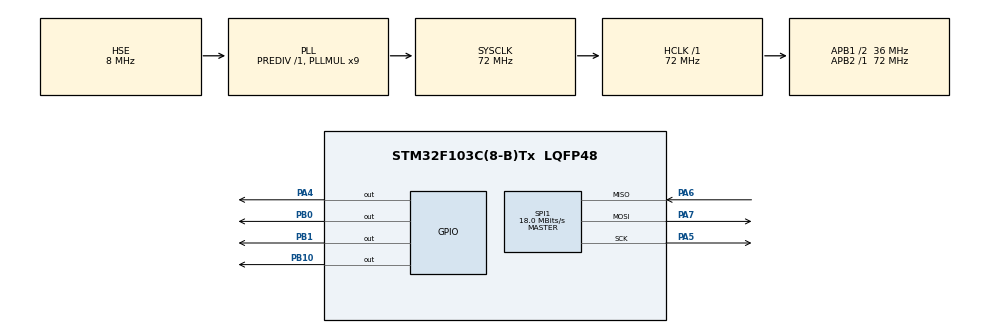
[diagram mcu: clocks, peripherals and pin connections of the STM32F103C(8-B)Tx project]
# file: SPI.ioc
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Dma.Request0=SPI1_TX
Dma.SPI1_TX.0.Direction=DMA_MEMORY_TO_PERIPH
Dma.SPI1_TX.0.Instance=DMA1_Channel3
Dma.SPI1_TX.0.MemDataAlignment=DMA_MDATAALIGN_BYTE
Dma.SPI1_TX.0.MemInc=DMA_MINC_ENABLE
Dma.SPI1_TX.0.Mode=DMA_NORMAL
Dma.SPI1_TX.0.PeriphDataAlignment=DMA_PDATAALIGN_BYTE
Dma.SPI1_TX.0.PeriphInc=DMA_PINC_DISABLE
Dma.SPI1_TX.0.Priority=DMA_PRIORITY_LOW
Mcu.Family=STM32F1
Mcu.Name=STM32F103C(8-B)Tx
Mcu.Package=LQFP48
NVIC.DMA1_Channel3_IRQn=true\:0\:0\:false\:false\:true\:false\:true\:true
NVIC.PriorityGroup=NVIC_PRIORITYGROUP_4
NVIC.SPI1_IRQn=true\:0\:0\:false\:false\:true\:true\:true\:true
PA13.Mode=Serial_Wire
PA13.Signal=SYS_JTMS-SWDIO
PA14.Mode=Serial_Wire
PA14.Signal=SYS_JTCK-SWCLK
PA4.Signal=GPIO_Output
PA5.Mode=Full_Duplex_Master
PA5.Signal=SPI1_SCK
PA6.Mode=Full_Duplex_Master
PA6.Signal=SPI1_MISO
PA7.Mode=Full_Duplex_Master
PA7.Signal=SPI1_MOSI
PB0.Signal=GPIO_Output
PB1.Signal=GPIO_Output
PB10.Signal=GPIO_Output
PC14-OSC32_IN.Mode=LSE-External-Oscillator
PC14-OSC32_IN.Signal=RCC_OSC32_IN
PC15-OSC32_OUT.Mode=LSE-External-Oscillator
PC15-OSC32_OUT.Signal=RCC_OSC32_OUT
PD0-OSC_IN.Mode=HSE-External-Oscillator
PD0-OSC_IN.Signal=RCC_OSC_IN
PD1-OSC_OUT.Mode=HSE-External-Oscillator
PD1-OSC_OUT.Signal=RCC_OSC_OUT
ProjectManager.HeapSize=0x200
ProjectManager.StackSize=0x400
ProjectManager.TargetToolchain=MDK-ARM V5.32
RCC.AHBFreq_Value=72000000
RCC.APB1CLKDivider=RCC_HCLK_DIV2
RCC.APB1Freq_Value=36000000
RCC.APB1TimFreq_Value=72000000
RCC.APB2Freq_Value=72000000
RCC.APB2TimFreq_Value=72000000
RCC.HCLKFreq_Value=72000000
RCC.PLLMUL=RCC_PLL_MUL9
RCC.PLLSourceVirtual=RCC_PLLSOURCE_HSE
RCC.SYSCLKFreq_VALUE=72000000
RCC.SYSCLKSource=RCC_SYSCLKSOURCE_PLLCLK
RCC.USBFreq_Value=72000000
SPI1.BaudRatePrescaler=SPI_BAUDRATEPRESCALER_4
SPI1.CalculateBaudRate=18.0 MBits/s
SPI1.Direction=SPI_DIRECTION_2LINES
SPI1.Mode=SPI_MODE_MASTER
SPI1.VirtualType=VM_MASTER
board=custom

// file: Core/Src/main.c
/* USER CODE BEGIN Header */
/**
  ******************************************************************************
  * @file           : main.c
  * @brief          : Main program body
  ******************************************************************************
  * @attention
  *
  * Copyright (c) 2026 STMicroelectronics.
  * All rights reserved.
  *
  * This software is licensed under terms that can be found in the LICENSE file
  * in the root directory of this software component.
  * If no LICENSE file comes with this software, it is provided AS-IS.
  *
  ******************************************************************************
  */
/* USER CODE END Header */
#include "main.h"

/* USER CODE BEGIN Includes */
#include <stdio.h>
#include <math.h>
#include <st7735.h>
/* USER CODE END Includes */

SPI_HandleTypeDef hspi1;
DMA_HandleTypeDef hdma_spi1_tx;

void SystemClock_Config(void);
static void MX_GPIO_Init(void);
static void MX_DMA_Init(void);
static void MX_SPI1_Init(void);

/* USER CODE BEGIN 0 */

// 80 x 106, 16960 bytes
// Pixel format: RGB565
// Algorithm: Floyd Steinberg
// Generated by img2lcd.com
static const unsigned char IMAGE[] = {
  0x2a, 0x50, 0x2a, 0x70, 0x2a, 0x70, 0x2a, 0x70, 0x2a, 0x70, 0x2a, 0x70, 0x2a, 0x70, 0x2a, 0x70,
  0x2a, 0x70, 0x2a, 0x70, 0x2a, 0x70, 0x2a, 0x70, 0x2a, 0x70, 0x2a, 0x70, 0x2a, 0x70, 0x2a, 0x70,
  0x2a, 0x70, 0x2a, 0x70, 0x2a, 0x70, 0x2a, 0x70, 0x2a, 0x70, 0x2a, 0x70, 0x2a, 0x70, 0x2a, 0x70,
  0x2a, 0x70, 0x2a, 0x70, 0x2a, 0x70, 0x2a, 0x70, 0x2a, 0x70, 0x2a, 0x70, 0x2a, 0x70, 0x2a, 0x70,
  0x2a, 0x70, 0x2a, 0x70, 0x2a, 0x70, 0x2a, 0x70, 0x2a, 0x70, 0x2a, 0x70, 0x2a, 0x70, 0x2a, 0x70,
  0x2a, 0x70, 0x2a, 0x70, 0x2a, 0x70, 0x2a, 0x70, 0x2a, 0x70, 0x2a, 0x70, 0x2a, 0x70, 0x2a, 0x70,
  0x2a, 0x70, 0x2a, 0x70, 0x2a, 0x70, 0x2a, 0x70, 0x2a, 0x70, 0x2a, 0x70, 0x2a, 0x70, 0x2a, 0x70,
  0x2a, 0x70, 0x2a, 0x70, 0x2a, 0x70, 0x2a, 0x70, 0x2a, 0x70, 0x2a, 0x70, 0x2a, 0x70, 0x2a, 0x70,
  0x2a, 0x70, 0x2a, 0x70, 0x2a, 0x70, 0x2a, 0x70, 0x2a, 0x70, 0x2a, 0x70, 0x2a, 0x70, 0x2a, 0x70,
  0x2a, 0x70, 0x2a, 0x70, 0x2a, 0x70, 0x2a, 0x70, 0x2a, 0x70, 0x2a, 0x70, 0x2a, 0x70, 0x2a, 0x70,
  0x2a, 0x70, 0x2a, 0x70, 0x2a, 0x70, 0x2a, 0x70, 0x2a, 0x70, 0x2a, 0x70, 0x2a, 0x70, 0x2a, 0x70,
  0x2a, 0x70, 0x2a, 0x70, 0x2a, 0x70, 0x2a, 0x70, 0x2a, 0x70, 0x2a, 0x70, 0x2a, 0x70, 0x2a, 0x70,
  0x2a, 0x70, 0x2a, 0x70, 0x2a, 0x70, 0x8c, 0xd7, 0x6c, 0x15, 0xff, 0xff, 0xff, 0xff, 0xff, 0xff,
  0xff, 0xff, 0xff, 0xff, 0xff, 0xff, 0xff, 0xff, 0xff, 0xff, 0xff, 0xff, 0xff, 0xff, 0xff, 0xff,
  0xff, 0xff, 0xff, 0xff, 0xff, 0xff, 0xff, 0xff, 0xff, 0xff, 0xff, 0xff, 0xff, 0xff, 0xff, 0xff,
  0xff, 0xff, 0xff, 0xff, 0xff, 0xff, 0xff, 0xff, 0xff, 0xff, 0xff, 0xff, 0xff, 0xff, 0xff, 0xff,
  0xff, 0xff, 0xff, 0xff, 0xff, 0xff, 0xff, 0xff, 0xff, 0xff, 0xff, 0xff, 0xff, 0xff, 0xff, 0xff,
  0xff, 0xff, 0xff, 0xff, 0xff, 0xff, 0xff, 0xff, 0xff, 0xff, 0xff, 0xff, 0xff, 0xff, 0xff, 0xff,
  0xff, 0xff, 0xff, 0xff, 0xff, 0xff, 0xff, 0xff, 0xff, 0xff, 0xff, 0xff, 0xff, 0xff, 0xff, 0xff,
  0xff, 0xff, 0xff, 0xff, 0xff, 0xff, 0xff, 0xff, 0xff, 0xff, 0xff, 0xff, 0xff, 0xff, 0xff, 0xff,
  0xff, 0xff, 0xff, 0xff, 0xff, 0xff, 0xff, 0xff, 0xff, 0xff, 0xff, 0xff, 0xff, 0xff, 0xff, 0xff,
  0xff, 0xff, 0xff, 0xff, 0xff, 0xff, 0xff, 0xff, 0xff, 0xff, 0xff, 0xff, 0xff, 0xff, 0xff, 0xff,
  0xff, 0xff, 0xff, 0xff, 0xff, 0xff, 0xff, 0xff, 0xff, 0xff, 0xff, 0xff, 0xff, 0xff, 0xff, 0xff,
  0xff, 0xff, 0xff, 0xff, 0xff, 0xff, 0xff, 0xff, 0xff, 0xff, 0xff, 0xff, 0xff, 0xff, 0xff, 0xff,
  0xff, 0xff, 0xff, 0xff, 0xff, 0xff, 0xff, 0xff, 0xff, 0xff, 0xff, 0xff, 0xff, 0xff, 0x84, 0xb6,
  0x6c, 0x15, 0xff, 0xff, 0xff, 0xff, 0xff, 0xff, 0xff, 0xff, 0xff, 0xff, 0xff, 0xff, 0xff, 0xff,
  0xff, 0xff, 0xff, 0xff, 0xff, 0xff, 0xff, 0xff, 0xff, 0xff, 0xff, 0xff, 0xff, 0xff, 0xff, 0xff,
  0xff, 0xff, 0xff, 0xff, 0xff, 0xff, 0xff, 0xff, 0xff, 0xff, 0xff, 0xff, 0xff, 0xff, 0xff, 0xff,
  0xff, 0xff, 0xff, 0xff, 0xff, 0xff, 0xff, 0xff, 0xff, 0xff, 0xff, 0xff, 0xff, 0xff, 0xff, 0xff,
  0xff, 0xff, 0xff, 0xff, 0xff, 0xff, 0xff, 0xff, 0xff, 0xff, 0xff, 0xff, 0xff, 0xff, 0xff, 0xff,
  0xff, 0xff, 0xff, 0xff, 0xff, 0xff, 0xff, 0xff, 0xff, 0xff, 0xff, 0xff, 0xff, 0xff, 0xff, 0xff,
  0xff, 0xff, 0xff, 0xff, 0xff, 0xff, 0xff, 0xff, 0xff, 0xff, 0xff, 0xff, 0xff, 0xff, 0xff, 0xff,
  0xff, 0xff, 0xff, 0xff, 0xff, 0xff, 0xff, 0xff, 0xff, 0xff, 0xff, 0xff, 0xff, 0xff, 0xff, 0xff,
  0xff, 0xff, 0xff, 0xff, 0xff, 0xff, 0xff, 0xff, 0xff, 0xff, 0xff, 0xff, 0xff, 0xff, 0xff, 0xff,
  0xff, 0xff, 0xff, 0xff, 0xff, 0xff, 0xff, 0xff, 0xff, 0xff, 0xff, 0xff, 0xff, 0xff, 0xff, 0xff,
  0xff, 0xff, 0xff, 0xff, 0xff, 0xff, 0xff, 0xff, 0xff, 0xff, 0xff, 0xff, 0xff, 0xff, 0xff, 0xff,
  0xff, 0xff, 0xff, 0xff, 0xff, 0xff, 0xff, 0xff, 0xff, 0xff, 0xff, 0xff, 0xff, 0xff, 0xff, 0xff,
  0xff, 0xff, 0xff, 0xff, 0xff, 0xff, 0x84, 0xb6, 0x6c, 0x15, 0xff, 0xff, 0xff, 0xff, 0x10, 0x82,
  0x10, 0x82, 0x10, 0x82, 0x10, 0x82, 0x10, 0x82, 0x10, 0x82, 0x10, 0x82, 0x10, 0x82, 0x10, 0x82,
  0x10, 0x82, 0x10, 0x82, 0x10, 0x82, 0x10, 0x82, 0x10, 0x82, 0x10, 0x82, 0x10, 0x82, 0x10, 0x82,
  0x10, 0x82, 0x10, 0x82, 0x29, 0x65, 0xff, 0xff, 0xff, 0xff, 0xff, 0xff, 0xff, 0xff, 0xff, 0xff,
  0x6b, 0x6d, 0x10, 0x82, 0x10, 0x82, 0xf7, 0xbe, 0xff, 0xff, 0xff, 0xff, 0xff, 0xff, 0xff, 0xff,
  0xff, 0xff, 0x10, 0x82, 0x10, 0x82, 0x21, 0x24, 0xff, 0xff, 0xff, 0xff, 0x73, 0x8e, 0x10, 0x82,
  0x10, 0x82, 0xd6, 0xba, 0xff, 0xff, 0xff, 0xff, 0xff, 0xff, 0xff, 0xff, 0xff, 0xff, 0xff, 0xff,
  0xff, 0xff, 0xff, 0xff, 0xff, 0xff, 0xff, 0xff, 0xff, 0xff, 0xff, 0xff, 0xff, 0xff, 0xff, 0xff,
  0xff, 0xff, 0xff, 0xff, 0xff, 0xff, 0xff, 0xff, 0xff, 0xff, 0x10, 0x82, 0x10, 0x82, 0x10, 0x82,
  0x10, 0x82, 0x10, 0x82, 0x31, 0xa6, 0xff, 0xff, 0xff, 0xff, 0xff, 0xff, 0xff, 0xff, 0xff, 0xff,
  0x63, 0x0c, 0x10, 0x82, 0x10, 0x82, 0x10, 0x82, 0x10, 0x82, 0x10, 0x82, 0x10, 0x82, 0x10, 0x82,
  0x10, 0x82, 0x10, 0x82, 0x10, 0x82, 0x10, 0x82, 0x10, 0x82, 0x10, 0x82, 0x10, 0x82, 0x10, 0x82,
  0x10, 0x82, 0x10, 0x82, 0x10, 0x82, 0x10, 0x82, 0xff, 0xdf, 0xff, 0xff, 0xff, 0xff, 0x84, 0xb6,
  0x6c, 0x15, 0xff, 0xff, 0xff, 0xff, 0x00, 0x00, 0x00, 0x00, 0x00, 0x00, 0x00, 0x00, 0x00, 0x00,
  0x00, 0x00, 0x00, 0x00, 0x00, 0x00, 0x00, 0x00, 0x00, 0x00, 0x00, 0x00, 0x00, 0x00, 0x00, 0x00,
  0x00, 0x00, 0x00, 0x00, 0x00, 0x00, 0x00, 0x00, 0x00, 0x00, 0x00, 0x00, 0x18, 0xe3, 0xff, 0xff,
  0xff, 0xff, 0xff, 0xff, 0xff, 0xff, 0xff, 0xff, 0x63, 0x0c, 0x00, 0x00, 0x00, 0x00, 0xf7, 0x9e,
  0xff, 0xff, 0xff, 0xff, 0xff, 0xff, 0xff, 0xff, 0xff, 0xff, 0x00, 0x00, 0x00, 0x00, 0x18, 0xc3,
  0xff, 0xff, 0xff, 0xff, 0x63, 0x2c, 0x00, 0x00, 0x00, 0x00, 0xd6, 0x9a, 0xff, 0xff, 0xff, 0xff,
  0xff, 0xff, 0xff, 0xff, 0xff, 0xff, 0xff, 0xff, 0xff, 0xff, 0xff, 0xff, 0xff, 0xff, 0xff, 0xff,
  0xff, 0xff, 0xff, 0xff, 0xff, 0xff, 0xff, 0xff, 0xff, 0xff, 0xff, 0xff, 0xff, 0xff, 0xff, 0xff,
  0xff, 0xff, 0x00, 0x00, 0x00, 0x00, 0x00, 0x00, 0x00, 0x00, 0x00, 0x00, 0x21, 0x24, 0xff, 0xff,
  0xff, 0xff, 0xff, 0xff, 0xff, 0xff, 0xff, 0xff, 0x52, 0xaa, 0x00, 0x00, 0x00, 0x00, 0x00, 0x00,
  0x00, 0x00, 0x00, 0x00, 0x00, 0x00, 0x00, 0x00, 0x00, 0x00, 0x00, 0x00, 0x00, 0x00, 0x00, 0x00,
  0x00, 0x00, 0x00, 0x00, 0x00, 0x00, 0x00, 0x00, 0x00, 0x00, 0x00, 0x00, 0x00, 0x00, 0x00, 0x00,
  0xff, 0xdf, 0xff, 0xff, 0xff, 0xff, 0x84, 0xb6, 0x6c, 0x15, 0xff, 0xff, 0xff, 0xff, 0x00, 0x00,
  0x00, 0x00, 0x00, 0x00, 0x00, 0x00, 0x00, 0x00, 0x00, 0x00, 0x00, 0x00, 0x00, 0x00, 0x00, 0x00,
  0x00, 0x00, 0x00, 0x00, 0x00, 0x00, 0x00, 0x00, 0x00, 0x00, 0x00, 0x00, 0x00, 0x00, 0x00, 0x00,
  0x00, 0x00, 0x00, 0x00, 0x18, 0xe3, 0xff, 0xff, 0xff, 0xff, 0xff, 0xff, 0xff, 0xff, 0xff, 0xff,
  0x63, 0x0c, 0x00, 0x00, 0x00, 0x00, 0xf7, 0x9e, 0xff, 0xff, 0xff, 0xff, 0xff, 0xff, 0xff, 0xff,
  0xff, 0xff, 0x00, 0x00, 0x00, 0x00, 0x18, 0xc3, 0xff, 0xff, 0xff, 0xff, 0x63, 0x2c, 0x00, 0x00,
  0x00, 0x00, 0xd6, 0x9a, 0xff, 0xff, 0xff, 0xff, 0xff, 0xff, 0xff, 0xff, 0xff, 0xff, 0xff, 0xff,
  0xff, 0xff, 0xff, 0xff, 0xff, 0xff, 0xff, 0xff, 0xff, 0xff, 0xff, 0xff, 0xff, 0xff, 0xff, 0xff,
  0xff, 0xff, 0xff, 0xff, 0xff, 0xff, 0xff, 0xff, 0xff, 0xff, 0x00, 0x00, 0x00, 0x00, 0x00, 0x00,
  0x00, 0x00, 0x00, 0x00, 0x21, 0x24, 0xff, 0xff, 0xff, 0xff, 0xff, 0xff, 0xff, 0xff, 0xff, 0xff,
  0x52, 0xaa, 0x00, 0x00, 0x00, 0x00, 0x00, 0x00, 0x00, 0x00, 0x00, 0x00, 0x00, 0x00, 0x00, 0x00,
  0x00, 0x00, 0x00, 0x00, 0x00, 0x00, 0x00, 0x00, 0x00, 0x00, 0x00, 0x00, 0x00, 0x00, 0x00, 0x00,
  0x00, 0x00, 0x00, 0x00, 0x00, 0x00, 0x00, 0x00, 0xff, 0xdf, 0xff, 0xff, 0xff, 0xff, 0x84, 0xb6,
  0x6c, 0x15, 0xff, 0xff, 0xff, 0xff, 0x00, 0x00, 0x00, 0x00, 0x08, 0x41, 0xff, 0xff, 0xff, 0xff,
  0xff, 0xff, 0xff, 0xff, 0xff, 0xff, 0xff, 0xff, 0xff, 0xff, 0xff, 0xff, 0xff, 0xff, 0xff, 0xff,
  0xff, 0xff, 0xff, 0xff, 0xff, 0xff, 0xff, 0xff, 0x00, 0x00, 0x00, 0x00, 0x18, 0xe3, 0xff, 0xff,
  0xff, 0xff, 0xff, 0xff, 0xff, 0xff, 0xff, 0xff, 0xff, 0xff, 0xff, 0xff, 0xff, 0xff, 0x08, 0x61,
  0x00, 0x00, 0x00, 0x00, 0x00, 0x00, 0x00, 0x00, 0x00, 0x00, 0x00, 0x00, 0x00, 0x00, 0x00, 0x00,
  0x00, 0x00, 0x00, 0x00, 0x00, 0x00, 0x00, 0x00, 0x00, 0x00, 0xd6, 0x9a, 0xff, 0xff, 0xff, 0xff,
  0x00, 0x20, 0x00, 0x00, 0x00, 0x00, 0xff, 0xff, 0xff, 0xff, 0xf7, 0xbe, 0x00, 0x00, 0x00, 0x00,
  0x00, 0x00, 0x00, 0x00, 0x00, 0x00, 0x9c, 0xf3, 0xff, 0xff, 0xff, 0xff, 0x10, 0x82, 0x00, 0x00,
  0x00, 0x00, 0xff, 0xff, 0xff, 0xff, 0xff, 0xff, 0xff, 0xff, 0xff, 0xff, 0xff, 0xff, 0xff, 0xff,
  0xff, 0xff, 0xff, 0xff, 0xff, 0xff, 0xff, 0xff, 0x52, 0xaa, 0x00, 0x00, 0x00, 0x00, 0xf7, 0x9e,
  0xff, 0xff, 0xff, 0xff, 0xff, 0xff, 0xff, 0xff, 0xff, 0xff, 0xff, 0xff, 0xff, 0xff, 0xff, 0xff,
  0xff, 0xff, 0xff, 0xff, 0xff, 0xff, 0xff, 0xff, 0xff, 0xff, 0x29, 0x45, 0x00, 0x00, 0x00, 0x00,
  0xff, 0xdf, 0xff, 0xff, 0xff, 0xff, 0x84, 0xb6, 0x6c, 0x15, 0xff, 0xff, 0xff, 0xff, 0x00, 0x00,
  0x00, 0x00, 0x08, 0x41, 0xff, 0xff, 0xff, 0xff, 0xff, 0xff, 0xff, 0xff, 0xff, 0xff, 0xff, 0xff,
  0xff, 0xff, 0xff, 0xff, 0xff, 0xff, 0xff, 0xff, 0xff, 0xff, 0xff, 0xff, 0xff, 0xff, 0xff, 0xff,
  0x00, 0x00, 0x00, 0x00, 0x18, 0xe3, 0xff, 0xff, 0xff, 0xff, 0xff, 0xff, 0xff, 0xff, 0xff, 0xff,
  0xff, 0xff, 0xff, 0xff, 0xff, 0xff, 0x08, 0x61, 0x00, 0x00, 0x00, 0x00, 0x00, 0x00, 0x00, 0x00,
  0x00, 0x00, 0x00, 0x00, 0x00, 0x00, 0x00, 0x00, 0x00, 0x00, 0x00, 0x00, 0x00, 0x00, 0x00, 0x00,
  0x00, 0x00, 0xd6, 0x9a, 0xff, 0xff, 0xff, 0xff, 0x00, 0x20, 0x00, 0x00, 0x00, 0x00, 0xff, 0xff,
  0xff, 0xff, 0xf7, 0xbe, 0x00, 0x00, 0x00, 0x00, 0x00, 0x00, 0x00, 0x00, 0x00, 0x00, 0x9c, 0xf3,
  0xff, 0xff, 0xff, 0xff, 0x10, 0x82, 0x00, 0x00, 0x00, 0x00, 0xff, 0xff, 0xff, 0xff, 0xff, 0xff,
  0xff, 0xff, 0xff, 0xff, 0xff, 0xff, 0xff, 0xff, 0xff, 0xff, 0xff, 0xff, 0xff, 0xff, 0xff, 0xff,
  0x52, 0xaa, 0x00, 0x00, 0x00, 0x00, 0xf7, 0x9e, 0xff, 0xff, 0xff, 0xff, 0xff, 0xff, 0xff, 0xff,
  0xff, 0xff, 0xff, 0xff, 0xff, 0xff, 0xff, 0xff, 0xff, 0xff, 0xff, 0xff, 0xff, 0xff, 0xff, 0xff,
  0xff, 0xff, 0x29, 0x45, 0x00, 0x00, 0x00, 0x00, 0xff, 0xdf, 0xff, 0xff, 0xff, 0xff, 0x84, 0xb6,
  0x6c, 0x15, 0xff, 0xff, 0xff, 0xff, 0x00, 0x00, 0x00, 0x00, 0x08, 0x41, 0xff, 0xff, 0xff, 0xff,
  0xff, 0xff, 0xff, 0xdf, 0xff, 0xdf, 0xff, 0xdf, 0xff, 0xdf, 0xff, 0xdf, 0xff, 0xdf, 0xff, 0xdf,
  0xff, 0xdf, 0xff, 0xff, 0xff, 0xff, 0xff, 0xff, 0x00, 0x00, 0x00, 0x00, 0x18, 0xe3, 0xff, 0xff,
  0xff, 0xff, 0xff, 0xff, 0xff, 0xdf, 0xff, 0xdf, 0xff, 0xdf, 0xff, 0xdf, 0xff, 0xdf, 0x08, 0x61,
  0x00, 0x00, 0x00, 0x00, 0x00, 0x00, 0x00, 0x00, 0x00, 0x00, 0x00, 0x00, 0x00, 0x00, 0x00, 0x00,
  0x00, 0x00, 0x00, 0x00, 0x00, 0x00, 0x00, 0x00, 0x00, 0x00, 0xd6, 0x9a, 0xff, 0xff, 0xff, 0xff,
  0x00, 0x20, 0x00, 0x00, 0x00, 0x00, 0xff, 0xdf, 0xff, 0xdf, 0xf7, 0x9e, 0x00, 0x00, 0x00, 0x00,
  0x00, 0x00, 0x00, 0x00, 0x00, 0x00, 0x9c, 0xd3, 0xff, 0xdf, 0xff, 0xdf, 0x10, 0xa2, 0x00, 0x00,
  0x00, 0x00, 0xff, 0xdf, 0xff, 0xdf, 0xff, 0xdf, 0xff, 0xff, 0xff, 0xff, 0xff, 0xff, 0xff, 0xff,
  0xff, 0xff, 0xff, 0xff, 0xff, 0xff, 0xff, 0xff, 0x52, 0xaa, 0x00, 0x00, 0x00, 0x00, 0xf7, 0x9e,
  0xff, 0xff, 0xff, 0xff, 0xff, 0xdf, 0xff, 0xdf, 0xff, 0xdf, 0xff, 0xdf, 0xff, 0xdf, 0xff, 0xdf,
  0xff, 0xdf, 0xff, 0xdf, 0xff, 0xff, 0xff, 0xff, 0xff, 0xff, 0x29, 0x45, 0x00, 0x00, 0x00, 0x00,
  0xff, 0xdf, 0xff, 0xff, 0xff, 0xff, 0x84, 0xb6, 0x6c, 0x15, 0xff, 0xff, 0xff, 0xff, 0x00, 0x00,
  0x00, 0x00, 0x08, 0x41, 0xff, 0xff, 0xff, 0xff, 0xde, 0xfb, 0x00, 0x00, 0x00, 0x00, 0x00, 0x00,
  0x00, 0x00, 0x00, 0x00, 0x00, 0x00, 0x00, 0x00, 0x00, 0x00, 0xff, 0xdf, 0xff, 0xff, 0xff, 0xff,
  0x00, 0x00, 0x00, 0x00, 0x18, 0xe3, 0xff, 0xff, 0xff, 0xff, 0x8c, 0x51, 0x00, 0x00, 0x00, 0x00,
  0x00, 0x00, 0x00, 0x00, 0x00, 0x00, 0x00, 0x00, 0x00, 0x00, 0x00, 0x00, 0xff, 0xdf, 0xff, 0xff,
  0xff, 0xff, 0x00, 0x00, 0x00, 0x00, 0x00, 0x00, 0x00, 0x00, 0x00, 0x00, 0x94, 0xb2, 0xff, 0xff,
  0xff, 0xff, 0xff, 0xff, 0xff, 0xff, 0xff, 0xff, 0x00, 0x20, 0x00, 0x00, 0x00, 0x00, 0x00, 0x00,
  0x00, 0x00, 0x00, 0x00, 0x00, 0x00, 0x00, 0x00, 0x00, 0x00, 0x00, 0x00, 0x00, 0x00, 0x00, 0x00,
  0x00, 0x00, 0x00, 0x00, 0xef, 0x5d, 0xff, 0xff, 0xff, 0xff, 0x00, 0x00, 0x00, 0x00, 0x00, 0x20,
  0xff, 0xff, 0xff, 0xff, 0xff, 0xff, 0xff, 0xff, 0xff, 0xff, 0xff, 0xff, 0xff, 0xff, 0xff, 0xff,
  0x52, 0xaa, 0x00, 0x00, 0x00, 0x00, 0xf7, 0x9e, 0xff, 0xff, 0xff, 0xff, 0x00, 0x00, 0x00, 0x00,
  0x00, 0x00, 0x00, 0x00, 0x00, 0x00, 0x00, 0x00, 0x00, 0x00, 0x00, 0x00, 0xa5, 0x34, 0xff, 0xff,
  0xff, 0xff, 0x29, 0x45, 0x00, 0x00, 0x00, 0x00, 0xff, 0xdf, 0xff, 0xff, 0xff, 0xff, 0x84, 0xb6,
  0x6c, 0x15, 0xff, 0xff, 0xff, 0xff, 0x00, 0x00, 0x00, 0x00, 0x08, 0x41, 0xff, 0xff, 0xff, 0xff,
  0xde, 0xfb, 0x00, 0x00, 0x00, 0x00, 0x00, 0x00, 0x00, 0x00, 0x00, 0x00, 0x00, 0x00, 0x00, 0x00,
  0x00, 0x00, 0xff, 0xdf, 0xff, 0xff, 0xff, 0xff, 0x00, 0x00, 0x00, 0x00, 0x18, 0xe3, 0xff, 0xff,
  0xff, 0xff, 0x8c, 0x51, 0x00, 0x00, 0x00, 0x00, 0x00, 0x00, 0x00, 0x00, 0x00, 0x00, 0x00, 0x00,
  0x00, 0x00, 0x00, 0x00, 0xff, 0xdf, 0xff, 0xff, 0xff, 0xff, 0x00, 0x00, 0x00, 0x00, 0x00, 0x00,
  0x00, 0x00, 0x00, 0x00, 0x94, 0xb2, 0xff, 0xff, 0xff, 0xff, 0xff, 0xff, 0xff, 0xff, 0xff, 0xff,
  0x00, 0x20, 0x00, 0x00, 0x00, 0x00, 0x00, 0x00, 0x00, 0x00, 0x00, 0x00, 0x00, 0x00, 0x00, 0x00,
  0x00, 0x00, 0x00, 0x00, 0x00, 0x00, 0x00, 0x00, 0x00, 0x00, 0x00, 0x00, 0xef, 0x5d, 0xff, 0xff,
  0xff, 0xff, 0x00, 0x00, 0x00, 0x00, 0x00, 0x20, 0xff, 0xff, 0xff, 0xff, 0xff, 0xff, 0xff, 0xff,
  0xff, 0xff, 0xff, 0xff, 0xff, 0xff, 0xff, 0xff, 0x52, 0xaa, 0x00, 0x00, 0x00, 0x00, 0xf7, 0x9e,
  0xff, 0xff, 0xff, 0xff, 0x00, 0x00, 0x00, 0x00, 0x00, 0x00, 0x00, 0x00, 0x00, 0x00, 0x00, 0x00,
  0x00, 0x00, 0x00, 0x00, 0xa5, 0x34, 0xff, 0xff, 0xff, 0xff, 0x29, 0x45, 0x00, 0x00, 0x00, 0x00,
  0xff, 0xdf, 0xff, 0xff, 0xff, 0xff, 0x84, 0xb6, 0x6c, 0x15, 0xff, 0xff, 0xff, 0xff, 0x00, 0x00,
  0x00, 0x00, 0x08, 0x41, 0xff, 0xff, 0xff, 0xff, 0xde, 0xfb, 0x00, 0x00, 0x00, 0x00, 0x00, 0x00,
  0x00, 0x00, 0x00, 0x00, 0x00, 0x00, 0x00, 0x00, 0x00, 0x00, 0xff, 0xdf, 0xff, 0xff, 0xff, 0xff,
  0x00, 0x00, 0x00, 0x00, 0x18, 0xe3, 0xff, 0xff, 0xff, 0xff, 0x94, 0xb2, 0x18, 0xc3, 0x18, 0xc3,
  0x08, 0x41, 0x00, 0x00, 0x00, 0x00, 0x00, 0x00, 0x00, 0x00, 0x00, 0x00, 0xde, 0xfb, 0xe7, 0x3c,
  0xe7, 0x3c, 0x18, 0xc3, 0x18, 0xc3, 0x18, 0xc3, 0x00, 0x00, 0x00, 0x00, 0x84, 0x30, 0xe7, 0x3c,
  0xe7, 0x1c, 0xe7, 0x3c, 0xe7, 0x3c, 0xe7, 0x3c, 0x18, 0xe3, 0x18, 0xc3, 0x18, 0xc3, 0x18, 0xc3,
  0x18, 0xc3, 0x18, 0xc3, 0x18, 0xc3, 0x18, 0xc3, 0x10, 0xa2, 0x00, 0x00, 0x00, 0x00, 0x10, 0x82,
  0x18, 0xc3, 0x18, 0xc3, 0xd6, 0x9a, 0xe7, 0x1c, 0xe7, 0x3c, 0x18, 0xc3, 0x18, 0xc3, 0x21, 0x04,
  0xff, 0xff, 0xff, 0xff, 0xff, 0xff, 0xff, 0xff, 0xff, 0xff, 0xff, 0xff, 0xff, 0xff, 0xff, 0xff,
  0x52, 0xaa, 0x00, 0x00, 0x00, 0x00, 0xf7, 0x9e, 0xff, 0xff, 0xff, 0xff, 0x00, 0x00, 0x00, 0x00,
  0x00, 0x00, 0x00, 0x00, 0x00, 0x00, 0x00, 0x00, 0x00, 0x00, 0x00, 0x00, 0xa5, 0x34, 0xff, 0xff,
  0xff, 0xff, 0x29, 0x45, 0x00, 0x00, 0x00, 0x00, 0xff, 0xdf, 0xff, 0xff, 0xff, 0xff, 0x84, 0xb6,
  0x6c, 0x15, 0xff, 0xff, 0xff, 0xff, 0x00, 0x00, 0x00, 0x00, 0x08, 0x41, 0xff, 0xff, 0xff, 0xff,
  0xde, 0xfb, 0x00, 0x00, 0x00, 0x00, 0x00, 0x00, 0x00, 0x00, 0x00, 0x00, 0x00, 0x00, 0x00, 0x00,
  0x00, 0x00, 0xff, 0xdf, 0xff, 0xff, 0xff, 0xff, 0x00, 0x00, 0x00, 0x00, 0x18, 0xe3, 0xff, 0xff,
  0xff, 0xff, 0xff, 0xff, 0xff, 0xff, 0xff, 0xff, 0x63, 0x0c, 0x00, 0x00, 0x00, 0x00, 0x00, 0x00,
  0x00, 0x00, 0x00, 0x00, 0x00, 0x00, 0x00, 0x00, 0x00, 0x00, 0xff, 0xff, 0xff, 0xff, 0xe7, 0x3c,
  0x00, 0x00, 0x00, 0x00, 0x00, 0x00, 0x00, 0x00, 0x00, 0x00, 0x00, 0x00, 0x00, 0x00, 0x00, 0x00,
  0xff, 0xdf, 0xff, 0xff, 0xff, 0xff, 0xff, 0xff, 0xff, 0xff, 0xff, 0xff, 0xff, 0xff, 0xff, 0xff,
  0xce, 0x59, 0x00, 0x00, 0x00, 0x00, 0x9c, 0xf3, 0xff, 0xff, 0xff, 0xff, 0x10, 0x82, 0x00, 0x00,
  0x00, 0x00, 0xff, 0xff, 0xff, 0xff, 0xff, 0xff, 0xff, 0xff, 0xff, 0xff, 0xff, 0xff, 0xff, 0xff,
  0xff, 0xff, 0xff, 0xff, 0xff, 0xff, 0xff, 0xff, 0x52, 0xaa, 0x00, 0x00, 0x00, 0x00, 0xf7, 0x9e,
  0xff, 0xff, 0xff, 0xff, 0x00, 0x00, 0x00, 0x00, 0x00, 0x00, 0x00, 0x00, 0x00, 0x00, 0x00, 0x00,
  0x00, 0x00, 0x00, 0x00, 0xa5, 0x34, 0xff, 0xff, 0xff, 0xff, 0x29, 0x45, 0x00, 0x00, 0x00, 0x00,
  0xff, 0xdf, 0xff, 0xff, 0xff, 0xff, 0x84, 0xb6, 0x6c, 0x15, 0xff, 0xff, 0xff, 0xff, 0x00, 0x00,
  0x00, 0x00, 0x08, 0x41, 0xff, 0xff, 0xff, 0xff, 0xde, 0xfb, 0x00, 0x00, 0x00, 0x00, 0x00, 0x00,
  0x00, 0x00, 0x00, 0x00, 0x00, 0x00, 0x00, 0x00, 0x00, 0x00, 0xff, 0xdf, 0xff, 0xff, 0xff, 0xff,
  0x00, 0x00, 0x00, 0x00, 0x18, 0xe3, 0xff, 0xff, 0xff, 0xff, 0xff, 0xff, 0xff, 0xff, 0xff, 0xff,
  0x63, 0x0c, 0x00, 0x00, 0x00, 0x00, 0x00, 0x00, 0x00, 0x00, 0x00, 0x00, 0x00, 0x00, 0x00, 0x00,
  0x00, 0x00, 0xff, 0xff, 0xff, 0xff, 0xe7, 0x3c, 0x00, 0x00, 0x00, 0x00, 0x00, 0x00, 0x00, 0x00,
  0x00, 0x00, 0x00, 0x00, 0x00, 0x00, 0x00, 0x00, 0xff, 0xdf, 0xff, 0xff, 0xff, 0xff, 0xff, 0xff,
  0xff, 0xff, 0xff, 0xff, 0xff, 0xff, 0xff, 0xff, 0xce, 0x59, 0x00, 0x00, 0x00, 0x00, 0x9c, 0xf3,
  0xff, 0xff, 0xff, 0xff, 0x10, 0x82, 0x00, 0x00, 0x00, 0x00, 0xff, 0xff, 0xff, 0xff, 0xff, 0xff,
  0xff, 0xff, 0xff, 0xff, 0xff, 0xff, 0xff, 0xff, 0xff, 0xff, 0xff, 0xff, 0xff, 0xff, 0xff, 0xff,
  0x52, 0xaa, 0x00, 0x00, 0x00, 0x00, 0xf7, 0x9e, 0xff, 0xff, 0xff, 0xff, 0x00, 0x00, 0x00, 0x00,
  0x00, 0x00, 0x00, 0x00, 0x00, 0x00, 0x00, 0x00, 0x00, 0x00, 0x00, 0x00, 0xa5, 0x34, 0xff, 0xff,
  0xff, 0xff, 0x29, 0x45, 0x00, 0x00, 0x00, 0x00, 0xff, 0xdf, 0xff, 0xff, 0xff, 0xff, 0x84, 0xb6,
  0x6c, 0x15, 0xff, 0xff, 0xff, 0xff, 0x00, 0x00, 0x00, 0x00, 0x08, 0x41, 0xff, 0xff, 0xff, 0xff,
  0xde, 0xfb, 0x00, 0x00, 0x00, 0x00, 0x00, 0x00, 0x00, 0x00, 0x00, 0x00, 0x00, 0x00, 0x00, 0x00,
  0x00, 0x00, 0xff, 0xdf, 0xff, 0xff, 0xff, 0xff, 0x00, 0x00, 0x00, 0x00, 0x18, 0xe3, 0xff, 0xff,
  0xff, 0xff, 0xff, 0xff, 0xff, 0xff, 0xff, 0xff, 0x94, 0x92, 0x4a, 0x69, 0x4a, 0x69, 0x00, 0x20,
  0x00, 0x00, 0x00, 0x00, 0x4a, 0x49, 0x4a, 0x69, 0x4a, 0x69, 0xff, 0xff, 0xff, 0xff, 0xe7, 0x3c,
  0x00, 0x00, 0x00, 0x00, 0x00, 0x00, 0x00, 0x00, 0x00, 0x00, 0x00, 0x00, 0x00, 0x00, 0x00, 0x00,
  0xad, 0x75, 0xb5, 0x96, 0xb5, 0x96, 0xff, 0xff, 0xff, 0xff, 0xff, 0xff, 0xff, 0xff, 0xff, 0xff,
  0xce, 0x59, 0x00, 0x00, 0x00, 0x00, 0x6b, 0x6d, 0xb5, 0x96, 0xb5, 0x96, 0x52, 0x8a, 0x4a, 0x69,
  0x4a, 0x69, 0xb5, 0x96, 0xb5, 0x96, 0xb5, 0xb6, 0xff, 0xff, 0xff, 0xff, 0xf7, 0x9e, 0xb5, 0x96,
  0xb5, 0x96, 0xd6, 0x9a, 0xff, 0xff, 0xff, 0xff, 0x52, 0xaa, 0x00, 0x00, 0x00, 0x00, 0xf7, 0x9e,
  0xff, 0xff, 0xff, 0xff, 0x00, 0x00, 0x00, 0x00, 0x00, 0x00, 0x00, 0x00, 0x00, 0x00, 0x00, 0x00,
  0x00, 0x00, 0x00, 0x00, 0xa5, 0x34, 0xff, 0xff, 0xff, 0xff, 0x29, 0x45, 0x00, 0x00, 0x00, 0x00,
  0xff, 0xdf, 0xff, 0xff, 0xff, 0xff, 0x84, 0xb6, 0x6c, 0x15, 0xff, 0xff, 0xff, 0xff, 0x00, 0x00,
  0x00, 0x00, 0x08, 0x41, 0xff, 0xff, 0xff, 0xff, 0xde, 0xfb, 0x00, 0x00, 0x00, 0x00, 0x00, 0x00,
  0x00, 0x00, 0x00, 0x00, 0x00, 0x00, 0x00, 0x00, 0x00, 0x00, 0xff, 0xdf, 0xff, 0xff, 0xff, 0xff,
  0x00, 0x00, 0x00, 0x00, 0x18, 0xe3, 0xff, 0xff, 0xff, 0xff, 0xff, 0xff, 0xff, 0xff, 0xff, 0xff,
  0xff, 0xff, 0xff, 0xff, 0xff, 0xff, 0x08, 0x61, 0x00, 0x00, 0x00, 0x00, 0xff, 0xdf, 0xff, 0xff,
  0xff, 0xff, 0xff, 0xff, 0xff, 0xff, 0xe7, 0x3c, 0x00, 0x00, 0x00, 0x00, 0x00, 0x00, 0x00, 0x00,
  0x00, 0x00, 0x00, 0x00, 0x00, 0x00, 0x00, 0x00, 0x00, 0x00, 0x00, 0x00, 0x00, 0x00, 0xff, 0xff,
  0xff, 0xff, 0xff, 0xff, 0xff, 0xff, 0xff, 0xff, 0xce, 0x59, 0x00, 0x00, 0x00, 0x00, 0x00, 0x00,
  0x00, 0x00, 0x00, 0x00, 0xef, 0x5d, 0xff, 0xff, 0xff, 0xff, 0x00, 0x00, 0x00, 0x00, 0x00, 0x20,
  0xff, 0xff, 0xff, 0xff, 0xde, 0xdb, 0x00, 0x00, 0x00, 0x00, 0x6b, 0x6d, 0xff, 0xff, 0xff, 0xff,
  0x52, 0xaa, 0x00, 0x00, 0x00, 0x00, 0xf7, 0x9e, 0xff, 0xff, 0xff, 0xff, 0x00, 0x00, 0x00, 0x00,
  0x00, 0x00, 0x00, 0x00, 0x00, 0x00, 0x00, 0x00, 0x00, 0x00, 0x00, 0x00, 0xa5, 0x34, 0xff, 0xff,
  0xff, 0xff, 0x29, 0x45, 0x00, 0x00, 0x00, 0x00, 0xff, 0xdf, 0xff, 0xff, 0xff, 0xff, 0x84, 0xb6,
  0x6c, 0x15, 0xff, 0xff, 0xff, 0xff, 0x00, 0x00, 0x00, 0x00, 0x08, 0x41, 0xff, 0xff, 0xff, 0xff,
  0xde, 0xfb, 0x00, 0x00, 0x00, 0x00, 0x00, 0x00, 0x00, 0x00, 0x00, 0x00, 0x00, 0x00, 0x00, 0x00,
  0x00, 0x00, 0xff, 0xdf, 0xff, 0xff, 0xff, 0xff, 0x00, 0x00, 0x00, 0x00, 0x18, 0xe3, 0xff, 0xff,
  0xff, 0xff, 0xff, 0xff, 0xff, 0xff, 0xff, 0xff, 0xff, 0xff, 0xff, 0xff, 0xff, 0xff, 0x08, 0x61,
  0x00, 0x00, 0x00, 0x00, 0xff, 0xdf, 0xff, 0xff, 0xff, 0xff, 0xff, 0xff, 0xff, 0xff, 0xe7, 0x3c,
  0x00, 0x00, 0x00, 0x00, 0x00, 0x00, 0x00, 0x00, 0x00, 0x00, 0x00, 0x00, 0x00, 0x00, 0x00, 0x00,
  0x00, 0x00, 0x00, 0x00, 0x00, 0x00, 0xff, 0xff, 0xff, 0xff, 0xff, 0xff, 0xff, 0xff, 0xff, 0xff,
  0xce, 0x59, 0x00, 0x00, 0x00, 0x00, 0x00, 0x00, 0x00, 0x00, 0x00, 0x00, 0xef, 0x5d, 0xff, 0xff,
  0xff, 0xff, 0x00, 0x00, 0x00, 0x00, 0x00, 0x20, 0xff, 0xff, 0xff, 0xff, 0xde, 0xdb, 0x00, 0x00,
  0x00, 0x00, 0x6b, 0x6d, 0xff, 0xff, 0xff, 0xff, 0x52, 0xaa, 0x00, 0x00, 0x00, 0x00, 0xf7, 0x9e,
  0xff, 0xff, 0xff, 0xff, 0x00, 0x00, 0x00, 0x00, 0x00, 0x00, 0x00, 0x00, 0x00, 0x00, 0x00, 0x00,
  0x00, 0x00, 0x00, 0x00, 0xa5, 0x34, 0xff, 0xff, 0xff, 0xff, 0x29, 0x45, 0x00, 0x00, 0x00, 0x00,
  0xff, 0xdf, 0xff, 0xff, 0xff, 0xff, 0x84, 0xb6, 0x6c, 0x15, 0xff, 0xff, 0xff, 0xff, 0x00, 0x00,
  0x00, 0x00, 0x08, 0x41, 0xff, 0xff, 0xff, 0xff, 0xf7, 0xbe, 0xa5, 0x34, 0xa5, 0x34, 0xa5, 0x34,
  0xa5, 0x34, 0xa5, 0x34, 0xa5, 0x34, 0xa5, 0x34, 0xa5, 0x34, 0xff, 0xff, 0xff, 0xff, 0xff, 0xff,
  0x00, 0x00, 0x00, 0x00, 0x18, 0xe3, 0xff, 0xff, 0xff, 0xff, 0xff, 0xff, 0xff, 0xff, 0xff, 0xff,
  0x94, 0xb2, 0x52, 0xaa, 0x52, 0xaa, 0xa5, 0x14, 0xa5, 0x34, 0xa5, 0x34, 0xff, 0xff, 0xff, 0xff,
  0xff, 0xff, 0xff, 0xff, 0xff, 0xff, 0xe7, 0x3c, 0x00, 0x00, 0x00, 0x00, 0x63, 0x0c, 0xa5, 0x34,
  0xa5, 0x34, 0x18, 0xe3, 0x00, 0x00, 0x00, 0x00, 0xa5, 0x14, 0xa5, 0x34, 0xa5, 0x34, 0xff, 0xff,
  0xff, 0xff, 0xff, 0xff, 0xff, 0xff, 0xff, 0xff, 0xce, 0x59, 0x00, 0x00, 0x00, 0x00, 0x63, 0x2c,
  0xa5, 0x34, 0xa5, 0x34, 0x5a, 0xeb, 0x52, 0xaa, 0x52, 0xaa, 0x00, 0x00, 0x00, 0x00, 0x00, 0x20,
  0xff, 0xff, 0xff, 0xff, 0xde, 0xdb, 0x00, 0x00, 0x00, 0x00, 0x6b, 0x6d, 0xff, 0xff, 0xff, 0xff,
  0x52, 0xaa, 0x00, 0x00, 0x00, 0x00, 0xf7, 0x9e, 0xff, 0xff, 0xff, 0xff, 0xa5, 0x34, 0xa5, 0x34,
  0xa5, 0x34, 0xa5, 0x34, 0xa5, 0x34, 0xa5, 0x34, 0xa5, 0x34, 0xa5, 0x34, 0xde, 0xfb, 0xff, 0xff,
  0xff, 0xff, 0x29, 0x45, 0x00, 0x00, 0x00, 0x00, 0xff, 0xdf, 0xff, 0xff, 0xff, 0xff, 0x84, 0xb6,
  0x6c, 0x15, 0xff, 0xff, 0xff, 0xff, 0x00, 0x00, 0x00, 0x00, 0x08, 0x41, 0xff, 0xff, 0xff, 0xff,
  0xff, 0xff, 0xff, 0xff, 0xff, 0xff, 0xff, 0xff, 0xff, 0xff, 0xff, 0xff, 0xff, 0xff, 0xff, 0xff,
  0xff, 0xff, 0xff, 0xff, 0xff, 0xff, 0xff, 0xff, 0x00, 0x00, 0x00, 0x00, 0x18, 0xe3, 0xff, 0xff,
  0xff, 0xff, 0xff, 0xff, 0xff, 0xff, 0xff, 0xff, 0x63, 0x0c, 0x00, 0x00, 0x00, 0x00, 0xf7, 0x9e,
  0xff, 0xff, 0xff, 0xff, 0xff, 0xff, 0xff, 0xff, 0xff, 0xff, 0xff, 0xff, 0xff, 0xff, 0xe7, 0x3c,
  0x00, 0x00, 0x00, 0x00, 0x94, 0xb2, 0xff, 0xff, 0xff, 0xff, 0x29, 0x65, 0x00, 0x00, 0x00, 0x00,
  0xff, 0xdf, 0xff, 0xff, 0xff, 0xff, 0xff, 0xff, 0xff, 0xff, 0xff, 0xff, 0xff, 0xff, 0xff, 0xff,
  0xce, 0x59, 0x00, 0x00, 0x00, 0x00, 0x9c, 0xf3, 0xff, 0xff, 0xff, 0xff, 0x10, 0x82, 0x00, 0x00,
  0x00, 0x00, 0x00, 0x00, 0x00, 0x00, 0x00, 0x20, 0xff, 0xff, 0xff, 0xff, 0xde, 0xdb, 0x00, 0x00,
  0x00, 0x00, 0x6b, 0x6d, 0xff, 0xff, 0xff, 0xff, 0x52, 0xaa, 0x00, 0x00, 0x00, 0x00, 0xf7, 0x9e,
  0xff, 0xff, 0xff, 0xff, 0xff, 0xff, 0xff, 0xff, 0xff, 0xff, 0xff, 0xff, 0xff, 0xff, 0xff, 0xff,
  0xff, 0xff, 0xff, 0xff, 0xff, 0xff, 0xff, 0xff, 0xff, 0xff, 0x29, 0x45, 0x00, 0x00, 0x00, 0x00,
  0xff, 0xdf, 0xff, 0xff, 0xff, 0xff, 0x84, 0xb6, 0x6c, 0x15, 0xff, 0xff, 0xff, 0xff, 0x00, 0x00,
  0x00, 0x00, 0x08, 0x41, 0xff, 0xff, 0xff, 0xff, 0xff, 0xff, 0xff, 0xff, 0xff, 0xff, 0xff, 0xff,
  0xff, 0xff, 0xff, 0xff, 0xff, 0xff, 0xff, 0xff, 0xff, 0xff, 0xff, 0xff, 0xff, 0xff, 0xff, 0xff,
  0x00, 0x00, 0x00, 0x00, 0x18, 0xe3, 0xff, 0xff, 0xff, 0xff, 0xff, 0xff, 0xff, 0xff, 0xff, 0xff,
  0x63, 0x0c, 0x00, 0x00, 0x00, 0x00, 0xf7, 0x9e, 0xff, 0xff, 0xff, 0xff, 0xff, 0xff, 0xff, 0xff,
  0xff, 0xff, 0xff, 0xff, 0xff, 0xff, 0xe7, 0x3c, 0x00, 0x00, 0x00, 0x00, 0x94, 0xb2, 0xff, 0xff,
  0xff, 0xff, 0x29, 0x65, 0x00, 0x00, 0x00, 0x00, 0xff, 0xdf, 0xff, 0xff, 0xff, 0xff, 0xff, 0xff,
  0xff, 0xff, 0xff, 0xff, 0xff, 0xff, 0xff, 0xff, 0xce, 0x59, 0x00, 0x00, 0x00, 0x00, 0x9c, 0xf3,
  0xff, 0xff, 0xff, 0xff, 0x10, 0x82, 0x00, 0x00, 0x00, 0x00, 0x00, 0x00, 0x00, 0x00, 0x00, 0x20,
  0xff, 0xff, 0xff, 0xff, 0xde, 0xdb, 0x00, 0x00, 0x00, 0x00, 0x6b, 0x6d, 0xff, 0xff, 0xff, 0xff,
  0x52, 0xaa, 0x00, 0x00, 0x00, 0x00, 0xf7, 0x9e, 0xff, 0xff, 0xff, 0xff, 0xff, 0xff, 0xff, 0xff,
  0xff, 0xff, 0xff, 0xff, 0xff, 0xff, 0xff, 0xff, 0xff, 0xff, 0xff, 0xff, 0xff, 0xff, 0xff, 0xff,
  0xff, 0xff, 0x29, 0x45, 0x00, 0x00, 0x00, 0x00, 0xff, 0xdf, 0xff, 0xff, 0xff, 0xff, 0x84, 0xb6,
  0x6c, 0x15, 0xff, 0xff, 0xff, 0xff, 0x00, 0x00, 0x00, 0x00, 0x00, 0x00, 0x08, 0x61, 0x08, 0x61,
  0x10, 0x82, 0x08, 0x61, 0x10, 0x82, 0x08, 0x61, 0x08, 0x61, 0x08, 0x61, 0x10, 0x82, 0x08, 0x61,
  0x08, 0x61, 0x10, 0x82, 0x08, 0x61, 0x08, 0x61, 0x00, 0x00, 0x00, 0x00, 0x18, 0xe3, 0xff, 0xff,
  0xff, 0xff, 0x8c, 0x71, 0x08, 0x61, 0x08, 0x61, 0x9c, 0xd3, 0xef, 0x7d, 0xef, 0x7d, 0x18, 0xc3,
  0x08, 0x61, 0x08, 0x61, 0xff, 0xdf, 0xff, 0xff, 0xff, 0xff, 0x10, 0x82, 0x08, 0x61, 0x18, 0xe3,
  0xef, 0x7d, 0xef, 0x7d, 0x63, 0x2c, 0x10, 0x82, 0x08, 0x61, 0xce, 0x59, 0xef, 0x7d, 0xef, 0x7d,
  0x10, 0xa2, 0x08, 0x61, 0x08, 0x61, 0xff, 0xff, 0xff, 0xff, 0xf7, 0xbe, 0x08, 0x61, 0x08, 0x61,
  0x39, 0xc7, 0xef, 0x7d, 0xef, 0x7d, 0x63, 0x2c, 0x08, 0x61, 0x08, 0x61, 0xe7, 0x1c, 0xef, 0x7d,
  0xef, 0x7d, 0x00, 0x00, 0x00, 0x00, 0x00, 0x20, 0xff, 0xff, 0xff, 0xff, 0xde, 0xdb, 0x00, 0x00,
  0x00, 0x00, 0x6b, 0x6d, 0xff, 0xff, 0xff, 0xff, 0x52, 0xaa, 0x00, 0x00, 0x00, 0x00, 0x08, 0x61,
  0x08, 0x61, 0x08, 0x61, 0x08, 0x61, 0x08, 0x61, 0x08, 0x61, 0x08, 0x61, 0x08, 0x61, 0x10, 0x82,
  0x08, 0x61, 0x08, 0x61, 0x10, 0x82, 0x08, 0x61, 0x08, 0x61, 0x00, 0x00, 0x00, 0x00, 0x00, 0x00,
  0xff, 0xdf, 0xff, 0xff, 0xff, 0xff, 0x84, 0xb6, 0x6c, 0x15, 0xff, 0xff, 0xff, 0xff, 0x00, 0x00,
  0x00, 0x00, 0x00, 0x00, 0x00, 0x00, 0x00, 0x00, 0x00, 0x00, 0x00, 0x00, 0x00, 0x00, 0x00, 0x00,
  0x00, 0x00, 0x00, 0x00, 0x00, 0x00, 0x00, 0x00, 0x00, 0x00, 0x00, 0x00, 0x00, 0x00, 0x00, 0x00,
  0x00, 0x00, 0x00, 0x00, 0x18, 0xe3, 0xff, 0xff, 0xff, 0xff, 0x8c, 0x51, 0x00, 0x00, 0x00, 0x00,
  0x9c, 0xf3, 0xff, 0xff, 0xff, 0xff, 0x08, 0x61, 0x00, 0x00, 0x00, 0x00, 0xff, 0xdf, 0xff, 0xff,
  0xff, 0xff, 0x00, 0x00, 0x00, 0x00, 0x18, 0xc3, 0xff, 0xff, 0xff, 0xff, 0x63, 0x2c, 0x00, 0x00,
  0x00, 0x00, 0xd6, 0x9a, 0xff, 0xff, 0xff, 0xff, 0x00, 0x20, 0x00, 0x00, 0x00, 0x00, 0xff, 0xff,
  0xff, 0xff, 0xf7, 0xbe, 0x00, 0x00, 0x00, 0x00, 0x31, 0x86, 0xff, 0xff, 0xff, 0xff, 0x63, 0x0c,
  0x00, 0x00, 0x00, 0x00, 0xef, 0x5d, 0xff, 0xff, 0xff, 0xff, 0x00, 0x00, 0x00, 0x00, 0x00, 0x20,
  0xff, 0xff, 0xff, 0xff, 0xde, 0xdb, 0x00, 0x00, 0x00, 0x00, 0x6b, 0x6d, 0xff, 0xff, 0xff, 0xff,
  0x52, 0xaa, 0x00, 0x00, 0x00, 0x00, 0x00, 0x00, 0x00, 0x00, 0x00, 0x00, 0x00, 0x00, 0x00, 0x00,
  0x00, 0x00, 0x00, 0x00, 0x00, 0x00, 0x00, 0x00, 0x00, 0x00, 0x00, 0x00, 0x00, 0x00, 0x00, 0x00,
  0x00, 0x00, 0x00, 0x00, 0x00, 0x00, 0x00, 0x00, 0xff, 0xdf, 0xff, 0xff, 0xff, 0xff, 0x84, 0xb6,
  0x6c, 0x15, 0xff, 0xff, 0xff, 0xff, 0x00, 0x00, 0x00, 0x00, 0x00, 0x00, 0x00, 0x00, 0x00, 0x00,
  0x00, 0x00, 0x00, 0x00, 0x00, 0x00, 0x00, 0x00, 0x00, 0x00, 0x00, 0x00, 0x00, 0x00, 0x00, 0x00,
  0x00, 0x00, 0x00, 0x00, 0x00, 0x00, 0x00, 0x00, 0x00, 0x00, 0x00, 0x00, 0x18, 0xe3, 0xff, 0xff,
  0xff, 0xff, 0x8c, 0x51, 0x00, 0x00, 0x00, 0x00, 0x9c, 0xf3, 0xff, 0xff, 0xff, 0xff, 0x08, 0x61,
  0x00, 0x00, 0x00, 0x00, 0xff, 0xdf, 0xff, 0xff, 0xff, 0xff, 0x00, 0x00, 0x00, 0x00, 0x18, 0xc3,
  0xff, 0xff, 0xff, 0xff, 0x63, 0x2c, 0x00, 0x00, 0x00, 0x00, 0xd6, 0x9a, 0xff, 0xff, 0xff, 0xff,
  0x00, 0x20, 0x00, 0x00, 0x00, 0x00, 0xff, 0xff, 0xff, 0xff, 0xf7, 0xbe, 0x00, 0x00, 0x00, 0x00,
  0x31, 0x86, 0xff, 0xff, 0xff, 0xff, 0x63, 0x0c, 0x00, 0x00, 0x00, 0x00, 0xef, 0x5d, 0xff, 0xff,
  0xff, 0xff, 0x00, 0x00, 0x00, 0x00, 0x00, 0x20, 0xff, 0xff, 0xff, 0xff, 0xde, 0xdb, 0x00, 0x00,
  0x00, 0x00, 0x6b, 0x6d, 0xff, 0xff, 0xff, 0xff, 0x52, 0xaa, 0x00, 0x00, 0x00, 0x00, 0x00, 0x00,
  0x00, 0x00, 0x00, 0x00, 0x00, 0x00, 0x00, 0x00, 0x00, 0x00, 0x00, 0x00, 0x00, 0x00, 0x00, 0x00,
  0x00, 0x00, 0x00, 0x00, 0x00, 0x00, 0x00, 0x00, 0x00, 0x00, 0x00, 0x00, 0x00, 0x00, 0x00, 0x00,
  0xff, 0xdf, 0xff, 0xff, 0xff, 0xff, 0x84, 0xb6, 0x6c, 0x15, 0xff, 0xff, 0xff, 0xff, 0xff, 0xff,
  0xff, 0xff, 0xff, 0xff, 0xff, 0xff, 0xff, 0xff, 0xff, 0xff, 0xff, 0xff, 0xff, 0xff, 0xff, 0xff,
  0xff, 0xff, 0xff, 0xff, 0xff, 0xff, 0xff, 0xff, 0xff, 0xff, 0xff, 0xff, 0xff, 0xff, 0xff, 0xff,
  0xff, 0xff, 0xff, 0xff, 0xff, 0xff, 0xff, 0xff, 0xff, 0xff, 0x8c, 0x51, 0x00, 0x00, 0x00, 0x00,
  0x00, 0x00, 0x00, 0x00, 0x00, 0x00, 0x00, 0x00, 0x00, 0x00, 0x00, 0x00, 0xff, 0xdf, 0xff, 0xff,
  0xff, 0xff, 0x00, 0x00, 0x00, 0x00, 0x18, 0xc3, 0xff, 0xff, 0xff, 0xff, 0x63, 0x2c, 0x00, 0x00,
  0x00, 0x00, 0xd6, 0x9a, 0xff, 0xff, 0xff, 0xff, 0xff, 0xff, 0xff, 0xff, 0xff, 0xff, 0x00, 0x00,
  0x00, 0x00, 0x00, 0x00, 0x00, 0x00, 0x00, 0x00, 0x00, 0x00, 0x00, 0x00, 0x00, 0x00, 0x9c, 0xf3,
  0xff, 0xff, 0xff, 0xff, 0x10, 0x82, 0x00, 0x00, 0x00, 0x00, 0xff, 0xff, 0xff, 0xff, 0xf7, 0xbe,
  0x00, 0x00, 0x00, 0x00, 0x21, 0x24, 0xff, 0xff, 0xff, 0xff, 0xff, 0xff, 0xff, 0xff, 0xff, 0xff,
  0xff, 0xff, 0xff, 0xff, 0xff, 0xff, 0xff, 0xff, 0xff, 0xff, 0xff, 0xff, 0xff, 0xff, 0xff, 0xff,
  0xff, 0xff, 0xff, 0xff, 0xff, 0xff, 0xff, 0xff, 0xff, 0xff, 0xff, 0xff, 0xff, 0xff, 0xff, 0xff,
  0xff, 0xff, 0xff, 0xff, 0xff, 0xff, 0xff, 0xff, 0xff, 0xff, 0xff, 0xff, 0xff, 0xff, 0x84, 0xb6,
  0x6c, 0x15, 0xff, 0xff, 0xff, 0xff, 0xff, 0xff, 0xff, 0xff, 0xff, 0xff, 0xff, 0xff, 0xff, 0xff,
  0xff, 0xff, 0xff, 0xff, 0xff, 0xff, 0xff, 0xff, 0xff, 0xff, 0xff, 0xff, 0xff, 0xff, 0xff, 0xff,
  0xff, 0xff, 0xff, 0xff, 0xff, 0xff, 0xff, 0xff, 0xff, 0xff, 0xff, 0xff, 0xff, 0xff, 0xff, 0xff,
  0xff, 0xff, 0x8c, 0x51, 0x00, 0x00, 0x00, 0x00, 0x00, 0x00, 0x00, 0x00, 0x00, 0x00, 0x00, 0x00,
  0x00, 0x00, 0x00, 0x00, 0xff, 0xdf, 0xff, 0xff, 0xff, 0xff, 0x00, 0x00, 0x00, 0x00, 0x18, 0xc3,
  0xff, 0xff, 0xff, 0xff, 0x63, 0x2c, 0x00, 0x00, 0x00, 0x00, 0xd6, 0x9a, 0xff, 0xff, 0xff, 0xff,
  0xff, 0xff, 0xff, 0xff, 0xff, 0xff, 0x00, 0x00, 0x00, 0x00, 0x00, 0x00, 0x00, 0x00, 0x00, 0x00,
  0x00, 0x00, 0x00, 0x00, 0x00, 0x00, 0x9c, 0xf3, 0xff, 0xff, 0xff, 0xff, 0x10, 0x82, 0x00, 0x00,
  0x00, 0x00, 0xff, 0xff, 0xff, 0xff, 0xf7, 0xbe, 0x00, 0x00, 0x00, 0x00, 0x21, 0x24, 0xff, 0xff,
  0xff, 0xff, 0xff, 0xff, 0xff, 0xff, 0xff, 0xff, 0xff, 0xff, 0xff, 0xff, 0xff, 0xff, 0xff, 0xff,
  0xff, 0xff, 0xff, 0xff, 0xff, 0xff, 0xff, 0xff, 0xff, 0xff, 0xff, 0xff, 0xff, 0xff, 0xff, 0xff,
  0xff, 0xff, 0xff, 0xff, 0xff, 0xff, 0xff, 0xff, 0xff, 0xff, 0xff, 0xff, 0xff, 0xff, 0xff, 0xff,
  0xff, 0xff, 0xff, 0xff, 0xff, 0xff, 0x84, 0xb6, 0x6c, 0x15, 0xff, 0xff, 0xff, 0xff, 0xf7, 0xbe,
  0xf7, 0xbe, 0xf7, 0xbe, 0xf7, 0xbe, 0xf7, 0xbe, 0xf7, 0xbe, 0xf7, 0xbe, 0xf7, 0xbe, 0xff, 0xdf,
  0xff, 0xff, 0xff, 0xff, 0xf7, 0xbe, 0xf7, 0xbe, 0xf7, 0xbe, 0xf7, 0xbe, 0xf7, 0xbe, 0xf7, 0xbe,
  0xf7, 0xbe, 0xf7, 0xbe, 0xf7, 0xbe, 0xf7, 0xbe, 0xf7, 0xbe, 0x84, 0x10, 0x00, 0x00, 0x00, 0x00,
  0x00, 0x20, 0x08, 0x41, 0x08, 0x41, 0x00, 0x00, 0x00, 0x00, 0x00, 0x00, 0xef, 0x7d, 0xf7, 0xbe,
  0xf7, 0xbe, 0x08, 0x41, 0x08, 0x41, 0x21, 0x04, 0xff, 0xff, 0xff, 0xff, 0x6b, 0x6d, 0x08, 0x41,
  0x08, 0x41, 0xd6, 0xba, 0xff, 0xff, 0xff, 0xff, 0xf7, 0xbe, 0xf7, 0xbe, 0xf7, 0xbe, 0x08, 0x41,
  0x08, 0x41, 0x08, 0x41, 0x08, 0x41, 0x08, 0x41, 0x08, 0x41, 0x08, 0x41, 0x08, 0x41, 0x9c, 0xd3,
  0xf7, 0xbe, 0xf7, 0xbe, 0x18, 0xc3, 0x08, 0x41, 0x08, 0x41, 0xf7, 0xbe, 0xf7, 0xbe, 0xef, 0x7d,
  0x08, 0x41, 0x08, 0x41, 0x29, 0x65, 0xf7, 0xbe, 0xf7, 0xbe, 0xf7, 0xbe, 0xf7, 0xbe, 0xf7, 0xbe,
  0xf7, 0xbe, 0xf7, 0xbe, 0xf7, 0xbe, 0xff, 0xff, 0xff, 0xff, 0xff, 0xff, 0xff, 0xff, 0xff, 0xff,
  0xff, 0xff, 0xff, 0xff, 0xff, 0xff, 0xff, 0xff, 0xf7, 0xbe, 0xf7, 0xbe, 0xff, 0xdf, 0xff, 0xff,
  0xff, 0xff, 0xff, 0xff, 0xff, 0xff, 0xff, 0xff, 0xff, 0xff, 0xff, 0xff, 0xff, 0xff, 0x84, 0xb6,
  0x6c, 0x15, 0xff, 0xff, 0xff, 0xff, 0x00, 0x00, 0x00, 0x00, 0x00, 0x00, 0x00, 0x00, 0x00, 0x00,
  0x00, 0x00, 0x00, 0x00, 0x00, 0x00, 0x7b, 0xef, 0xff, 0xff, 0xff, 0xff, 0x08, 0x41, 0x00, 0x00,
  0x00, 0x00, 0x00, 0x00, 0x00, 0x00, 0x00, 0x00, 0x00, 0x00, 0x00, 0x00, 0x00, 0x00, 0x00, 0x00,
  0x00, 0x00, 0x00, 0x00, 0x00, 0x00, 0x00, 0x00, 0x9c, 0xf3, 0xff, 0xff, 0xff, 0xff, 0x08, 0x61,
  0x00, 0x00, 0x00, 0x00, 0x00, 0x00, 0x00, 0x00, 0x00, 0x00, 0xff, 0xff, 0xff, 0xff, 0xff, 0xff,
  0xff, 0xff, 0xff, 0xff, 0xff, 0xff, 0xff, 0xff, 0xff, 0xff, 0xff, 0xff, 0xff, 0xff, 0xff, 0xff,
  0x00, 0x20, 0x00, 0x00, 0x00, 0x00, 0xff, 0xff, 0xff, 0xff, 0xff, 0xff, 0xff, 0xff, 0xff, 0xff,
  0xff, 0xff, 0xff, 0xff, 0xff, 0xff, 0x63, 0x0c, 0x00, 0x00, 0x00, 0x00, 0xef, 0x5d, 0xff, 0xff,
  0xff, 0xff, 0x00, 0x00, 0x00, 0x00, 0x00, 0x20, 0xff, 0xff, 0xff, 0xff, 0xde, 0xdb, 0x00, 0x00,
  0x00, 0x00, 0x00, 0x00, 0x00, 0x00, 0x00, 0x00, 0x00, 0x00, 0x00, 0x00, 0x00, 0x00, 0xf7, 0x9e,
  0xff, 0xff, 0xff, 0xff, 0xff, 0xff, 0xff, 0xff, 0xff, 0xff, 0xff, 0xff, 0xff, 0xff, 0xde, 0xfb,
  0x00, 0x00, 0x00, 0x00, 0xa5, 0x34, 0xff, 0xff, 0xff, 0xff, 0xff, 0xff, 0xff, 0xff, 0xff, 0xff,
  0xff, 0xff, 0xff, 0xff, 0xff, 0xff, 0x84, 0xb6, 0x6c, 0x15, 0xff, 0xff, 0xff, 0xff, 0x00, 0x00,
  0x00, 0x00, 0x00, 0x00, 0x00, 0x00, 0x00, 0x00, 0x00, 0x00, 0x00, 0x00, 0x00, 0x00, 0x7b, 0xef,
  0xff, 0xff, 0xff, 0xff, 0x08, 0x41, 0x00, 0x00, 0x00, 0x00, 0x00, 0x00, 0x00, 0x00, 0x00, 0x00,
  0x00, 0x00, 0x00, 0x00, 0x00, 0x00, 0x00, 0x00, 0x00, 0x00, 0x00, 0x00, 0x00, 0x00, 0x00, 0x00,
  0x9c, 0xf3, 0xff, 0xff, 0xff, 0xff, 0x08, 0x61, 0x00, 0x00, 0x00, 0x00, 0x00, 0x00, 0x00, 0x00,
  0x00, 0x00, 0xff, 0xff, 0xff, 0xff, 0xff, 0xff, 0xff, 0xff, 0xff, 0xff, 0xff, 0xff, 0xff, 0xff,
  0xff, 0xff, 0xff, 0xff, 0xff, 0xff, 0xff, 0xff, 0x00, 0x20, 0x00, 0x00, 0x00, 0x00, 0xff, 0xff,
  0xff, 0xff, 0xff, 0xff, 0xff, 0xff, 0xff, 0xff, 0xff, 0xff, 0xff, 0xff, 0xff, 0xff, 0x63, 0x0c,
  0x00, 0x00, 0x00, 0x00, 0xef, 0x5d, 0xff, 0xff, 0xff, 0xff, 0x00, 0x00, 0x00, 0x00, 0x00, 0x20,
  0xff, 0xff, 0xff, 0xff, 0xde, 0xdb, 0x00, 0x00, 0x00, 0x00, 0x00, 0x00, 0x00, 0x00, 0x00, 0x00,
  0x00, 0x00, 0x00, 0x00, 0x00, 0x00, 0xf7, 0x9e, 0xff, 0xff, 0xff, 0xff, 0xff, 0xff, 0xff, 0xff,
  0xff, 0xff, 0xff, 0xff, 0xff, 0xff, 0xde, 0xfb, 0x00, 0x00, 0x00, 0x00, 0xa5, 0x34, 0xff, 0xff,
  0xff, 0xff, 0xff, 0xff, 0xff, 0xff, 0xff, 0xff, 0xff, 0xff, 0xff, 0xff, 0xff, 0xff, 0x84, 0xb6,
  0x6c, 0x15, 0xff, 0xff, 0xff, 0xff, 0x00, 0x00, 0x00, 0x00, 0x00, 0x00, 0x31, 0xa6, 0x31, 0xa6,
  0x29, 0x65, 0x00, 0x00, 0x00, 0x00, 0x7b, 0xef, 0xff, 0xff, 0xff, 0xff, 0x08, 0x41, 0x00, 0x00,
  0x00, 0x00, 0x00, 0x00, 0x00, 0x00, 0x00, 0x00, 0x31, 0xa6, 0x31, 0xa6, 0x29, 0x65, 0x00, 0x00,
  0x00, 0x00, 0x00, 0x00, 0x00, 0x00, 0x00, 0x00, 0x9c, 0xf3, 0xff, 0xff, 0xff, 0xff, 0x08, 0x61,
  0x00, 0x00, 0x00, 0x00, 0x00, 0x00, 0x00, 0x00, 0x00, 0x00, 0xff, 0xff, 0xff, 0xff, 0xff, 0xdf,
  0xce, 0x59, 0xce, 0x59, 0xef, 0x5d, 0xff, 0xff, 0xff, 0xff, 0xff, 0xff, 0xff, 0xff, 0xff, 0xff,
  0x39, 0xc7, 0x31, 0xa6, 0x31, 0xa6, 0xce, 0x59, 0xce, 0x59, 0xce, 0x59, 0xce, 0x59, 0xce, 0x59,
  0xce, 0x59, 0xce, 0x59, 0xce, 0x59, 0x4a, 0x69, 0x00, 0x00, 0x00, 0x00, 0xbd, 0xd7, 0xce, 0x59,
  0xce, 0x59, 0x31, 0xa6, 0x31, 0xa6, 0x39, 0xc7, 0xce, 0x59, 0xce, 0x59, 0xb5, 0xb6, 0x31, 0xa6,
  0x31, 0xa6, 0x18, 0xe3, 0x00, 0x00, 0x00, 0x00, 0x21, 0x04, 0x31, 0xa6, 0x31, 0xa6, 0xc6, 0x18,
  0xce, 0x59, 0xce, 0x59, 0xce, 0x59, 0xce, 0x59, 0xce, 0x59, 0xce, 0x59, 0xce, 0x59, 0xbd, 0xd7,
  0x31, 0xa6, 0x31, 0xa6, 0x94, 0xb2, 0xce, 0x59, 0xce, 0x59, 0xf7, 0xbe, 0xff, 0xff, 0xff, 0xff,
  0xff, 0xff, 0xff, 0xff, 0xff, 0xff, 0x84, 0xb6, 0x6c, 0x15, 0xff, 0xff, 0xff, 0xff, 0x00, 0x00,
  0x00, 0x00, 0x08, 0x41, 0xff, 0xff, 0xff, 0xff, 0xde, 0xfb, 0x00, 0x00, 0x00, 0x00, 0x7b, 0xef,
  0xff, 0xff, 0xff, 0xff, 0x08, 0x41, 0x00, 0x00, 0x00, 0x00, 0x00, 0x00, 0x00, 0x00, 0x00, 0x00,
  0xff, 0xff, 0xff, 0xff, 0xe7, 0x1c, 0x00, 0x00, 0x00, 0x00, 0x00, 0x00, 0x00, 0x00, 0x00, 0x00,
  0x9c, 0xf3, 0xff, 0xff, 0xff, 0xff, 0x08, 0x61, 0x00, 0x00, 0x00, 0x00, 0x00, 0x00, 0x00, 0x00,
  0x00, 0x00, 0xff, 0xff, 0xff, 0xff, 0xe7, 0x3c, 0x00, 0x00, 0x00, 0x00, 0x94, 0xb2, 0xff, 0xff,
  0xff, 0xff, 0xff, 0xff, 0xff, 0xff, 0xff, 0xff, 0xff, 0xff, 0xff, 0xff, 0xff, 0xff, 0x00, 0x00,
  0x00, 0x00, 0x00, 0x00, 0x00, 0x00, 0x00, 0x00, 0x00, 0x00, 0x00, 0x00, 0x00, 0x00, 0x00, 0x00,
  0x00, 0x00, 0x00, 0x00, 0x00, 0x00, 0x00, 0x00, 0x00, 0x00, 0xff, 0xff, 0xff, 0xff, 0xf7, 0xbe,
  0x00, 0x00, 0x00, 0x00, 0x21, 0x24, 0xff, 0xff, 0xff, 0xff, 0x8c, 0x71, 0x00, 0x00, 0x00, 0x00,
  0xad, 0x55, 0xff, 0xff, 0xff, 0xff, 0x08, 0x61, 0x00, 0x00, 0x00, 0x00, 0x00, 0x00, 0x00, 0x00,
  0x00, 0x00, 0x00, 0x00, 0x00, 0x00, 0x21, 0x04, 0xff, 0xff, 0xff, 0xff, 0x5a, 0xcb, 0x00, 0x00,
  0x00, 0x00, 0xd6, 0xba, 0xff, 0xff, 0xff, 0xff, 0xff, 0xff, 0xff, 0xff, 0xff, 0xff, 0x84, 0xb6,
  0x6c, 0x15, 0xff, 0xff, 0xff, 0xff, 0x00, 0x00, 0x00, 0x00, 0x08, 0x41, 0xff, 0xff, 0xff, 0xff,
  0xde, 0xfb, 0x00, 0x00, 0x00, 0x00, 0x7b, 0xef, 0xff, 0xff, 0xff, 0xff, 0x08, 0x41, 0x00, 0x00,
  0x00, 0x00, 0x00, 0x00, 0x00, 0x00, 0x00, 0x00, 0xff, 0xff, 0xff, 0xff, 0xe7, 0x1c, 0x00, 0x00,
  0x00, 0x00, 0x00, 0x00, 0x00, 0x00, 0x00, 0x00, 0x9c, 0xf3, 0xff, 0xff, 0xff, 0xff, 0x08, 0x61,
  0x00, 0x00, 0x00, 0x00, 0x00, 0x00, 0x00, 0x00, 0x00, 0x00, 0xff, 0xff, 0xff, 0xff, 0xe7, 0x3c,
  0x00, 0x00, 0x00, 0x00, 0x94, 0xb2, 0xff, 0xff, 0xff, 0xff, 0xff, 0xff, 0xff, 0xff, 0xff, 0xff,
  0xff, 0xff, 0xff, 0xff, 0xff, 0xff, 0x00, 0x00, 0x00, 0x00, 0x00, 0x00, 0x00, 0x00, 0x00, 0x00,
  0x00, 0x00, 0x00, 0x00, 0x00, 0x00, 0x00, 0x00, 0x00, 0x00, 0x00, 0x00, 0x00, 0x00, 0x00, 0x00,
  0x00, 0x00, 0xff, 0xff, 0xff, 0xff, 0xf7, 0xbe, 0x00, 0x00, 0x00, 0x00, 0x21, 0x24, 0xff, 0xff,
  0xff, 0xff, 0x8c, 0x71, 0x00, 0x00, 0x00, 0x00, 0xad, 0x55, 0xff, 0xff, 0xff, 0xff, 0x08, 0x61,
  0x00, 0x00, 0x00, 0x00, 0x00, 0x00, 0x00, 0x00, 0x00, 0x00, 0x00, 0x00, 0x00, 0x00, 0x21, 0x04,
  0xff, 0xff, 0xff, 0xff, 0x5a, 0xcb, 0x00, 0x00, 0x00, 0x00, 0xd6, 0xba, 0xff, 0xff, 0xff, 0xff,
  0xff, 0xff, 0xff, 0xff, 0xff, 0xff, 0x84, 0xb6, 0x6c, 0x15, 0xff, 0xff, 0xff, 0xff, 0x00, 0x00,
  0x00, 0x00, 0x00, 0x20, 0x6b, 0x4d, 0x6b, 0x4d, 0x6b, 0x6d, 0x94, 0xb2, 0x94, 0xb2, 0x84, 0x10,
  0x6b, 0x4d, 0x6b, 0x4d, 0x94, 0xb2, 0x94, 0xb2, 0x94, 0xb2, 0x94, 0xb2, 0x94, 0xb2, 0x94, 0xb2,
  0x6b, 0x4d, 0x6b, 0x4d, 0x6b, 0x6d, 0x94, 0xb2, 0x94, 0xb2, 0x4a, 0x69, 0x00, 0x00, 0x00, 0x00,
  0x42, 0x08, 0x6b, 0x4d, 0x6b, 0x4d, 0x94, 0x92, 0x94, 0xb2, 0x94, 0xb2, 0x94, 0xb2, 0x94, 0xb2,
  0x94, 0xb2, 0xff, 0xff, 0xff, 0xff, 0xf7, 0x9e, 0x94, 0xb2, 0x94, 0xb2, 0xd6, 0x9a, 0xff, 0xff,
  0xff, 0xff, 0xff, 0xff, 0xff, 0xff, 0xff, 0xff, 0x6b, 0x6d, 0x6b, 0x4d, 0x6b, 0x4d, 0x94, 0xb2,
  0x94, 0xb2, 0x94, 0xb2, 0x94, 0xb2, 0x94, 0xb2, 0x94, 0xb2, 0x94, 0xb2, 0x94, 0xb2, 0x39, 0xc7,
  0x00, 0x00, 0x00, 0x00, 0x8c, 0x51, 0x94, 0xb2, 0x94, 0xb2, 0x6b, 0x4d, 0x6b, 0x4d, 0x6b, 0x4d,
  0x94, 0xb2, 0x94, 0xb2, 0x8c, 0x71, 0x6b, 0x4d, 0x6b, 0x4d, 0x7b, 0xef, 0x94, 0xb2, 0x94, 0xb2,
  0x7b, 0xcf, 0x6b, 0x4d, 0x6b, 0x4d, 0x94, 0xb2, 0x94, 0xb2, 0x94, 0xb2, 0x00, 0x00, 0x00, 0x00,
  0x00, 0x20, 0x94, 0xb2, 0x94, 0xb2, 0x94, 0x92, 0x6b, 0x4d, 0x6b, 0x4d, 0x21, 0x24, 0x00, 0x00,
  0x00, 0x00, 0x5a, 0xcb, 0x6b, 0x4d, 0x6b, 0x4d, 0xff, 0xdf, 0xff, 0xff, 0xff, 0xff, 0x84, 0xb6,
  0x6c, 0x15, 0xff, 0xff, 0xff, 0xff, 0x00, 0x00, 0x00, 0x00, 0x00, 0x00, 0x00, 0x00, 0x00, 0x00,
  0x18, 0xe3, 0xff, 0xff, 0xff, 0xff, 0x7b, 0xef, 0x00, 0x00, 0x00, 0x00, 0xf7, 0xbe, 0xff, 0xff,
  0xff, 0xff, 0xff, 0xff, 0xff, 0xff, 0xff, 0xff, 0x00, 0x00, 0x00, 0x00, 0x18, 0xe3, 0xff, 0xff,
  0xff, 0xff, 0x8c, 0x51, 0x00, 0x00, 0x00, 0x00, 0x00, 0x00, 0x00, 0x00, 0x00, 0x00, 0xf7, 0x9e,
  0xff, 0xff, 0xff, 0xff, 0xff, 0xff, 0xff, 0xff, 0xff, 0xff, 0xff, 0xff, 0xff, 0xff, 0xff, 0xff,
  0xff, 0xff, 0xff, 0xff, 0xff, 0xff, 0xff, 0xff, 0xff, 0xff, 0xff, 0xff, 0xff, 0xff, 0xff, 0xff,
  0x00, 0x20, 0x00, 0x00, 0x00, 0x00, 0xff, 0xff, 0xff, 0xff, 0xff, 0xff, 0xff, 0xff, 0xff, 0xff,
  0xff, 0xff, 0xff, 0xff, 0xff, 0xff, 0x63, 0x0c, 0x00, 0x00, 0x00, 0x00, 0xef, 0x5d, 0xff, 0xff,
  0xff, 0xff, 0x00, 0x00, 0x00, 0x00, 0x00, 0x20, 0xff, 0xff, 0xff, 0xff, 0xde, 0xdb, 0x00, 0x00,
  0x00, 0x00, 0x6b, 0x6d, 0xff, 0xff, 0xff, 0xff, 0x52, 0xaa, 0x00, 0x00, 0x00, 0x00, 0xf7, 0x9e,
  0xff, 0xff, 0xff, 0xff, 0x00, 0x00, 0x00, 0x00, 0x08, 0x41, 0xff, 0xff, 0xff, 0xff, 0xde, 0xfb,
  0x00, 0x00, 0x00, 0x00, 0x00, 0x00, 0x00, 0x00, 0x00, 0x00, 0x00, 0x00, 0x00, 0x00, 0x00, 0x00,
  0xff, 0xdf, 0xff, 0xff, 0xff, 0xff, 0x84, 0xb6, 0x6c, 0x15, 0xff, 0xff, 0xff, 0xff, 0x00, 0x00,
  0x00, 0x00, 0x00, 0x00, 0x00, 0x00, 0x00, 0x00, 0x18, 0xe3, 0xff, 0xff, 0xff, 0xff, 0x7b, 0xef,
  0x00, 0x00, 0x00, 0x00, 0xf7, 0xbe, 0xff, 0xff, 0xff, 0xff, 0xff, 0xff, 0xff, 0xff, 0xff, 0xff,
  0x00, 0x00, 0x00, 0x00, 0x18, 0xe3, 0xff, 0xff, 0xff, 0xff, 0x8c, 0x51, 0x00, 0x00, 0x00, 0x00,
  0x00, 0x00, 0x00, 0x00, 0x00, 0x00, 0xf7, 0x9e, 0xff, 0xff, 0xff, 0xff, 0xff, 0xff, 0xff, 0xff,
  0xff, 0xff, 0xff, 0xff, 0xff, 0xff, 0xff, 0xff, 0xff, 0xff, 0xff, 0xff, 0xff, 0xff, 0xff, 0xff,
  0xff, 0xff, 0xff, 0xff, 0xff, 0xff, 0xff, 0xff, 0x00, 0x20, 0x00, 0x00, 0x00, 0x00, 0xff, 0xff,
  0xff, 0xff, 0xff, 0xff, 0xff, 0xff, 0xff, 0xff, 0xff, 0xff, 0xff, 0xff, 0xff, 0xff, 0x63, 0x0c,
  0x00, 0x00, 0x00, 0x00, 0xef, 0x5d, 0xff, 0xff, 0xff, 0xff, 0x00, 0x00, 0x00, 0x00, 0x00, 0x20,
  0xff, 0xff, 0xff, 0xff, 0xde, 0xdb, 0x00, 0x00, 0x00, 0x00, 0x6b, 0x6d, 0xff, 0xff, 0xff, 0xff,
  0x52, 0xaa, 0x00, 0x00, 0x00, 0x00, 0xf7, 0x9e, 0xff, 0xff, 0xff, 0xff, 0x00, 0x00, 0x00, 0x00,
  0x08, 0x41, 0xff, 0xff, 0xff, 0xff, 0xde, 0xfb, 0x00, 0x00, 0x00, 0x00, 0x00, 0x00, 0x00, 0x00,
  0x00, 0x00, 0x00, 0x00, 0x00, 0x00, 0x00, 0x00, 0xff, 0xdf, 0xff, 0xff, 0xff, 0xff, 0x84, 0xb6,
  0x6c, 0x15, 0xff, 0xff, 0xff, 0xff, 0x00, 0x00, 0x00, 0x00, 0x08, 0x41, 0xc6, 0x38, 0xc6, 0x38,
  0xb5, 0xb6, 0x31, 0xa6, 0x31, 0xa6, 0x18, 0xc3, 0x00, 0x00, 0x00, 0x00, 0xf7, 0xbe, 0xff, 0xff,
  0xff, 0xff, 0xff, 0xff, 0xff, 0xff, 0xff, 0xff, 0xc6, 0x38, 0xc6, 0x38, 0xb5, 0xb6, 0x31, 0xa6,
  0x31, 0xa6, 0x18, 0xe3, 0x00, 0x00, 0x00, 0x00, 0x7b, 0xef, 0xc6, 0x38, 0xc6, 0x38, 0xff, 0xff,
  0xff, 0xff, 0xff, 0xff, 0x39, 0xc7, 0x31, 0xa6, 0x31, 0xa6, 0xff, 0xff, 0xff, 0xff, 0xef, 0x5d,
  0x31, 0xa6, 0x31, 0xa6, 0x31, 0xa6, 0x31, 0xa6, 0x31, 0xa6, 0x31, 0xa6, 0x31, 0xa6, 0x31, 0xa6,
  0xc6, 0x38, 0xc6, 0x38, 0xc6, 0x38, 0xff, 0xff, 0xff, 0xff, 0xf7, 0xbe, 0x31, 0xa6, 0x31, 0xa6,
  0x31, 0xa6, 0x31, 0xa6, 0x31, 0xa6, 0x94, 0x92, 0xc6, 0x38, 0xc6, 0x38, 0xff, 0xdf, 0xff, 0xff,
  0xff, 0xff, 0xc6, 0x38, 0xc6, 0x38, 0xc6, 0x18, 0x31, 0xa6, 0x31, 0xa6, 0x4a, 0x69, 0xc6, 0x38,
  0xc6, 0x38, 0x8c, 0x51, 0x31, 0xa6, 0x31, 0xa6, 0x94, 0xb2, 0xc6, 0x38, 0xc6, 0x38, 0x39, 0xe7,
  0x31, 0xa6, 0x31, 0xa6, 0xc6, 0x38, 0xc6, 0x38, 0xc6, 0x18, 0x31, 0xa6, 0x31, 0xa6, 0x4a, 0x49,
  0xc6, 0x38, 0xc6, 0x38, 0x42, 0x28, 0x00, 0x00, 0x00, 0x00, 0xa5, 0x34, 0xc6, 0x38, 0xc6, 0x38,
  0xff, 0xff, 0xff, 0xff, 0xff, 0xff, 0x84, 0xb6, 0x6c, 0x15, 0xff, 0xff, 0xff, 0xff, 0x00, 0x00,
  0x00, 0x00, 0x08, 0x41, 0xff, 0xff, 0xff, 0xff, 0xde, 0xfb, 0x00, 0x00, 0x00, 0x00, 0x00, 0x00,
  0x00, 0x00, 0x00, 0x00, 0xf7, 0xbe, 0xff, 0xff, 0xff, 0xff, 0xff, 0xff, 0xff, 0xff, 0xff, 0xff,
  0xff, 0xff, 0xff, 0xff, 0xe7, 0x1c, 0x00, 0x00, 0x00, 0x00, 0x00, 0x00, 0x00, 0x00, 0x00, 0x00,
  0x9c, 0xf3, 0xff, 0xff, 0xff, 0xff, 0xff, 0xff, 0xff, 0xff, 0xff, 0xff, 0x00, 0x20, 0x00, 0x00,
  0x00, 0x00, 0xff, 0xff, 0xff, 0xff, 0xe7, 0x3c, 0x00, 0x00, 0x00, 0x00, 0x00, 0x00, 0x00, 0x00,
  0x00, 0x00, 0x00, 0x00, 0x00, 0x00, 0x00, 0x00, 0xff, 0xdf, 0xff, 0xff, 0xff, 0xff, 0xff, 0xff,
  0xff, 0xff, 0xf7, 0xbe, 0x00, 0x00, 0x00, 0x00, 0x00, 0x00, 0x00, 0x00, 0x00, 0x00, 0x9c, 0xf3,
  0xff, 0xff, 0xff, 0xff, 0xff, 0xff, 0xff, 0xff, 0xff, 0xff, 0xff, 0xff, 0xff, 0xff, 0xf7, 0xbe,
  0x00, 0x00, 0x00, 0x00, 0x21, 0x24, 0xff, 0xff, 0xff, 0xff, 0x8c, 0x71, 0x00, 0x00, 0x00, 0x00,
  0xad, 0x55, 0xff, 0xff, 0xff, 0xff, 0x08, 0x61, 0x00, 0x00, 0x00, 0x00, 0xff, 0xff, 0xff, 0xff,
  0xf7, 0x9e, 0x00, 0x00, 0x00, 0x00, 0x21, 0x04, 0xff, 0xff, 0xff, 0xff, 0x5a, 0xcb, 0x00, 0x00,
  0x00, 0x00, 0xd6, 0xba, 0xff, 0xff, 0xff, 0xff, 0xff, 0xff, 0xff, 0xff, 0xff, 0xff, 0x84, 0xb6,
  0x6c, 0x15, 0xff, 0xff, 0xff, 0xff, 0x00, 0x00, 0x00, 0x00, 0x08, 0x41, 0xff, 0xff, 0xff, 0xff,
  0xde, 0xfb, 0x00, 0x00, 0x00, 0x00, 0x00, 0x00, 0x00, 0x00, 0x00, 0x00, 0xf7, 0xbe, 0xff, 0xff,
  0xff, 0xff, 0xff, 0xff, 0xff, 0xff, 0xff, 0xff, 0xff, 0xff, 0xff, 0xff, 0xe7, 0x1c, 0x00, 0x00,
  0x00, 0x00, 0x00, 0x00, 0x00, 0x00, 0x00, 0x00, 0x9c, 0xf3, 0xff, 0xff, 0xff, 0xff, 0xff, 0xff,
  0xff, 0xff, 0xff, 0xff, 0x00, 0x20, 0x00, 0x00, 0x00, 0x00, 0xff, 0xff, 0xff, 0xff, 0xe7, 0x3c,
  0x00, 0x00, 0x00, 0x00, 0x00, 0x00, 0x00, 0x00, 0x00, 0x00, 0x00, 0x00, 0x00, 0x00, 0x00, 0x00,
  0xff, 0xdf, 0xff, 0xff, 0xff, 0xff, 0xff, 0xff, 0xff, 0xff, 0xf7, 0xbe, 0x00, 0x00, 0x00, 0x00,
  0x00, 0x00, 0x00, 0x00, 0x00, 0x00, 0x9c, 0xf3, 0xff, 0xff, 0xff, 0xff, 0xff, 0xff, 0xff, 0xff,
  0xff, 0xff, 0xff, 0xff, 0xff, 0xff, 0xf7, 0xbe, 0x00, 0x00, 0x00, 0x00, 0x21, 0x24, 0xff, 0xff,
  0xff, 0xff, 0x8c, 0x71, 0x00, 0x00, 0x00, 0x00, 0xad, 0x55, 0xff, 0xff, 0xff, 0xff, 0x08, 0x61,
  0x00, 0x00, 0x00, 0x00, 0xff, 0xff, 0xff, 0xff, 0xf7, 0x9e, 0x00, 0x00, 0x00, 0x00, 0x21, 0x04,
  0xff, 0xff, 0xff, 0xff, 0x5a, 0xcb, 0x00, 0x00, 0x00, 0x00, 0xd6, 0xba, 0xff, 0xff, 0xff, 0xff,
  0xff, 0xff, 0xff, 0xff, 0xff, 0xff, 0x84, 0xb6, 0x6c, 0x15, 0xff, 0xff, 0xff, 0xff, 0x00, 0x00,
  0x00, 0x00, 0x00, 0x00, 0x00, 0x20, 0x00, 0x20, 0x21, 0x24, 0xf7, 0xbe, 0xf7, 0xbe, 0xf7, 0xbe,
  0xf7, 0xbe, 0xf7, 0xbe, 0xff, 0xff, 0xff, 0xff, 0xff, 0xff, 0xff, 0xff, 0xff, 0xff, 0xff, 0xff,
  0x00, 0x20, 0x00, 0x20, 0x21, 0x04, 0xf7, 0xbe, 0xf7, 0xbe, 0xf7, 0xbe, 0xf7, 0xbe, 0xf7, 0xbe,
  0xff, 0xff, 0xff, 0xff, 0xff, 0xff, 0xff, 0xff, 0xff, 0xff, 0xff, 0xff, 0xf7, 0xbe, 0xf7, 0xbe,
  0xf7, 0xbe, 0x00, 0x20, 0x00, 0x20, 0x18, 0xc3, 0xf7, 0xbe, 0xf7, 0xbe, 0x63, 0x0c, 0x00, 0x00,
  0x00, 0x00, 0x00, 0x00, 0x00, 0x00, 0x00, 0x00, 0xff, 0xdf, 0xff, 0xff, 0xff, 0xff, 0xff, 0xff,
  0xff, 0xff, 0xf7, 0xbe, 0x00, 0x00, 0x00, 0x00, 0x31, 0x86, 0xf7, 0xbe, 0xf7, 0xbe, 0x63, 0x0c,
  0x00, 0x20, 0x00, 0x20, 0x00, 0x20, 0x00, 0x20, 0x00, 0x20, 0xff, 0xff, 0xff, 0xff, 0xff, 0xff,
  0xf7, 0xbe, 0xf7, 0xbe, 0xd6, 0xba, 0x00, 0x20, 0x00, 0x20, 0x6b, 0x6d, 0xf7, 0xbe, 0xf7, 0xbe,
  0x5a, 0xcb, 0x00, 0x20, 0x00, 0x20, 0x00, 0x00, 0x00, 0x00, 0x00, 0x00, 0xff, 0xff, 0xff, 0xff,
  0xff, 0xff, 0xf7, 0xbe, 0xf7, 0xbe, 0xde, 0xdb, 0x00, 0x20, 0x00, 0x20, 0xa5, 0x34, 0xf7, 0xbe,
  0xf7, 0xbe, 0x29, 0x65, 0x00, 0x20, 0x00, 0x20, 0xff, 0xdf, 0xff, 0xff, 0xff, 0xff, 0x84, 0xb6,
  0x6c, 0x15, 0xff, 0xff, 0xff, 0xff, 0x00, 0x00, 0x00, 0x00, 0x00, 0x00, 0x00, 0x00, 0x00, 0x00,
  0x18, 0xe3, 0xff, 0xff, 0xff, 0xff, 0xff, 0xff, 0xff, 0xff, 0xff, 0xff, 0xff, 0xff, 0xff, 0xff,
  0xff, 0xff, 0xff, 0xff, 0xff, 0xff, 0xff, 0xff, 0x00, 0x00, 0x00, 0x00, 0x18, 0xe3, 0xff, 0xff,
  0xff, 0xff, 0xff, 0xff, 0xff, 0xff, 0xff, 0xff, 0xff, 0xff, 0xff, 0xff, 0xff, 0xff, 0xff, 0xff,
  0xff, 0xff, 0xff, 0xff, 0xff, 0xff, 0xff, 0xff, 0xff, 0xff, 0x00, 0x00, 0x00, 0x00, 0x18, 0xc3,
  0xff, 0xff, 0xff, 0xff, 0x63, 0x2c, 0x00, 0x00, 0x00, 0x00, 0x00, 0x00, 0x00, 0x00, 0x00, 0x00,
  0xff, 0xdf, 0xff, 0xff, 0xff, 0xff, 0xff, 0xff, 0xff, 0xff, 0xf7, 0xbe, 0x00, 0x00, 0x00, 0x00,
  0x31, 0x86, 0xff, 0xff, 0xff, 0xff, 0x63, 0x0c, 0x00, 0x00, 0x00, 0x00, 0x00, 0x00, 0x00, 0x00,
  0x00, 0x00, 0xff, 0xff, 0xff, 0xff, 0xff, 0xff, 0xff, 0xff, 0xff, 0xff, 0xde, 0xdb, 0x00, 0x00,
  0x00, 0x00, 0x6b, 0x6d, 0xff, 0xff, 0xff, 0xff, 0x52, 0xaa, 0x00, 0x00, 0x00, 0x00, 0x00, 0x00,
  0x00, 0x00, 0x00, 0x00, 0xff, 0xff, 0xff, 0xff, 0xff, 0xff, 0xff, 0xff, 0xff, 0xff, 0xde, 0xfb,
  0x00, 0x00, 0x00, 0x00, 0xa5, 0x34, 0xff, 0xff, 0xff, 0xff, 0x29, 0x45, 0x00, 0x00, 0x00, 0x00,
  0xff, 0xdf, 0xff, 0xff, 0xff, 0xff, 0x84, 0xb6, 0x6c, 0x15, 0xff, 0xff, 0xff, 0xff, 0x00, 0x00,
  0x00, 0x00, 0x00, 0x00, 0x00, 0x00, 0x00, 0x00, 0x18, 0xe3, 0xff, 0xff, 0xff, 0xff, 0xff, 0xff,
  0xff, 0xff, 0xff, 0xff, 0xff, 0xff, 0xff, 0xff, 0xff, 0xff, 0xff, 0xff, 0xff, 0xff, 0xff, 0xff,
  0x00, 0x00, 0x00, 0x00, 0x18, 0xe3, 0xff, 0xff, 0xff, 0xff, 0xff, 0xff, 0xff, 0xff, 0xff, 0xff,
  0xff, 0xff, 0xff, 0xff, 0xff, 0xff, 0xff, 0xff, 0xff, 0xff, 0xff, 0xff, 0xff, 0xff, 0xff, 0xff,
  0xff, 0xff, 0x00, 0x00, 0x00, 0x00, 0x18, 0xc3, 0xff, 0xff, 0xff, 0xff, 0x63, 0x2c, 0x00, 0x00,
  0x00, 0x00, 0x00, 0x00, 0x00, 0x00, 0x00, 0x00, 0xff, 0xdf, 0xff, 0xff, 0xff, 0xff, 0xff, 0xff,
  0xff, 0xff, 0xf7, 0xbe, 0x00, 0x00, 0x00, 0x00, 0x31, 0x86, 0xff, 0xff, 0xff, 0xff, 0x63, 0x0c,
  0x00, 0x00, 0x00, 0x00, 0x00, 0x00, 0x00, 0x00, 0x00, 0x00, 0xff, 0xff, 0xff, 0xff, 0xff, 0xff,
  0xff, 0xff, 0xff, 0xff, 0xde, 0xdb, 0x00, 0x00, 0x00, 0x00, 0x6b, 0x6d, 0xff, 0xff, 0xff, 0xff,
  0x52, 0xaa, 0x00, 0x00, 0x00, 0x00, 0x00, 0x00, 0x00, 0x00, 0x00, 0x00, 0xff, 0xff, 0xff, 0xff,
  0xff, 0xff, 0xff, 0xff, 0xff, 0xff, 0xde, 0xfb, 0x00, 0x00, 0x00, 0x00, 0xa5, 0x34, 0xff, 0xff,
  0xff, 0xff, 0x29, 0x45, 0x00, 0x00, 0x00, 0x00, 0xff, 0xdf, 0xff, 0xff, 0xff, 0xff, 0x84, 0xb6,
  0x6c, 0x15, 0xff, 0xff, 0xff, 0xff, 0xff, 0xff, 0xff, 0xff, 0xff, 0xff, 0xff, 0xff, 0xff, 0xff,
  0xff, 0xff, 0xff, 0xff, 0xff, 0xff, 0xff, 0xff, 0xff, 0xff, 0xff, 0xff, 0x08, 0x41, 0x00, 0x00,
  0x00, 0x00, 0x00, 0x00, 0x00, 0x00, 0x00, 0x00, 0xff, 0xff, 0xff, 0xff, 0xe7, 0x1c, 0x00, 0x00,
  0x00, 0x00, 0x00, 0x00, 0x00, 0x00, 0x00, 0x00, 0x9c, 0xf3, 0xff, 0xff, 0xff, 0xff, 0xff, 0xff,
  0xff, 0xff, 0xff, 0xff, 0x00, 0x20, 0x00, 0x00, 0x00, 0x00, 0x00, 0x00, 0x00, 0x00, 0x00, 0x00,
  0x00, 0x00, 0x00, 0x00, 0x00, 0x00, 0x00, 0x20, 0x00, 0x00, 0x00, 0x00, 0x00, 0x00, 0x00, 0x00,
  0xff, 0xdf, 0xff, 0xff, 0xff, 0xff, 0x00, 0x00, 0x00, 0x00, 0x08, 0x41, 0xff, 0xff, 0xff, 0xff,
  0xce, 0x59, 0x00, 0x00, 0x00, 0x00, 0x9c, 0xf3, 0xff, 0xff, 0xff, 0xff, 0x10, 0x82, 0x00, 0x00,
  0x00, 0x00, 0xff, 0xff, 0xff, 0xff, 0xf7, 0xbe, 0x00, 0x00, 0x00, 0x00, 0x21, 0x24, 0xff, 0xff,
  0xff, 0xff, 0x8c, 0x71, 0x00, 0x00, 0x00, 0x00, 0xad, 0x55, 0xff, 0xff, 0xff, 0xff, 0xff, 0xff,
  0xff, 0xff, 0xff, 0xff, 0xff, 0xff, 0xff, 0xff, 0xf7, 0x9e, 0x00, 0x00, 0x00, 0x00, 0x00, 0x00,
  0x00, 0x00, 0x00, 0x00, 0x00, 0x00, 0x00, 0x00, 0x00, 0x00, 0xd6, 0xba, 0xff, 0xff, 0xff, 0xff,
  0xff, 0xff, 0xff, 0xff, 0xff, 0xff, 0x84, 0xb6, 0x6c, 0x15, 0xff, 0xff, 0xff, 0xff, 0xff, 0xff,
  0xff, 0xff, 0xff, 0xff, 0xff, 0xff, 0xff, 0xff, 0xff, 0xff, 0xff, 0xff, 0xff, 0xff, 0xff, 0xff,
  0xff, 0xff, 0xff, 0xff, 0x08, 0x41, 0x00, 0x00, 0x00, 0x00, 0x00, 0x00, 0x00, 0x00, 0x00, 0x00,
  0xff, 0xff, 0xff, 0xff, 0xe7, 0x1c, 0x00, 0x00, 0x00, 0x00, 0x00, 0x00, 0x00, 0x00, 0x00, 0x00,
  0x9c, 0xf3, 0xff, 0xff, 0xff, 0xff, 0xff, 0xff, 0xff, 0xff, 0xff, 0xff, 0x00, 0x20, 0x00, 0x00,
  0x00, 0x00, 0x00, 0x00, 0x00, 0x00, 0x00, 0x00, 0x00, 0x00, 0x94, 0xb2, 0xff, 0xdf, 0xff, 0xbe,
  0xff, 0xdf, 0xde, 0xdb, 0x00, 0x20, 0x00, 0x00, 0xff, 0xdf, 0xff, 0xff, 0xff, 0xff, 0x00, 0x00,
  0x00, 0x00, 0xce, 0x59, 0xff, 0xff, 0xff, 0x7d, 0xff, 0xdf, 0xa5, 0x34, 0x00, 0x00, 0x9c, 0xf3,
  0xff, 0xff, 0xff, 0xff, 0x10, 0x82, 0x00, 0x00, 0x00, 0x00, 0xff, 0xff, 0xff, 0xff, 0xf7, 0xbe,
  0x00, 0x00, 0x00, 0x00, 0x21, 0x24, 0xff, 0xff, 0xff, 0xff, 0x8c, 0x71, 0x00, 0x00, 0x00, 0x00,
  0xad, 0x55, 0xff, 0xff, 0xff, 0xff, 0xff, 0xff, 0xff, 0xff, 0xff, 0xff, 0xff, 0xff, 0xff, 0xff,
  0xf7, 0x9e, 0x00, 0x00, 0x00, 0x00, 0x00, 0x00, 0x00, 0x00, 0x00, 0x00, 0x00, 0x00, 0x00, 0x00,
  0x00, 0x00, 0xd6, 0xba, 0xff, 0xff, 0xff, 0xff, 0xff, 0xff, 0xff, 0xff, 0xff, 0xff, 0x84, 0xb6,
  0x6c, 0x15, 0xff, 0xff, 0xff, 0xff, 0xf7, 0x9e, 0xf7, 0x9e, 0xf7, 0x9e, 0xff, 0xff, 0xff, 0xff,
  0xff, 0xff, 0xf7, 0x9e, 0xf7, 0x9e, 0xff, 0xdf, 0xff, 0xff, 0xff, 0xff, 0x08, 0x41, 0x00, 0x00,
  0x00, 0x00, 0x08, 0x61, 0x08, 0x61, 0x08, 0x61, 0xf7, 0x9e, 0xf7, 0x9e, 0xd6, 0xba, 0x08, 0x61,
  0x08, 0x61, 0x08, 0x41, 0x00, 0x00, 0x00, 0x00, 0x9c, 0xf3, 0xff, 0xff, 0xff, 0xff, 0xf7, 0x9e,
  0xf7, 0x9e, 0xf7, 0x9e, 0x00, 0x00, 0x00, 0x00, 0x00, 0x00, 0x00, 0x00, 0x00, 0x00, 0x00, 0x00,
  0x8c, 0x51, 0xff, 0x1c, 0xe1, 0x87, 0xa1, 0x64, 0xa1, 0x64, 0xbb, 0x0b, 0xf7, 0xbe, 0x00, 0x00,
  0xff, 0xdf, 0xff, 0xff, 0xff, 0xff, 0x08, 0x61, 0xe7, 0x3c, 0xf5, 0x35, 0xe9, 0x26, 0xe9, 0x06,
  0xe9, 0x46, 0xf5, 0xd7, 0xb5, 0x96, 0x9c, 0xd3, 0xf7, 0x9e, 0xf7, 0x9e, 0x18, 0xc3, 0x08, 0x61,
  0x08, 0x61, 0xf7, 0x9e, 0xf7, 0x9e, 0xef, 0x7d, 0x08, 0x61, 0x08, 0x61, 0x29, 0x65, 0xf7, 0x9e,
  0xf7, 0x9e, 0x8c, 0x71, 0x08, 0x61, 0x08, 0x61, 0xa5, 0x14, 0xf7, 0x9e, 0xf7, 0x9e, 0xff, 0xff,
  0xff, 0xff, 0xff, 0xff, 0xff, 0xff, 0xff, 0xff, 0xf7, 0xbe, 0x08, 0x61, 0x08, 0x61, 0x08, 0x41,
  0x00, 0x00, 0x00, 0x00, 0x00, 0x20, 0x08, 0x61, 0x08, 0x61, 0xce, 0x59, 0xf7, 0x9e, 0xf7, 0x9e,
  0xff, 0xff, 0xff, 0xff, 0xff, 0xff, 0x84, 0xb6, 0x6c, 0x15, 0xff, 0xff, 0xff, 0xff, 0x00, 0x00,
  0x00, 0x00, 0x08, 0x41, 0xff, 0xff, 0xff, 0xff, 0xde, 0xfb, 0x00, 0x00, 0x00, 0x00, 0x7b, 0xef,
  0xff, 0xff, 0xff, 0xff, 0x08, 0x41, 0x00, 0x00, 0x00, 0x00, 0xff, 0xdf, 0xff, 0xff, 0xff, 0xff,
  0x00, 0x00, 0x00, 0x00, 0x18, 0xe3, 0xff, 0xff, 0xff, 0xff, 0x8c, 0x51, 0x00, 0x00, 0x00, 0x00,
  0x9c, 0xf3, 0xff, 0xff, 0xff, 0xff, 0x08, 0x61, 0x00, 0x00, 0x00, 0x00, 0x00, 0x00, 0x00, 0x00,
  0x00, 0x00, 0x00, 0x00, 0x00, 0x00, 0x18, 0xc3, 0xff, 0xff, 0xe9, 0x87, 0xb9, 0x44, 0xa1, 0x64,
  0xa1, 0x64, 0xa1, 0x64, 0xd4, 0xd2, 0xa5, 0x34, 0xff, 0xdf, 0xff, 0xff, 0xff, 0xff, 0xff, 0xff,
  0xff, 0x5d, 0xe9, 0x06, 0xe9, 0x06, 0xe9, 0x06, 0xe9, 0x06, 0xe9, 0x06, 0xff, 0xbe, 0x63, 0x0c,
  0x00, 0x00, 0x00, 0x00, 0xef, 0x5d, 0xff, 0xff, 0xff, 0xff, 0x00, 0x00, 0x00, 0x00, 0x00, 0x20,
  0xff, 0xff, 0xff, 0xff, 0xde, 0xdb, 0x00, 0x00, 0x00, 0x00, 0x6b, 0x6d, 0xff, 0xff, 0xff, 0xff,
  0x52, 0xaa, 0x00, 0x00, 0x00, 0x00, 0xf7, 0x9e, 0xff, 0xff, 0xff, 0xff, 0xff, 0xff, 0xff, 0xff,
  0xff, 0xff, 0xff, 0xff, 0xff, 0xff, 0xde, 0xfb, 0x00, 0x00, 0x00, 0x00, 0xa5, 0x34, 0xff, 0xff,
  0xff, 0xff, 0x29, 0x45, 0x00, 0x00, 0x00, 0x00, 0xff, 0xdf, 0xff, 0xff, 0xff, 0xff, 0x84, 0xb6,
  0x6c, 0x15, 0xff, 0xff, 0xff, 0xff, 0x00, 0x00, 0x00, 0x00, 0x08, 0x41, 0xff, 0xff, 0xff, 0xff,
  0xde, 0xfb, 0x00, 0x00, 0x00, 0x00, 0x7b, 0xef, 0xff, 0xff, 0xff, 0xff, 0x08, 0x41, 0x00, 0x00,
  0x00, 0x00, 0xff, 0xdf, 0xff, 0xff, 0xff, 0xff, 0x00, 0x00, 0x00, 0x00, 0x18, 0xe3, 0xff, 0xff,
  0xff, 0xff, 0x8c, 0x51, 0x00, 0x00, 0x00, 0x00, 0x9c, 0xf3, 0xff, 0xff, 0xff, 0xff, 0x08, 0x61,
  0x00, 0x00, 0x00, 0x00, 0x00, 0x00, 0x00, 0x00, 0x00, 0x00, 0x00, 0x00, 0x00, 0x00, 0x18, 0xc3,
  0xff, 0x9e, 0xe9, 0x06, 0xb9, 0x45, 0xa1, 0x64, 0xa1, 0x64, 0xa1, 0x64, 0xa1, 0x64, 0xff, 0xbe,
  0xff, 0xff, 0xff, 0xff, 0xff, 0xff, 0xff, 0xff, 0xe9, 0xa8, 0xe9, 0x06, 0xe9, 0x06, 0xe9, 0x06,
  0xe9, 0x06, 0xe9, 0x06, 0xf5, 0xf8, 0x63, 0x0c, 0x00, 0x00, 0x00, 0x00, 0xef, 0x5d, 0xff, 0xff,
  0xff, 0xff, 0x00, 0x00, 0x00, 0x00, 0x00, 0x20, 0xff, 0xff, 0xff, 0xff, 0xde, 0xdb, 0x00, 0x00,
  0x00, 0x00, 0x6b, 0x6d, 0xff, 0xff, 0xff, 0xff, 0x52, 0xaa, 0x00, 0x00, 0x00, 0x00, 0xf7, 0x9e,
  0xff, 0xff, 0xff, 0xff, 0xff, 0xff, 0xff, 0xff, 0xff, 0xff, 0xff, 0xff, 0xff, 0xff, 0xde, 0xfb,
  0x00, 0x00, 0x00, 0x00, 0xa5, 0x34, 0xff, 0xff, 0xff, 0xff, 0x29, 0x45, 0x00, 0x00, 0x00, 0x00,
  0xff, 0xdf, 0xff, 0xff, 0xff, 0xff, 0x84, 0xb6, 0x6c, 0x15, 0xff, 0xff, 0xff, 0xff, 0x21, 0x24,
  0x21, 0x24, 0x29, 0x65, 0xff, 0xff, 0xff, 0xff, 0xe7, 0x1c, 0x21, 0x24, 0x21, 0x24, 0x94, 0x92,
  0xff, 0xff, 0xff, 0xff, 0x29, 0x65, 0x21, 0x24, 0x21, 0x24, 0xff, 0xdf, 0xff, 0xff, 0xff, 0xff,
  0x21, 0x24, 0x21, 0x24, 0x39, 0xc7, 0xde, 0xdb, 0xde, 0xdb, 0x73, 0xae, 0x00, 0x00, 0x00, 0x00,
  0x84, 0x30, 0xde, 0xdb, 0xde, 0xdb, 0x29, 0x65, 0x21, 0x24, 0x21, 0x24, 0x21, 0x24, 0x21, 0x24,
  0x21, 0x24, 0x00, 0x00, 0x00, 0x00, 0x10, 0x82, 0xff, 0xdf, 0xe9, 0x26, 0xe1, 0x05, 0xa1, 0x44,
  0xa1, 0x64, 0xa1, 0x64, 0xa1, 0x64, 0xba, 0xca, 0xff, 0xff, 0xde, 0xdb, 0xff, 0xdf, 0xf5, 0xf8,
  0xe9, 0x06, 0xe9, 0x06, 0xe9, 0x06, 0xe9, 0x06, 0xe9, 0x06, 0xe9, 0x06, 0xfe, 0xfb, 0x63, 0x0c,
  0x00, 0x00, 0x00, 0x00, 0xce, 0x59, 0xde, 0xdb, 0xde, 0xdb, 0x21, 0x24, 0x21, 0x24, 0x29, 0x45,
  0xde, 0xdb, 0xde, 0xdb, 0xbd, 0xf7, 0x21, 0x24, 0x21, 0x24, 0x73, 0x8e, 0xde, 0xdb, 0xde, 0xdb,
  0x63, 0x0c, 0x21, 0x24, 0x21, 0x24, 0xd6, 0x9a, 0xde, 0xdb, 0xde, 0xdb, 0xde, 0xdb, 0xde, 0xdb,
  0xde, 0xdb, 0xde, 0xdb, 0xde, 0xdb, 0xc6, 0x38, 0x21, 0x24, 0x21, 0x24, 0x9c, 0xf3, 0xde, 0xdb,
  0xde, 0xdb, 0x42, 0x28, 0x21, 0x24, 0x21, 0x24, 0xff, 0xdf, 0xff, 0xff, 0xff, 0xff, 0x84, 0xb6,
  0x6c, 0x15, 0xff, 0xff, 0xff, 0xff, 0xff, 0xff, 0xff, 0xff, 0xff, 0xff, 0xff, 0xff, 0xff, 0xff,
  0xff, 0xff, 0xff, 0xff, 0xff, 0xff, 0xff, 0xff, 0xff, 0xff, 0xff, 0xff, 0xff, 0xff, 0xff, 0xff,
  0xff, 0xff, 0xff, 0xff, 0xff, 0xff, 0xff, 0xff, 0xff, 0xff, 0xff, 0xff, 0xe7, 0x1c, 0x00, 0x00,
  0x00, 0x00, 0x00, 0x00, 0x00, 0x00, 0x00, 0x00, 0x00, 0x00, 0x00, 0x00, 0x00, 0x00, 0xf7, 0x9e,
  0xff, 0xff, 0xff, 0xff, 0xff, 0xff, 0xff, 0xff, 0xff, 0xff, 0x00, 0x00, 0x00, 0x00, 0x00, 0x00,
  0xd6, 0x9a, 0xeb, 0x2e, 0xe9, 0x06, 0xc1, 0x25, 0xa1, 0x64, 0xa1, 0x64, 0xa1, 0x64, 0xa1, 0x64,
  0xf6, 0xfb, 0x39, 0xa6, 0xff, 0xff, 0xe9, 0x26, 0xe9, 0x06, 0xe9, 0x06, 0xe9, 0x06, 0xe9, 0x06,
  0xe9, 0x06, 0xe9, 0x88, 0xff, 0xff, 0x63, 0x0c, 0x00, 0x00, 0x00, 0x00, 0x00, 0x00, 0x00, 0x00,
  0x00, 0x00, 0xff, 0xff, 0xff, 0xff, 0xf7, 0xbe, 0x00, 0x00, 0x00, 0x00, 0x21, 0x24, 0xff, 0xff,
  0xff, 0xff, 0x8c, 0x71, 0x00, 0x00, 0x00, 0x00, 0xad, 0x55, 0xff, 0xff, 0xff, 0xff, 0x08, 0x61,
  0x00, 0x00, 0x00, 0x00, 0x00, 0x00, 0x00, 0x00, 0x00, 0x00, 0x00, 0x00, 0x00, 0x00, 0x21, 0x04,
  0xff, 0xff, 0xff, 0xff, 0x5a, 0xcb, 0x00, 0x00, 0x00, 0x00, 0xd6, 0xba, 0xff, 0xff, 0xff, 0xff,
  0xff, 0xff, 0xff, 0xff, 0xff, 0xff, 0x84, 0xb6, 0x6c, 0x15, 0xff, 0xff, 0xff, 0xff, 0xff, 0xff,
  0xff, 0xff, 0xff, 0xff, 0xff, 0xff, 0xff, 0xff, 0xff, 0xff, 0xff, 0xff, 0xff, 0xff, 0xff, 0xff,
  0xff, 0xff, 0xff, 0xff, 0xff, 0xff, 0xff, 0xff, 0xff, 0xff, 0xff, 0xff, 0xff, 0xff, 0xff, 0xff,
  0xff, 0xff, 0xff, 0xff, 0xe7, 0x1c, 0x00, 0x00, 0x00, 0x00, 0x00, 0x00, 0x00, 0x00, 0x00, 0x00,
  0x00, 0x00, 0x00, 0x00, 0x00, 0x00, 0xf7, 0x9e, 0xff, 0xff, 0xff, 0xff, 0xff, 0xff, 0xff, 0xff,
  0xff, 0xff, 0x00, 0x00, 0x00, 0x00, 0x00, 0x00, 0x10, 0xa2, 0xff, 0xdf, 0xe9, 0x26, 0xe1, 0x05,
  0xa1, 0x44, 0xa1, 0x64, 0xa1, 0x64, 0xa1, 0x64, 0xa9, 0xe6, 0xff, 0xff, 0xf3, 0xd0, 0xe9, 0x06,
  0xe9, 0x06, 0xe9, 0x06, 0xe9, 0x06, 0xe9, 0x06, 0xe9, 0x06, 0xfe, 0xbb, 0xff, 0xff, 0x63, 0x0c,
  0x00, 0x00, 0x00, 0x00, 0x00, 0x00, 0x00, 0x00, 0x00, 0x00, 0xff, 0xff, 0xff, 0xff, 0xf7, 0xbe,
  0x00, 0x00, 0x00, 0x00, 0x21, 0x24, 0xff, 0xff, 0xff, 0xff, 0x8c, 0x71, 0x00, 0x00, 0x00, 0x00,
  0xad, 0x55, 0xff, 0xff, 0xff, 0xff, 0x08, 0x61, 0x00, 0x00, 0x00, 0x00, 0x00, 0x00, 0x00, 0x00,
  0x00, 0x00, 0x00, 0x00, 0x00, 0x00, 0x21, 0x04, 0xff, 0xff, 0xff, 0xff, 0x5a, 0xcb, 0x00, 0x00,
  0x00, 0x00, 0xd6, 0xba, 0xff, 0xff, 0xff, 0xff, 0xff, 0xff, 0xff, 0xff, 0xff, 0xff, 0x84, 0xb6,
  0x6c, 0x15, 0xff, 0xff, 0xff, 0xff, 0xff, 0xff, 0xff, 0xff, 0xf7, 0xbe, 0x31, 0xa6, 0x31, 0xa6,
  0x52, 0x8a, 0xff, 0xff, 0xff, 0xff, 0x9c, 0xf3, 0x39, 0xc7, 0x39, 0xc7, 0xff, 0xdf, 0xff, 0xff,
  0xff, 0xff, 0x39, 0xc7, 0x39, 0xc7, 0x39, 0xc7, 0x39, 0xc7, 0x39, 0xc7, 0x42, 0x28, 0xc6, 0x38,
  0xc6, 0x38, 0xc6, 0x38, 0xc6, 0x38, 0xc6, 0x38, 0xc6, 0x38, 0xc6, 0x38, 0xc6, 0x38, 0x39, 0xc7,
  0x39, 0xc7, 0x39, 0xc7, 0x31, 0xa6, 0x39, 0xc7, 0x31, 0xa6, 0xc6, 0x38, 0xc6, 0x38, 0xc6, 0x38,
  0xc6, 0x38, 0xff, 0xdf, 0xf4, 0xb3, 0xe9, 0x06, 0xd9, 0x25, 0xa1, 0x64, 0xa1, 0x64, 0xa1, 0x64,
  0xa1, 0x64, 0xdc, 0xf3, 0xe9, 0x06, 0xe9, 0x06, 0xe9, 0x06, 0xe9, 0x06, 0xe9, 0x06, 0xe9, 0x06,
  0xea, 0x4a, 0xef, 0x5d, 0x39, 0xc7, 0x94, 0x92, 0xc6, 0x38, 0xc6, 0x38, 0xc6, 0x38, 0xc6, 0x38,
  0xc6, 0x38, 0x39, 0xc7, 0x31, 0xa6, 0x39, 0xc7, 0xc6, 0x38, 0xc6, 0x38, 0xb5, 0x96, 0x31, 0xa6,
  0x39, 0xc7, 0x73, 0xae, 0xc6, 0x38, 0xc6, 0x38, 0x6b, 0x4d, 0x39, 0xc7, 0x39, 0xc7, 0x00, 0x20,
  0x00, 0x00, 0x00, 0x00, 0x00, 0x00, 0x00, 0x00, 0x00, 0x20, 0xc6, 0x38, 0xc6, 0x38, 0xbd, 0xd7,
  0x39, 0xc7, 0x39, 0xc7, 0x10, 0xa2, 0x00, 0x00, 0x00, 0x00, 0x29, 0x65, 0x39, 0xc7, 0x39, 0xc7,
  0xff, 0xdf, 0xff, 0xff, 0xff, 0xff, 0x84, 0xb6, 0x6c, 0x15, 0xff, 0xff, 0xff, 0xff, 0xff, 0xff,
  0xff, 0xff, 0xf7, 0x9e, 0x00, 0x00, 0x00, 0x00, 0x18, 0xe3, 0xff, 0xff, 0xff, 0xff, 0x7b, 0xef,
  0x00, 0x00, 0x00, 0x00, 0xf7, 0xbe, 0xff, 0xff, 0xff, 0xff, 0x00, 0x20, 0x00, 0x00, 0x00, 0x00,
  0x00, 0x00, 0x00, 0x00, 0x18, 0xe3, 0xff, 0xff, 0xff, 0xff, 0xff, 0xff, 0xff, 0xff, 0xff, 0xff,
  0xff, 0xff, 0xff, 0xff, 0xff, 0xff, 0x08, 0x61, 0x00, 0x00, 0x00, 0x00, 0x00, 0x00, 0x00, 0x00,
  0x00, 0x00, 0xff, 0xff, 0xff, 0xff, 0xff, 0xff, 0xff, 0xff, 0xff, 0xff, 0xff, 0xff, 0xe9, 0x87,
  0xe9, 0x06, 0xb9, 0x44, 0xa1, 0x64, 0xa1, 0x64, 0x99, 0x64, 0xd1, 0x25, 0xe9, 0x06, 0xe9, 0x06,
  0xe9, 0x06, 0xe9, 0x06, 0xe9, 0x06, 0xe9, 0x06, 0xff, 0x7d, 0x10, 0x82, 0x00, 0x00, 0x9c, 0xf3,
  0xff, 0xff, 0xff, 0xff, 0xff, 0xff, 0xff, 0xff, 0xff, 0xff, 0x00, 0x00, 0x00, 0x00, 0x00, 0x20,
  0xff, 0xff, 0xff, 0xff, 0xde, 0xdb, 0x00, 0x00, 0x00, 0x00, 0x6b, 0x6d, 0xff, 0xff, 0xff, 0xff,
  0x52, 0xaa, 0x00, 0x00, 0x00, 0x00, 0x00, 0x00, 0x00, 0x00, 0x00, 0x00, 0x00, 0x00, 0x00, 0x00,
  0x08, 0x41, 0xff, 0xff, 0xff, 0xff, 0xde, 0xfb, 0x00, 0x00, 0x00, 0x00, 0x00, 0x00, 0x00, 0x00,
  0x00, 0x00, 0x00, 0x00, 0x00, 0x00, 0x00, 0x00, 0xff, 0xdf, 0xff, 0xff, 0xff, 0xff, 0x84, 0xb6,
  0x6c, 0x15, 0xff, 0xff, 0xff, 0xff, 0xff, 0xff, 0xff, 0xff, 0xf7, 0x9e, 0x00, 0x00, 0x00, 0x00,
  0x18, 0xe3, 0xff, 0xff, 0xff, 0xff, 0x7b, 0xef, 0x00, 0x00, 0x00, 0x00, 0xf7, 0xbe, 0xff, 0xff,
  0xff, 0xff, 0x00, 0x20, 0x00, 0x00, 0x00, 0x00, 0x00, 0x00, 0x00, 0x00, 0x18, 0xe3, 0xff, 0xff,
  0xff, 0xff, 0xff, 0xff, 0xff, 0xff, 0xff, 0xff, 0xff, 0xff, 0xff, 0xff, 0xff, 0xff, 0x08, 0x61,
  0x00, 0x00, 0x00, 0x00, 0x00, 0x00, 0x00, 0x00, 0x00, 0x00, 0xff, 0xff, 0xff, 0xff, 0xff, 0xff,
  0xff, 0xff, 0xff, 0xff, 0xef, 0x7d, 0xfe, 0x59, 0xe9, 0x06, 0xe9, 0x06, 0xe1, 0x05, 0xd9, 0x25,
  0xe1, 0x05, 0xe9, 0x06, 0xe9, 0x06, 0xe9, 0x06, 0xe9, 0x06, 0xe9, 0x06, 0xe9, 0x06, 0xeb, 0x8f,
  0xde, 0xdb, 0x00, 0x00, 0x00, 0x00, 0x9c, 0xf3, 0xff, 0xff, 0xff, 0xff, 0xff, 0xff, 0xff, 0xff,
  0xff, 0xff, 0x00, 0x00, 0x00, 0x00, 0x00, 0x20, 0xff, 0xff, 0xff, 0xff, 0xde, 0xdb, 0x00, 0x00,
  0x00, 0x00, 0x6b, 0x6d, 0xff, 0xff, 0xff, 0xff, 0x52, 0xaa, 0x00, 0x00, 0x00, 0x00, 0x00, 0x00,
  0x00, 0x00, 0x00, 0x00, 0x00, 0x00, 0x00, 0x00, 0x08, 0x41, 0xff, 0xff, 0xff, 0xff, 0xde, 0xfb,
  0x00, 0x00, 0x00, 0x00, 0x00, 0x00, 0x00, 0x00, 0x00, 0x00, 0x00, 0x00, 0x00, 0x00, 0x00, 0x00,
  0xff, 0xdf, 0xff, 0xff, 0xff, 0xff, 0x84, 0xb6, 0x6c, 0x15, 0xff, 0xff, 0xff, 0xff, 0xff, 0xff,
  0xff, 0xff, 0xff, 0xff, 0xff, 0xff, 0xff, 0xff, 0xde, 0xfb, 0x00, 0x00, 0x00, 0x00, 0x7b, 0xef,
  0xff, 0xff, 0xff, 0xff, 0xff, 0xff, 0xff, 0xff, 0xff, 0xff, 0x00, 0x20, 0x00, 0x00, 0x00, 0x00,
  0xff, 0xff, 0xff, 0xff, 0xff, 0xff, 0xff, 0xff, 0xff, 0xff, 0xff, 0xff, 0xff, 0xff, 0xff, 0xff,
  0x63, 0x0c, 0x00, 0x00, 0x00, 0x00, 0x00, 0x00, 0x00, 0x00, 0x00, 0x00, 0x00, 0x00, 0x00, 0x00,
  0x00, 0x00, 0xff, 0xff, 0xff, 0xff, 0xff, 0xff, 0xff, 0xff, 0xff, 0xff, 0xff, 0xff, 0xff, 0xff,
  0xea, 0x09, 0xe9, 0x06, 0xe9, 0x06, 0xe9, 0x06, 0xe9, 0x06, 0xe9, 0x06, 0xe9, 0x06, 0xe9, 0x06,
  0xe9, 0x06, 0xe9, 0x06, 0xe9, 0x26, 0xff, 0xff, 0xce, 0x59, 0x00, 0x00, 0x00, 0x00, 0x9c, 0xf3,
  0xff, 0xff, 0xff, 0xff, 0x10, 0x82, 0x00, 0x00, 0x00, 0x00, 0xff, 0xff, 0xff, 0xff, 0xff, 0xff,
  0xff, 0xff, 0xff, 0xff, 0xde, 0xdb, 0x00, 0x00, 0x00, 0x00, 0x00, 0x00, 0x00, 0x00, 0x00, 0x00,
  0xad, 0x55, 0xff, 0xff, 0xff, 0xff, 0xff, 0xff, 0xff, 0xff, 0xff, 0xff, 0xff, 0xff, 0xff, 0xff,
  0xf7, 0x9e, 0x00, 0x00, 0x00, 0x00, 0x21, 0x04, 0xff, 0xff, 0xff, 0xff, 0x5a, 0xcb, 0x00, 0x00,
  0x00, 0x00, 0xd6, 0xba, 0xff, 0xff, 0xff, 0xff, 0xff, 0xff, 0xff, 0xff, 0xff, 0xff, 0x84, 0xb6,
  0x6c, 0x15, 0xff, 0xff, 0xff, 0xff, 0xff, 0xff, 0xff, 0xff, 0xff, 0xff, 0xff, 0xff, 0xff, 0xff,
  0xde, 0xfb, 0x00, 0x00, 0x00, 0x00, 0x7b, 0xef, 0xff, 0xff, 0xff, 0xff, 0xff, 0xff, 0xff, 0xff,
  0xff, 0xff, 0x00, 0x20, 0x00, 0x00, 0x00, 0x00, 0xff, 0xff, 0xff, 0xff, 0xff, 0xff, 0xff, 0xff,
  0xff, 0xff, 0xff, 0xff, 0xff, 0xff, 0xff, 0xff, 0x63, 0x0c, 0x00, 0x00, 0x00, 0x00, 0x00, 0x00,
  0x00, 0x00, 0x00, 0x00, 0x00, 0x00, 0x00, 0x00, 0x00, 0x00, 0xff, 0xff, 0xff, 0xff, 0xff, 0xff,
  0xff, 0xff, 0xff, 0xff, 0xff, 0xff, 0xff, 0xff, 0xff, 0x5d, 0xe9, 0x06, 0xe9, 0x06, 0xe9, 0x06,
  0xe9, 0x06, 0xe9, 0x06, 0xe9, 0x06, 0xe9, 0x06, 0xe9, 0x06, 0xe9, 0x06, 0xf5, 0x96, 0xff, 0xff,
  0xce, 0x59, 0x00, 0x00, 0x00, 0x00, 0x9c, 0xf3, 0xff, 0xff, 0xff, 0xff, 0x10, 0x82, 0x00, 0x00,
  0x00, 0x00, 0xff, 0xff, 0xff, 0xff, 0xff, 0xff, 0xff, 0xff, 0xff, 0xff, 0xde, 0xdb, 0x00, 0x00,
  0x00, 0x00, 0x00, 0x00, 0x00, 0x00, 0x00, 0x00, 0xad, 0x55, 0xff, 0xff, 0xff, 0xff, 0xff, 0xff,
  0xff, 0xff, 0xff, 0xff, 0xff, 0xff, 0xff, 0xff, 0xf7, 0x9e, 0x00, 0x00, 0x00, 0x00, 0x21, 0x04,
  0xff, 0xff, 0xff, 0xff, 0x5a, 0xcb, 0x00, 0x00, 0x00, 0x00, 0xd6, 0xba, 0xff, 0xff, 0xff, 0xff,
  0xff, 0xff, 0xff, 0xff, 0xff, 0xff, 0x84, 0xb6, 0x6c, 0x15, 0xff, 0xff, 0xff, 0xff, 0xff, 0xff,
  0xff, 0xff, 0xff, 0xff, 0xff, 0xff, 0xff, 0xff, 0xde, 0xfb, 0x00, 0x00, 0x00, 0x00, 0x7b, 0xef,
  0xff, 0xff, 0xff, 0xff, 0xff, 0xff, 0xff, 0xff, 0xff, 0xff, 0x00, 0x20, 0x00, 0x00, 0x00, 0x00,
  0xff, 0xff, 0xff, 0xff, 0xff, 0xff, 0xff, 0xff, 0xff, 0xff, 0xff, 0xff, 0xff, 0xff, 0xff, 0xff,
  0x63, 0x0c, 0x00, 0x00, 0x00, 0x00, 0x00, 0x00, 0x00, 0x00, 0x00, 0x00, 0x00, 0x00, 0x00, 0x00,
  0x00, 0x00, 0xff, 0xff, 0xff, 0xff, 0xff, 0xff, 0xff, 0xff, 0xff, 0xff, 0xff, 0xff, 0xff, 0xff,
  0xff, 0xff, 0xeb, 0x6e, 0xe9, 0x06, 0xe9, 0x06, 0xe9, 0x06, 0xe9, 0x06, 0xe9, 0x06, 0xe9, 0x06,
  0xe9, 0x06, 0xe9, 0xa8, 0xff, 0xff, 0xff, 0xff, 0xce, 0x59, 0x00, 0x00, 0x00, 0x00, 0x9c, 0xf3,
  0xff, 0xff, 0xff, 0xff, 0x10, 0xa2, 0x00, 0x00, 0x00, 0x00, 0xff, 0xff, 0xff, 0xff, 0xff, 0xff,
  0xff, 0xff, 0xff, 0xff, 0xde, 0xdb, 0x00, 0x00, 0x00, 0x00, 0x00, 0x00, 0x00, 0x00, 0x00, 0x00,
  0xad, 0x55, 0xff, 0xff, 0xff, 0xff, 0xff, 0xff, 0xff, 0xff, 0xff, 0xff, 0xff, 0xff, 0xff, 0xff,
  0xf7, 0x9e, 0x00, 0x00, 0x00, 0x00, 0x21, 0x04, 0xff, 0xff, 0xff, 0xff, 0x5a, 0xcb, 0x00, 0x00,
  0x00, 0x00, 0xd6, 0xba, 0xff, 0xff, 0xff, 0xff, 0xff, 0xff, 0xff, 0xff, 0xff, 0xff, 0x84, 0xb6,
  0x6c, 0x15, 0xff, 0xff, 0xff, 0xff, 0x00, 0x00, 0x00, 0x00, 0x08, 0x41, 0xff, 0xff, 0xff, 0xff,
  0xde, 0xfb, 0x00, 0x00, 0x00, 0x00, 0x7b, 0xef, 0xff, 0xff, 0xff, 0xff, 0x08, 0x41, 0x00, 0x00,
  0x00, 0x00, 0xff, 0xdf, 0xff, 0xff, 0xff, 0xff, 0x00, 0x00, 0x00, 0x00, 0x18, 0xe3, 0xff, 0xff,
  0xff, 0xff, 0xff, 0xff, 0xff, 0xff, 0xff, 0xff, 0x63, 0x0c, 0x00, 0x00, 0x00, 0x00, 0x00, 0x00,
  0x00, 0x00, 0x00, 0x00, 0xff, 0xdf, 0xff, 0xff, 0xff, 0xff, 0xff, 0xff, 0xff, 0xff, 0xe7, 0x3c,
  0x00, 0x00, 0x00, 0x00, 0x94, 0xb2, 0xff, 0xff, 0xff, 0xff, 0xff, 0xdf, 0xe9, 0x26, 0xe9, 0x06,
  0xe9, 0x06, 0xe9, 0x06, 0xe9, 0x06, 0xe9, 0x06, 0xe9, 0x06, 0xff, 0x5d, 0x18, 0xc3, 0x00, 0x00,
  0x00, 0x00, 0x00, 0x00, 0x00, 0x00, 0x9c, 0xf3, 0xff, 0xff, 0xff, 0xff, 0xff, 0xff, 0xff, 0xff,
  0xff, 0xff, 0xff, 0xff, 0xff, 0xff, 0xf7, 0xbe, 0x00, 0x00, 0x00, 0x00, 0x21, 0x24, 0xff, 0xff,
  0xff, 0xff, 0xff, 0xff, 0xff, 0xff, 0xff, 0xff, 0x52, 0xaa, 0x00, 0x00, 0x00, 0x00, 0xf7, 0x9e,
  0xff, 0xff, 0xff, 0xff, 0x00, 0x00, 0x00, 0x00, 0x08, 0x41, 0xff, 0xff, 0xff, 0xff, 0xff, 0xff,
  0xff, 0xff, 0xff, 0xff, 0xff, 0xff, 0xff, 0xff, 0xff, 0xff, 0x29, 0x45, 0x00, 0x00, 0x00, 0x00,
  0xff, 0xdf, 0xff, 0xff, 0xff, 0xff, 0x84, 0xb6, 0x6c, 0x15, 0xff, 0xff, 0xff, 0xff, 0x00, 0x00,
  0x00, 0x00, 0x08, 0x41, 0xff, 0xff, 0xff, 0xff, 0xde, 0xfb, 0x00, 0x00, 0x00, 0x00, 0x7b, 0xef,
  0xff, 0xff, 0xff, 0xff, 0x08, 0x41, 0x00, 0x00, 0x00, 0x00, 0xff, 0xdf, 0xff, 0xff, 0xff, 0xff,
  0x00, 0x00, 0x00, 0x00, 0x18, 0xe3, 0xff, 0xff, 0xff, 0xff, 0xff, 0xff, 0xff, 0xff, 0xff, 0xff,
  0x63, 0x0c, 0x00, 0x00, 0x00, 0x00, 0x00, 0x00, 0x00, 0x00, 0x00, 0x00, 0xff, 0xdf, 0xff, 0xff,
  0xff, 0xff, 0xff, 0xff, 0xff, 0xff, 0xe7, 0x3c, 0x00, 0x00, 0x00, 0x00, 0x94, 0xb2, 0xff, 0xff,
  0xff, 0xff, 0xff, 0xff, 0xf5, 0x14, 0xe9, 0x06, 0xe9, 0x06, 0xe9, 0x06, 0xe9, 0x06, 0xe9, 0x06,
  0xeb, 0x4e, 0xf7, 0xbe, 0x00, 0x00, 0x00, 0x00, 0x00, 0x00, 0x00, 0x00, 0x00, 0x00, 0x9c, 0xf3,
  0xff, 0xff, 0xff, 0xff, 0xff, 0xff, 0xff, 0xff, 0xff, 0xff, 0xff, 0xff, 0xff, 0xff, 0xf7, 0xbe,
  0x00, 0x00, 0x00, 0x00, 0x21, 0x24, 0xff, 0xff, 0xff, 0xff, 0xff, 0xff, 0xff, 0xff, 0xff, 0xff,
  0x52, 0xaa, 0x00, 0x00, 0x00, 0x00, 0xf7, 0x9e, 0xff, 0xff, 0xff, 0xff, 0x00, 0x00, 0x00, 0x00,
  0x08, 0x41, 0xff, 0xff, 0xff, 0xff, 0xff, 0xff, 0xff, 0xff, 0xff, 0xff, 0xff, 0xff, 0xff, 0xff,
  0xff, 0xff, 0x29, 0x45, 0x00, 0x00, 0x00, 0x00, 0xff, 0xdf, 0xff, 0xff, 0xff, 0xff, 0x84, 0xb6,
  0x6c, 0x15, 0xff, 0xff, 0xff, 0xff, 0x00, 0x00, 0x00, 0x00, 0x08, 0x61, 0xff, 0xff, 0xff, 0xff,
  0xde, 0xfb, 0x00, 0x00, 0x00, 0x00, 0x7b, 0xef, 0xff, 0xff, 0xff, 0xff, 0x08, 0x41, 0x00, 0x00,
  0x00, 0x00, 0xff, 0xdf, 0xff, 0xff, 0xff, 0xff, 0x00, 0x00, 0x00, 0x00, 0x21, 0x04, 0xff, 0xff,
  0xff, 0xff, 0xff, 0xff, 0xff, 0xff, 0xff, 0xff, 0x5a, 0xeb, 0x00, 0x00, 0x00, 0x00, 0x00, 0x00,
  0x00, 0x00, 0x00, 0x00, 0xf7, 0xbe, 0xff, 0xff, 0xff, 0xff, 0xff, 0xff, 0xff, 0xff, 0xe7, 0x3c,
  0x00, 0x00, 0x00, 0x00, 0x9c, 0xd3, 0xff, 0xff, 0xff, 0xff, 0xff, 0xff, 0xff, 0xff, 0xe9, 0x87,
  0xe9, 0x06, 0xe9, 0x06, 0xe9, 0x06, 0xe9, 0x46, 0xff, 0xff, 0xf7, 0xbe, 0x00, 0x00, 0x00, 0x00,
  0x00, 0x00, 0x00, 0x00, 0x00, 0x00, 0x9c, 0xf3, 0xff, 0xff, 0xff, 0xff, 0xff, 0xff, 0xff, 0xff,
  0xff, 0xff, 0xff, 0xff, 0xff, 0xff, 0xf7, 0xbe, 0x00, 0x00, 0x00, 0x00, 0x21, 0x24, 0xff, 0xff,
  0xff, 0xff, 0xff, 0xff, 0xff, 0xff, 0xff, 0xff, 0x52, 0xaa, 0x00, 0x00, 0x00, 0x00, 0xf7, 0x9e,
  0xff, 0xff, 0xff, 0xff, 0x00, 0x00, 0x00, 0x00, 0x08, 0x61, 0xff, 0xff, 0xff, 0xff, 0xff, 0xff,
  0xff, 0xff, 0xff, 0xff, 0xff, 0xff, 0xff, 0xff, 0xff, 0xff, 0x29, 0x45, 0x00, 0x00, 0x00, 0x00,
  0xff, 0xdf, 0xff, 0xff, 0xff, 0xff, 0x84, 0xb6, 0x6c, 0x15, 0xff, 0xff, 0xff, 0xff, 0xff, 0xff,
  0xff, 0xff, 0xf7, 0x9e, 0x00, 0x00, 0x00, 0x00, 0x00, 0x00, 0x00, 0x00, 0x00, 0x00, 0x00, 0x00,
  0x00, 0x00, 0x00, 0x00, 0x00, 0x00, 0x00, 0x00, 0x00, 0x00, 0xff, 0xdf, 0xff, 0xff, 0xff, 0xff,
  0xff, 0xff, 0xff, 0xff, 0xff, 0xff, 0xff, 0xff, 0xff, 0xff, 0x8c, 0x51, 0x00, 0x00, 0x00, 0x00,
  0x00, 0x00, 0x00, 0x00, 0x00, 0x00, 0xf7, 0x9e, 0xff, 0xff, 0xff, 0xff, 0x00, 0x20, 0x00, 0x00,
  0x00, 0x00, 0xff, 0xff, 0xff, 0xff, 0xff, 0xff, 0xff, 0xff, 0xff, 0xff, 0xff, 0xff, 0xff, 0xff,
  0xff, 0xff, 0x29, 0x65, 0x4a, 0x69, 0xff, 0xdf, 0xea, 0xed, 0xe9, 0x87, 0xea, 0x09, 0xff, 0x5d,
  0xff, 0xff, 0xff, 0xff, 0xff, 0xff, 0xff, 0xff, 0xce, 0x59, 0x00, 0x00, 0x00, 0x00, 0x9c, 0xf3,
  0xff, 0xff, 0xff, 0xff, 0x10, 0x82, 0x00, 0x00, 0x00, 0x00, 0xff, 0xff, 0xff, 0xff, 0xf7, 0xbe,
  0x00, 0x00, 0x00, 0x00, 0x00, 0x00, 0x00, 0x00, 0x00, 0x00, 0x00, 0x00, 0x00, 0x00, 0x00, 0x00,
  0xad, 0x55, 0xff, 0xff, 0xff, 0xff, 0x08, 0x61, 0x00, 0x00, 0x00, 0x00, 0xff, 0xff, 0xff, 0xff,
  0xf7, 0x9e, 0x00, 0x00, 0x00, 0x00, 0x21, 0x04, 0xff, 0xff, 0xff, 0xff, 0x5a, 0xcb, 0x00, 0x00,
  0x00, 0x00, 0xd6, 0xba, 0xff, 0xff, 0xff, 0xff, 0xff, 0xff, 0xff, 0xff, 0xff, 0xff, 0x84, 0xb6,
  0x6c, 0x15, 0xff, 0xff, 0xff, 0xff, 0xff, 0xff, 0xff, 0xff, 0xf7, 0x9e, 0x00, 0x00, 0x00, 0x00,
  0x00, 0x00, 0x00, 0x00, 0x00, 0x00, 0x00, 0x00, 0x00, 0x00, 0x00, 0x00, 0x00, 0x00, 0x00, 0x00,
  0x00, 0x00, 0xff, 0xdf, 0xff, 0xff, 0xff, 0xff, 0xff, 0xff, 0xff, 0xff, 0xff, 0xff, 0xff, 0xff,
  0xff, 0xff, 0x8c, 0x51, 0x00, 0x00, 0x00, 0x00, 0x00, 0x00, 0x00, 0x00, 0x00, 0x00, 0xf7, 0x9e,
  0xff, 0xff, 0xff, 0xff, 0x00, 0x20, 0x00, 0x00, 0x00, 0x00, 0xff, 0xff, 0xff, 0xff, 0xff, 0xff,
  0xff, 0xff, 0xff, 0xff, 0xff, 0xff, 0xff, 0xff, 0xff, 0xff, 0x29, 0x65, 0x00, 0x00, 0x18, 0xc3,
  0xd6, 0x9a, 0xe7, 0x3c, 0xde, 0xdb, 0xff, 0xff, 0xff, 0xff, 0xff, 0xff, 0xff, 0xff, 0xff, 0xff,
  0xce, 0x59, 0x00, 0x00, 0x00, 0x00, 0x9c, 0xf3, 0xff, 0xff, 0xff, 0xff, 0x10, 0x82, 0x00, 0x00,
  0x00, 0x00, 0xff, 0xff, 0xff, 0xff, 0xf7, 0xbe, 0x00, 0x00, 0x00, 0x00, 0x00, 0x00, 0x00, 0x00,
  0x00, 0x00, 0x00, 0x00, 0x00, 0x00, 0x00, 0x00, 0xad, 0x55, 0xff, 0xff, 0xff, 0xff, 0x08, 0x61,
  0x00, 0x00, 0x00, 0x00, 0xff, 0xff, 0xff, 0xff, 0xf7, 0x9e, 0x00, 0x00, 0x00, 0x00, 0x21, 0x04,
  0xff, 0xff, 0xff, 0xff, 0x5a, 0xcb, 0x00, 0x00, 0x00, 0x00, 0xd6, 0xba, 0xff, 0xff, 0xff, 0xff,
  0xff, 0xff, 0xff, 0xff, 0xff, 0xff, 0x84, 0xb6, 0x6c, 0x15, 0xff, 0xff, 0xff, 0xff, 0xff, 0xff,
  0xff, 0xff, 0xf7, 0xbe, 0x29, 0x45, 0x29, 0x45, 0x29, 0x45, 0x29, 0x45, 0x29, 0x45, 0x10, 0xa2,
  0x00, 0x00, 0x00, 0x00, 0x29, 0x45, 0x29, 0x45, 0x29, 0x45, 0xce, 0x79, 0xd6, 0x9a, 0xd6, 0x9a,
  0xd6, 0x9a, 0xd6, 0x9a, 0xde, 0xdb, 0xff, 0xff, 0xff, 0xff, 0x8c, 0x51, 0x00, 0x00, 0x00, 0x00,
  0x00, 0x00, 0x00, 0x00, 0x00, 0x00, 0xf7, 0x9e, 0xff, 0xff, 0xff, 0xff, 0x29, 0x65, 0x29, 0x45,
  0x29, 0x45, 0xd6, 0x9a, 0xd6, 0x9a, 0xde, 0xdb, 0xff, 0xff, 0xff, 0xff, 0xff, 0xff, 0xff, 0xff,
  0xff, 0xff, 0x4a, 0x69, 0x29, 0x45, 0x29, 0x45, 0x29, 0x45, 0x29, 0x45, 0x29, 0x45, 0xff, 0xff,
  0xff, 0xff, 0xff, 0xff, 0xff, 0xff, 0xff, 0xff, 0xd6, 0xba, 0x29, 0x45, 0x29, 0x45, 0xad, 0x75,
  0xff, 0xff, 0xff, 0xff, 0x39, 0xc7, 0x29, 0x45, 0x29, 0x45, 0xd6, 0x9a, 0xd6, 0x9a, 0xce, 0x79,
  0x29, 0x45, 0x29, 0x45, 0x21, 0x24, 0x00, 0x00, 0x00, 0x00, 0x10, 0x82, 0x29, 0x45, 0x29, 0x45,
  0x9c, 0xd3, 0xd6, 0x9a, 0xd6, 0x9a, 0x31, 0x86, 0x29, 0x45, 0x29, 0x45, 0xd6, 0x9a, 0xd6, 0x9a,
  0xce, 0x79, 0x29, 0x45, 0x29, 0x45, 0x39, 0xe7, 0xd6, 0x9a, 0xd6, 0x9a, 0x63, 0x2c, 0x29, 0x45,
  0x29, 0x45, 0xb5, 0xb6, 0xd6, 0x9a, 0xd6, 0x9a, 0xff, 0xff, 0xff, 0xff, 0xff, 0xff, 0x84, 0xb6,
  0x6c, 0x15, 0xff, 0xff, 0xff, 0xff, 0xff, 0xff, 0xff, 0xff, 0xff, 0xff, 0xff, 0xff, 0xff, 0xff,
  0xff, 0xff, 0xff, 0xff, 0xff, 0xff, 0x7b, 0xef, 0x00, 0x00, 0x00, 0x00, 0xf7, 0xbe, 0xff, 0xff,
  0xff, 0xff, 0x00, 0x20, 0x00, 0x00, 0x00, 0x00, 0x00, 0x00, 0x00, 0x00, 0x18, 0xe3, 0xff, 0xff,
  0xff, 0xff, 0x8c, 0x51, 0x00, 0x00, 0x00, 0x00, 0x00, 0x00, 0x00, 0x00, 0x00, 0x00, 0xf7, 0x9e,
  0xff, 0xff, 0xff, 0xff, 0xff, 0xff, 0xff, 0xff, 0xff, 0xff, 0x00, 0x00, 0x00, 0x00, 0x18, 0xc3,
  0xff, 0xff, 0xff, 0xff, 0xff, 0xff, 0xff, 0xff, 0xff, 0xff, 0xff, 0xff, 0xff, 0xff, 0xff, 0xff,
  0xff, 0xff, 0xff, 0xff, 0xff, 0xff, 0xff, 0xff, 0xff, 0xff, 0xff, 0xff, 0xff, 0xff, 0xff, 0xff,
  0xff, 0xff, 0xff, 0xff, 0xff, 0xff, 0xff, 0xff, 0xff, 0xff, 0xff, 0xff, 0xff, 0xff, 0xff, 0xff,
  0xff, 0xff, 0x00, 0x00, 0x00, 0x00, 0x00, 0x20, 0xff, 0xff, 0xff, 0xff, 0xde, 0xdb, 0x00, 0x00,
  0x00, 0x00, 0x6b, 0x6d, 0xff, 0xff, 0xff, 0xff, 0x52, 0xaa, 0x00, 0x00, 0x00, 0x00, 0xf7, 0x9e,
  0xff, 0xff, 0xff, 0xff, 0x00, 0x00, 0x00, 0x00, 0x08, 0x41, 0xff, 0xff, 0xff, 0xff, 0xde, 0xfb,
  0x00, 0x00, 0x00, 0x00, 0xa5, 0x34, 0xff, 0xff, 0xff, 0xff, 0x29, 0x45, 0x00, 0x00, 0x00, 0x00,
  0xff, 0xdf, 0xff, 0xff, 0xff, 0xff, 0x84, 0xb6, 0x6c, 0x15, 0xff, 0xff, 0xff, 0xff, 0xff, 0xff,
  0xff, 0xff, 0xff, 0xff, 0xff, 0xff, 0xff, 0xff, 0xff, 0xff, 0xff, 0xff, 0xff, 0xff, 0x7b, 0xef,
  0x00, 0x00, 0x00, 0x00, 0xf7, 0xbe, 0xff, 0xff, 0xff, 0xff, 0x00, 0x20, 0x00, 0x00, 0x00, 0x00,
  0x00, 0x00, 0x00, 0x00, 0x18, 0xe3, 0xff, 0xff, 0xff, 0xff, 0x8c, 0x51, 0x00, 0x00, 0x00, 0x00,
  0x00, 0x00, 0x00, 0x00, 0x00, 0x00, 0xf7, 0x9e, 0xff, 0xff, 0xff, 0xff, 0xff, 0xff, 0xff, 0xff,
  0xff, 0xff, 0x00, 0x00, 0x00, 0x00, 0x18, 0xc3, 0xff, 0xff, 0xff, 0xff, 0xff, 0xff, 0xff, 0xff,
  0xff, 0xff, 0xff, 0xff, 0xff, 0xff, 0xff, 0xff, 0xff, 0xff, 0xff, 0xff, 0xff, 0xff, 0xff, 0xff,
  0xff, 0xff, 0xff, 0xff, 0xff, 0xff, 0xff, 0xff, 0xff, 0xff, 0xff, 0xff, 0xff, 0xff, 0xff, 0xff,
  0xff, 0xff, 0xff, 0xff, 0xff, 0xff, 0xff, 0xff, 0xff, 0xff, 0x00, 0x00, 0x00, 0x00, 0x00, 0x20,
  0xff, 0xff, 0xff, 0xff, 0xde, 0xdb, 0x00, 0x00, 0x00, 0x00, 0x6b, 0x6d, 0xff, 0xff, 0xff, 0xff,
  0x52, 0xaa, 0x00, 0x00, 0x00, 0x00, 0xf7, 0x9e, 0xff, 0xff, 0xff, 0xff, 0x00, 0x00, 0x00, 0x00,
  0x08, 0x41, 0xff, 0xff, 0xff, 0xff, 0xde, 0xfb, 0x00, 0x00, 0x00, 0x00, 0xa5, 0x34, 0xff, 0xff,
  0xff, 0xff, 0x29, 0x45, 0x00, 0x00, 0x00, 0x00, 0xff, 0xdf, 0xff, 0xff, 0xff, 0xff, 0x84, 0xb6,
  0x6c, 0x15, 0xff, 0xff, 0xff, 0xff, 0xff, 0xff, 0xff, 0xff, 0xff, 0xff, 0xff, 0xff, 0xff, 0xff,
  0xff, 0xff, 0xff, 0xff, 0xff, 0xff, 0x7b, 0xef, 0x00, 0x00, 0x00, 0x00, 0xf7, 0xbe, 0xff, 0xff,
  0xff, 0xff, 0x00, 0x20, 0x00, 0x00, 0x00, 0x00, 0x4a, 0x49, 0x4a, 0x49, 0x52, 0xaa, 0xb5, 0x96,
  0xb5, 0x96, 0x84, 0x10, 0x4a, 0x49, 0x4a, 0x49, 0x18, 0xc3, 0x00, 0x00, 0x00, 0x00, 0xf7, 0x9e,
  0xff, 0xff, 0xff, 0xff, 0xb5, 0xb6, 0xb5, 0x96, 0xb5, 0x96, 0x00, 0x00, 0x00, 0x00, 0x08, 0x61,
  0xb5, 0x96, 0xb5, 0x96, 0xde, 0xfb, 0xff, 0xff, 0xff, 0xff, 0xff, 0xff, 0xff, 0xff, 0xff, 0xff,
  0xff, 0xff, 0xff, 0xff, 0xff, 0xff, 0xb5, 0x96, 0xb5, 0x96, 0xb5, 0xb6, 0xff, 0xff, 0xff, 0xff,
  0xff, 0xff, 0xff, 0xff, 0xff, 0xff, 0xd6, 0x9a, 0xb5, 0x96, 0xb5, 0x96, 0xb5, 0x96, 0xb5, 0x96,
  0xb5, 0x96, 0x00, 0x00, 0x00, 0x00, 0x00, 0x20, 0xb5, 0x96, 0xb5, 0x96, 0xa5, 0x34, 0x4a, 0x49,
  0x4a, 0x49, 0x7b, 0xcf, 0xb5, 0x96, 0xb5, 0x96, 0x6b, 0x6d, 0x4a, 0x49, 0x4a, 0x49, 0xb5, 0x96,
  0xb5, 0x96, 0xb5, 0x96, 0x4a, 0x49, 0x4a, 0x49, 0x52, 0x8a, 0xff, 0xff, 0xff, 0xff, 0xef, 0x5d,
  0x4a, 0x49, 0x4a, 0x49, 0x94, 0x92, 0xb5, 0x96, 0xb5, 0x96, 0x5a, 0xeb, 0x4a, 0x49, 0x4a, 0x49,
  0xff, 0xdf, 0xff, 0xff, 0xff, 0xff, 0x84, 0xb6, 0x6c, 0x15, 0xff, 0xff, 0xff, 0xff, 0xff, 0xff,
  0xff, 0xff, 0xff, 0xff, 0xff, 0xff, 0xff, 0xff, 0xff, 0xff, 0xff, 0xff, 0xff, 0xff, 0x7b, 0xef,
  0x00, 0x00, 0x00, 0x00, 0xf7, 0xbe, 0xff, 0xff, 0xff, 0xff, 0x00, 0x20, 0x00, 0x00, 0x00, 0x00,
  0xff, 0xff, 0xff, 0xff, 0xe7, 0x1c, 0x00, 0x00, 0x00, 0x00, 0x73, 0xae, 0xff, 0xff, 0xff, 0xff,
  0x63, 0x0c, 0x00, 0x00, 0x00, 0x00, 0xf7, 0x9e, 0xff, 0xff, 0xff, 0xff, 0x00, 0x20, 0x00, 0x00,
  0x00, 0x00, 0x00, 0x00, 0x00, 0x00, 0x00, 0x00, 0x00, 0x00, 0x00, 0x00, 0x94, 0xb2, 0xff, 0xff,
  0xff, 0xff, 0xff, 0xff, 0xff, 0xff, 0xff, 0xff, 0xff, 0xff, 0xff, 0xff, 0xff, 0xff, 0x00, 0x00,
  0x00, 0x00, 0x08, 0x41, 0xff, 0xff, 0xff, 0xff, 0xff, 0xff, 0xff, 0xff, 0xff, 0xff, 0x63, 0x0c,
  0x00, 0x00, 0x00, 0x00, 0x00, 0x00, 0x00, 0x00, 0x00, 0x00, 0x00, 0x00, 0x00, 0x00, 0x00, 0x00,
  0x00, 0x00, 0x00, 0x00, 0x21, 0x24, 0xff, 0xff, 0xff, 0xff, 0x8c, 0x71, 0x00, 0x00, 0x00, 0x00,
  0xad, 0x55, 0xff, 0xff, 0xff, 0xff, 0x08, 0x61, 0x00, 0x00, 0x00, 0x00, 0xff, 0xff, 0xff, 0xff,
  0xff, 0xff, 0xff, 0xff, 0xff, 0xff, 0xff, 0xff, 0xff, 0xff, 0xff, 0xff, 0x5a, 0xcb, 0x00, 0x00,
  0x00, 0x00, 0xd6, 0xba, 0xff, 0xff, 0xff, 0xff, 0xff, 0xff, 0xff, 0xff, 0xff, 0xff, 0x84, 0xb6,
  0x6c, 0x15, 0xff, 0xff, 0xff, 0xff, 0xff, 0xff, 0xff, 0xff, 0xff, 0xff, 0xff, 0xff, 0xff, 0xff,
  0xff, 0xff, 0xff, 0xff, 0xff, 0xff, 0x7b, 0xef, 0x00, 0x00, 0x00, 0x00, 0xf7, 0xbe, 0xff, 0xff,
  0xff, 0xff, 0x00, 0x20, 0x00, 0x00, 0x00, 0x00, 0xff, 0xff, 0xff, 0xff, 0xe7, 0x1c, 0x00, 0x00,
  0x00, 0x00, 0x73, 0xae, 0xff, 0xff, 0xff, 0xff, 0x63, 0x0c, 0x00, 0x00, 0x00, 0x00, 0xf7, 0x9e,
  0xff, 0xff, 0xff, 0xff, 0x00, 0x20, 0x00, 0x00, 0x00, 0x00, 0x00, 0x00, 0x00, 0x00, 0x00, 0x00,
  0x00, 0x00, 0x00, 0x00, 0x94, 0xb2, 0xff, 0xff, 0xff, 0xff, 0xff, 0xff, 0xff, 0xff, 0xff, 0xff,
  0xff, 0xff, 0xff, 0xff, 0xff, 0xff, 0x00, 0x00, 0x00, 0x00, 0x08, 0x41, 0xff, 0xff, 0xff, 0xff,
  0xff, 0xff, 0xff, 0xff, 0xff, 0xff, 0x63, 0x0c, 0x00, 0x00, 0x00, 0x00, 0x00, 0x00, 0x00, 0x00,
  0x00, 0x00, 0x00, 0x00, 0x00, 0x00, 0x00, 0x00, 0x00, 0x00, 0x00, 0x00, 0x21, 0x24, 0xff, 0xff,
  0xff, 0xff, 0x8c, 0x71, 0x00, 0x00, 0x00, 0x00, 0xad, 0x55, 0xff, 0xff, 0xff, 0xff, 0x08, 0x61,
  0x00, 0x00, 0x00, 0x00, 0xff, 0xff, 0xff, 0xff, 0xff, 0xff, 0xff, 0xff, 0xff, 0xff, 0xff, 0xff,
  0xff, 0xff, 0xff, 0xff, 0x5a, 0xcb, 0x00, 0x00, 0x00, 0x00, 0xd6, 0xba, 0xff, 0xff, 0xff, 0xff,
  0xff, 0xff, 0xff, 0xff, 0xff, 0xff, 0x84, 0xb6, 0x6c, 0x15, 0xff, 0xff, 0xff, 0xff, 0x42, 0x08,
  0x42, 0x08, 0x4a, 0x49, 0xff, 0xff, 0xff, 0xff, 0xe7, 0x3c, 0x42, 0x08, 0x42, 0x08, 0x21, 0x04,
  0x00, 0x00, 0x00, 0x00, 0xf7, 0xbe, 0xff, 0xff, 0xff, 0xff, 0x00, 0x20, 0x00, 0x00, 0x00, 0x00,
  0x42, 0x08, 0x42, 0x08, 0x52, 0x8a, 0xbd, 0xd7, 0xbd, 0xf7, 0x84, 0x10, 0x42, 0x08, 0x42, 0x08,
  0x8c, 0x71, 0xbd, 0xd7, 0xbd, 0xd7, 0xff, 0xdf, 0xff, 0xff, 0xff, 0xff, 0x00, 0x20, 0x00, 0x00,
  0x00, 0x00, 0x00, 0x00, 0x00, 0x00, 0x08, 0x61, 0xbd, 0xf7, 0xbd, 0xd7, 0x73, 0x8e, 0x42, 0x08,
  0x42, 0x08, 0x42, 0x08, 0x42, 0x08, 0x42, 0x08, 0x42, 0x08, 0x42, 0x08, 0x42, 0x08, 0x00, 0x00,
  0x00, 0x00, 0x08, 0x41, 0xff, 0xff, 0xff, 0xff, 0xde, 0xdb, 0x42, 0x08, 0x42, 0x08, 0x18, 0xc3,
  0x00, 0x00, 0x00, 0x00, 0x00, 0x00, 0x00, 0x00, 0x00, 0x00, 0xbd, 0xd7, 0xbd, 0xd7, 0xb5, 0xb6,
  0x00, 0x00, 0x00, 0x00, 0x08, 0x41, 0x42, 0x08, 0x42, 0x08, 0x73, 0xae, 0xbd, 0xd7, 0xbd, 0xd7,
  0x6b, 0x6d, 0x42, 0x08, 0x42, 0x08, 0xb5, 0xb6, 0xbd, 0xf7, 0xbd, 0xd7, 0x42, 0x08, 0x42, 0x08,
  0x42, 0x08, 0x42, 0x08, 0x42, 0x08, 0x42, 0x08, 0x42, 0x08, 0x42, 0x08, 0x94, 0x92, 0xbd, 0xd7,
  0xbd, 0xf7, 0x52, 0xaa, 0x42, 0x08, 0x42, 0x08, 0xff, 0xdf, 0xff, 0xff, 0xff, 0xff, 0x84, 0xb6,
  0x6c, 0x15, 0xff, 0xff, 0xff, 0xff, 0x00, 0x00, 0x00, 0x00, 0x08, 0x41, 0xff, 0xff, 0xff, 0xff,
  0xde, 0xfb, 0x00, 0x00, 0x00, 0x00, 0x00, 0x00, 0x00, 0x00, 0x00, 0x00, 0xf7, 0xbe, 0xff, 0xff,
  0xff, 0xff, 0x00, 0x20, 0x00, 0x00, 0x00, 0x00, 0x00, 0x00, 0x00, 0x00, 0x18, 0xe3, 0xff, 0xff,
  0xff, 0xff, 0x8c, 0x51, 0x00, 0x00, 0x00, 0x00, 0x9c, 0xf3, 0xff, 0xff, 0xff, 0xff, 0xff, 0xff,
  0xff, 0xff, 0xff, 0xff, 0x00, 0x20, 0x00, 0x00, 0x00, 0x00, 0x00, 0x00, 0x00, 0x00, 0x18, 0xc3,
  0xff, 0xff, 0xff, 0xff, 0x63, 0x2c, 0x00, 0x00, 0x00, 0x00, 0x00, 0x00, 0x00, 0x00, 0x00, 0x00,
  0x00, 0x00, 0x00, 0x00, 0x00, 0x00, 0x00, 0x00, 0x00, 0x00, 0x08, 0x41, 0xff, 0xff, 0xff, 0xff,
  0xce, 0x59, 0x00, 0x00, 0x00, 0x00, 0x00, 0x00, 0x00, 0x00, 0x00, 0x00, 0x00, 0x00, 0x00, 0x00,
  0x00, 0x00, 0xff, 0xff, 0xff, 0xff, 0xf7, 0xbe, 0x00, 0x00, 0x00, 0x00, 0x00, 0x00, 0x00, 0x00,
  0x00, 0x00, 0x6b, 0x6d, 0xff, 0xff, 0xff, 0xff, 0x52, 0xaa, 0x00, 0x00, 0x00, 0x00, 0xf7, 0x9e,
  0xff, 0xff, 0xff, 0xff, 0x00, 0x00, 0x00, 0x00, 0x00, 0x00, 0x00, 0x00, 0x00, 0x00, 0x00, 0x00,
  0x00, 0x00, 0x00, 0x00, 0xa5, 0x34, 0xff, 0xff, 0xff, 0xff, 0x29, 0x45, 0x00, 0x00, 0x00, 0x00,
  0xff, 0xdf, 0xff, 0xff, 0xff, 0xff, 0x84, 0xb6, 0x6c, 0x15, 0xff, 0xff, 0xff, 0xff, 0x00, 0x00,
  0x00, 0x00, 0x08, 0x41, 0xff, 0xff, 0xff, 0xff, 0xde, 0xfb, 0x00, 0x00, 0x00, 0x00, 0x00, 0x00,
  0x00, 0x00, 0x00, 0x00, 0xf7, 0xbe, 0xff, 0xff, 0xff, 0xff, 0x00, 0x20, 0x00, 0x00, 0x00, 0x00,
  0x00, 0x00, 0x00, 0x00, 0x18, 0xe3, 0xff, 0xff, 0xff, 0xff, 0x8c, 0x51, 0x00, 0x00, 0x00, 0x00,
  0x9c, 0xf3, 0xff, 0xff, 0xff, 0xff, 0xff, 0xff, 0xff, 0xff, 0xff, 0xff, 0x00, 0x20, 0x00, 0x00,
  0x00, 0x00, 0x00, 0x00, 0x00, 0x00, 0x18, 0xc3, 0xff, 0xff, 0xff, 0xff, 0x63, 0x2c, 0x00, 0x00,
  0x00, 0x00, 0x00, 0x00, 0x00, 0x00, 0x00, 0x00, 0x00, 0x00, 0x00, 0x00, 0x00, 0x00, 0x00, 0x00,
  0x00, 0x00, 0x08, 0x41, 0xff, 0xff, 0xff, 0xff, 0xce, 0x59, 0x00, 0x00, 0x00, 0x00, 0x00, 0x00,
  0x00, 0x00, 0x00, 0x00, 0x00, 0x00, 0x00, 0x00, 0x00, 0x00, 0xff, 0xff, 0xff, 0xff, 0xf7, 0xbe,
  0x00, 0x00, 0x00, 0x00, 0x00, 0x00, 0x00, 0x00, 0x00, 0x00, 0x6b, 0x6d, 0xff, 0xff, 0xff, 0xff,
  0x52, 0xaa, 0x00, 0x00, 0x00, 0x00, 0xf7, 0x9e, 0xff, 0xff, 0xff, 0xff, 0x00, 0x00, 0x00, 0x00,
  0x00, 0x00, 0x00, 0x00, 0x00, 0x00, 0x00, 0x00, 0x00, 0x00, 0x00, 0x00, 0xa5, 0x34, 0xff, 0xff,
  0xff, 0xff, 0x29, 0x45, 0x00, 0x00, 0x00, 0x00, 0xff, 0xdf, 0xff, 0xff, 0xff, 0xff, 0x84, 0xb6,
  0x6c, 0x15, 0xff, 0xff, 0xff, 0xff, 0xff, 0xff, 0xff, 0xff, 0xf7, 0x9e, 0x00, 0x00, 0x00, 0x00,
  0x18, 0xe3, 0xff, 0xff, 0xff, 0xff, 0x7b, 0xef, 0x00, 0x00, 0x00, 0x00, 0x00, 0x00, 0x00, 0x00,
  0x00, 0x00, 0x00, 0x00, 0x00, 0x00, 0x00, 0x00, 0xff, 0xff, 0xff, 0xff, 0xff, 0xff, 0xff, 0xff,
  0xff, 0xff, 0x8c, 0x51, 0x00, 0x00, 0x00, 0x00, 0x00, 0x00, 0x00, 0x00, 0x00, 0x00, 0x00, 0x00,
  0x00, 0x00, 0x00, 0x00, 0xff, 0xdf, 0xff, 0xff, 0xff, 0xff, 0x00, 0x00, 0x00, 0x00, 0x00, 0x00,
  0x00, 0x00, 0x00, 0x00, 0x00, 0x00, 0x00, 0x00, 0x00, 0x00, 0x00, 0x00, 0x00, 0x00, 0x00, 0x00,
  0x00, 0x00, 0x00, 0x00, 0x00, 0x00, 0x00, 0x00, 0x00, 0x00, 0x00, 0x00, 0x00, 0x00, 0x00, 0x00,
  0x00, 0x00, 0x00, 0x00, 0x00, 0x00, 0x00, 0x00, 0x00, 0x00, 0x00, 0x00, 0xef, 0x5d, 0xff, 0xff,
  0xff, 0xff, 0xff, 0xff, 0xff, 0xff, 0xf7, 0xbe, 0x00, 0x00, 0x00, 0x00, 0x21, 0x24, 0xff, 0xff,
  0xff, 0xff, 0x8c, 0x71, 0x00, 0x00, 0x00, 0x00, 0xad, 0x55, 0xff, 0xff, 0xff, 0xff, 0x08, 0x61,
  0x00, 0x00, 0x00, 0x00, 0xff, 0xff, 0xff, 0xff, 0xff, 0xff, 0xff, 0xff, 0xff, 0xff, 0xde, 0xfb,
  0x00, 0x00, 0x00, 0x00, 0x00, 0x00, 0x00, 0x00, 0x00, 0x00, 0xd6, 0xba, 0xff, 0xff, 0xff, 0xff,
  0xff, 0xff, 0xff, 0xff, 0xff, 0xff, 0x84, 0xb6, 0x6c, 0x15, 0xff, 0xff, 0xff, 0xff, 0xff, 0xff,
  0xff, 0xff, 0xf7, 0x9e, 0x00, 0x00, 0x00, 0x00, 0x18, 0xe3, 0xff, 0xff, 0xff, 0xff, 0x7b, 0xef,
  0x00, 0x00, 0x00, 0x00, 0x00, 0x00, 0x00, 0x00, 0x00, 0x00, 0x00, 0x00, 0x00, 0x00, 0x00, 0x00,
  0xff, 0xff, 0xff, 0xff, 0xff, 0xff, 0xff, 0xff, 0xff, 0xff, 0x8c, 0x51, 0x00, 0x00, 0x00, 0x00,
  0x00, 0x00, 0x00, 0x00, 0x00, 0x00, 0x00, 0x00, 0x00, 0x00, 0x00, 0x00, 0xff, 0xdf, 0xff, 0xff,
  0xff, 0xff, 0x00, 0x00, 0x00, 0x00, 0x00, 0x00, 0x00, 0x00, 0x00, 0x00, 0x00, 0x00, 0x00, 0x00,
  0x00, 0x00, 0x00, 0x00, 0x00, 0x00, 0x00, 0x00, 0x00, 0x00, 0x00, 0x00, 0x00, 0x00, 0x00, 0x00,
  0x00, 0x00, 0x00, 0x00, 0x00, 0x00, 0x00, 0x00, 0x00, 0x00, 0x00, 0x00, 0x00, 0x00, 0x00, 0x00,
  0x00, 0x00, 0x00, 0x00, 0xef, 0x5d, 0xff, 0xff, 0xff, 0xff, 0xff, 0xff, 0xff, 0xff, 0xf7, 0xbe,
  0x00, 0x00, 0x00, 0x00, 0x21, 0x24, 0xff, 0xff, 0xff, 0xff, 0x8c, 0x71, 0x00, 0x00, 0x00, 0x00,
  0xad, 0x55, 0xff, 0xff, 0xff, 0xff, 0x08, 0x61, 0x00, 0x00, 0x00, 0x00, 0xff, 0xff, 0xff, 0xff,
  0xff, 0xff, 0xff, 0xff, 0xff, 0xff, 0xde, 0xfb, 0x00, 0x00, 0x00, 0x00, 0x00, 0x00, 0x00, 0x00,
  0x00, 0x00, 0xd6, 0xba, 0xff, 0xff, 0xff, 0xff, 0xff, 0xff, 0xff, 0xff, 0xff, 0xff, 0x84, 0xb6,
  0x6c, 0x15, 0xff, 0xff, 0xff, 0xff, 0xff, 0xff, 0xff, 0xff, 0xf7, 0x9e, 0x00, 0x00, 0x00, 0x00,
  0x21, 0x04, 0xff, 0xff, 0xff, 0xff, 0x7b, 0xef, 0x00, 0x00, 0x00, 0x00, 0x00, 0x00, 0x00, 0x00,
  0x00, 0x00, 0x00, 0x00, 0x00, 0x00, 0x00, 0x00, 0xff, 0xff, 0xff, 0xff, 0xff, 0xff, 0xff, 0xff,
  0xff, 0xff, 0x8c, 0x51, 0x00, 0x00, 0x00, 0x00, 0x00, 0x00, 0x00, 0x00, 0x00, 0x00, 0x00, 0x00,
  0x00, 0x00, 0x00, 0x00, 0xf7, 0xbe, 0xff, 0xff, 0xff, 0xff, 0x00, 0x00, 0x00, 0x00, 0x00, 0x00,
  0x00, 0x00, 0x00, 0x00, 0x00, 0x00, 0x00, 0x00, 0x00, 0x00, 0x00, 0x00, 0x00, 0x00, 0x00, 0x00,
  0x00, 0x00, 0x00, 0x00, 0x00, 0x00, 0x00, 0x00, 0x00, 0x00, 0x00, 0x00, 0x00, 0x00, 0x00, 0x00,
  0x00, 0x00, 0x00, 0x00, 0x00, 0x00, 0x00, 0x00, 0x00, 0x00, 0x00, 0x00, 0xef, 0x5d, 0xff, 0xff,
  0xff, 0xff, 0xff, 0xff, 0xff, 0xff, 0xf7, 0xbe, 0x00, 0x00, 0x00, 0x00, 0x21, 0x24, 0xff, 0xff,
  0xff, 0xff, 0x8c, 0x71, 0x00, 0x00, 0x00, 0x00, 0xa5, 0x34, 0xff, 0xff, 0xff, 0xff, 0x08, 0x61,
  0x00, 0x00, 0x00, 0x00, 0xff, 0xff, 0xff, 0xff, 0xff, 0xff, 0xff, 0xff, 0xff, 0xff, 0xde, 0xfb,
  0x00, 0x00, 0x00, 0x00, 0x00, 0x00, 0x00, 0x00, 0x00, 0x00, 0xd6, 0x9a, 0xff, 0xff, 0xff, 0xff,
  0xff, 0xff, 0xff, 0xff, 0xff, 0xff, 0x84, 0xb6, 0x6c, 0x15, 0xff, 0xff, 0xff, 0xff, 0x00, 0x00,
  0x00, 0x00, 0x08, 0x61, 0xff, 0xff, 0xff, 0xff, 0xff, 0xff, 0xff, 0xff, 0xff, 0xff, 0x7b, 0xef,
  0x00, 0x00, 0x00, 0x00, 0x00, 0x00, 0x00, 0x00, 0x00, 0x00, 0x00, 0x00, 0x00, 0x00, 0x00, 0x00,
  0x00, 0x00, 0x00, 0x00, 0x18, 0xe3, 0xff, 0xff, 0xff, 0xff, 0xff, 0xff, 0xff, 0xff, 0xff, 0xff,
  0xff, 0xff, 0xff, 0xff, 0xff, 0xff, 0xff, 0xff, 0xff, 0xff, 0xff, 0xff, 0x00, 0x20, 0x00, 0x00,
  0x00, 0x00, 0xff, 0xff, 0xff, 0xff, 0xff, 0xff, 0xff, 0xff, 0xff, 0xff, 0x63, 0x2c, 0x00, 0x00,
  0x00, 0x00, 0xd6, 0x9a, 0xff, 0xff, 0xff, 0xff, 0x00, 0x20, 0x00, 0x00, 0x00, 0x00, 0x00, 0x00,
  0x00, 0x00, 0x00, 0x00, 0x00, 0x00, 0x00, 0x00, 0x00, 0x00, 0x00, 0x00, 0x00, 0x00, 0x00, 0x00,
  0x00, 0x00, 0x00, 0x00, 0xef, 0x5d, 0xff, 0xff, 0xff, 0xff, 0x00, 0x00, 0x00, 0x00, 0x08, 0x41,
  0xff, 0xff, 0xff, 0xff, 0xde, 0xdb, 0x00, 0x00, 0x00, 0x00, 0x00, 0x00, 0x00, 0x00, 0x00, 0x00,
  0x00, 0x00, 0x00, 0x00, 0x00, 0x00, 0x00, 0x00, 0x00, 0x00, 0x00, 0x00, 0x00, 0x00, 0x00, 0x00,
  0x08, 0x61, 0xff, 0xff, 0xff, 0xff, 0xde, 0xfb, 0x00, 0x00, 0x00, 0x00, 0xa5, 0x14, 0xff, 0xff,
  0xff, 0xff, 0x29, 0x45, 0x00, 0x00, 0x00, 0x00, 0xff, 0xdf, 0xff, 0xff, 0xff, 0xff, 0x84, 0xb6,
  0x6c, 0x15, 0xff, 0xff, 0xff, 0xff, 0x00, 0x00, 0x00, 0x00, 0x08, 0x41, 0xff, 0xff, 0xff, 0xff,
  0xff, 0xff, 0xff, 0xff, 0xff, 0xff, 0x7b, 0xef, 0x00, 0x00, 0x00, 0x00, 0x00, 0x00, 0x00, 0x00,
  0x00, 0x00, 0x00, 0x00, 0x00, 0x00, 0x00, 0x00, 0x00, 0x00, 0x00, 0x00, 0x18, 0xe3, 0xff, 0xff,
  0xff, 0xff, 0xff, 0xff, 0xff, 0xff, 0xff, 0xff, 0xff, 0xff, 0xff, 0xff, 0xff, 0xff, 0xff, 0xff,
  0xff, 0xff, 0xff, 0xff, 0x00, 0x20, 0x00, 0x00, 0x00, 0x00, 0xff, 0xff, 0xff, 0xff, 0xff, 0xff,
  0xff, 0xff, 0xff, 0xff, 0x63, 0x2c, 0x00, 0x00, 0x00, 0x00, 0xd6, 0x9a, 0xff, 0xff, 0xff, 0xff,
  0x00, 0x20, 0x00, 0x00, 0x00, 0x00, 0x00, 0x00, 0x00, 0x00, 0x00, 0x00, 0x00, 0x00, 0x00, 0x00,
  0x00, 0x00, 0x00, 0x00, 0x00, 0x00, 0x00, 0x00, 0x00, 0x00, 0x00, 0x00, 0xef, 0x5d, 0xff, 0xff,
  0xff, 0xff, 0x00, 0x00, 0x00, 0x00, 0x00, 0x20, 0xff, 0xff, 0xff, 0xff, 0xde, 0xdb, 0x00, 0x00,
  0x00, 0x00, 0x00, 0x00, 0x00, 0x00, 0x00, 0x00, 0x00, 0x00, 0x00, 0x00, 0x00, 0x00, 0x00, 0x00,
  0x00, 0x00, 0x00, 0x00, 0x00, 0x00, 0x00, 0x00, 0x08, 0x41, 0xff, 0xff, 0xff, 0xff, 0xde, 0xfb,
  0x00, 0x00, 0x00, 0x00, 0xa5, 0x34, 0xff, 0xff, 0xff, 0xff, 0x29, 0x45, 0x00, 0x00, 0x00, 0x00,
  0xff, 0xdf, 0xff, 0xff, 0xff, 0xff, 0x84, 0xb6, 0x6c, 0x15, 0xff, 0xff, 0xff, 0xff, 0x00, 0x00,
  0x00, 0x00, 0x08, 0x61, 0xff, 0xff, 0xff, 0xff, 0xff, 0xff, 0xff, 0xff, 0xff, 0xff, 0x84, 0x10,
  0x00, 0x00, 0x00, 0x00, 0x00, 0x00, 0x00, 0x00, 0x00, 0x00, 0x00, 0x00, 0x00, 0x00, 0x00, 0x00,
  0x00, 0x00, 0x00, 0x00, 0x21, 0x04, 0xff, 0xff, 0xff, 0xff, 0xff, 0xff, 0xff, 0xdf, 0xff, 0xdf,
  0xff, 0xdf, 0xff, 0xdf, 0xff, 0xdf, 0xff, 0xdf, 0xff, 0xdf, 0xff, 0xdf, 0x00, 0x20, 0x00, 0x00,
  0x00, 0x00, 0xff, 0xff, 0xff, 0xff, 0xff, 0xff, 0xff, 0xff, 0xff, 0xff, 0x63, 0x2c, 0x00, 0x00,
  0x00, 0x00, 0xd6, 0x9a, 0xff, 0xff, 0xff, 0xff, 0x00, 0x20, 0x00, 0x00, 0x00, 0x00, 0x00, 0x00,
  0x00, 0x00, 0x00, 0x00, 0x00, 0x00, 0x00, 0x00, 0x00, 0x00, 0x00, 0x00, 0x00, 0x00, 0x00, 0x00,
  0x00, 0x00, 0x00, 0x00, 0xef, 0x5d, 0xff, 0xdf, 0xff, 0xdf, 0x00, 0x00, 0x00, 0x00, 0x00, 0x20,
  0xff, 0xdf, 0xff, 0xdf, 0xd6, 0xba, 0x00, 0x00, 0x00, 0x00, 0x00, 0x00, 0x00, 0x00, 0x00, 0x00,
  0x00, 0x00, 0x00, 0x00, 0x00, 0x00, 0x00, 0x00, 0x00, 0x00, 0x00, 0x00, 0x00, 0x00, 0x00, 0x00,
  0x08, 0x41, 0xff, 0xdf, 0xff, 0xdf, 0xde, 0xfb, 0x00, 0x00, 0x00, 0x00, 0xa5, 0x34, 0xff, 0xdf,
  0xff, 0xdf, 0x29, 0x65, 0x00, 0x00, 0x00, 0x00, 0xff, 0xdf, 0xff, 0xff, 0xff, 0xff, 0x84, 0xb6,
  0x6c, 0x15, 0xff, 0xff, 0xff, 0xff, 0xff, 0xff, 0xff, 0xff, 0xff, 0xff, 0xff, 0xff, 0xff, 0xff,
  0xff, 0xff, 0xff, 0xff, 0xff, 0xff, 0xff, 0xff, 0xff, 0xff, 0xff, 0xff, 0xff, 0xff, 0xff, 0xff,
  0xff, 0xff, 0xff, 0xff, 0xff, 0xff, 0xff, 0xff, 0xff, 0xff, 0xff, 0xff, 0xff, 0xff, 0xff, 0xff,
  0xff, 0xff, 0x8c, 0x51, 0x00, 0x00, 0x00, 0x00, 0x00, 0x00, 0x00, 0x00, 0x00, 0x00, 0x00, 0x00,
  0x00, 0x00, 0x00, 0x00, 0x00, 0x00, 0x00, 0x00, 0x00, 0x00, 0xff, 0xff, 0xff, 0xff, 0xff, 0xff,
  0xff, 0xff, 0xff, 0xff, 0x63, 0x2c, 0x00, 0x00, 0x00, 0x00, 0xd6, 0x9a, 0xff, 0xff, 0xff, 0xff,
  0x00, 0x20, 0x00, 0x00, 0x00, 0x00, 0x00, 0x00, 0x00, 0x00, 0x08, 0x41, 0xff, 0xff, 0xff, 0xff,
  0xce, 0x59, 0x00, 0x00, 0x00, 0x00, 0x9c, 0xf3, 0xff, 0xff, 0xff, 0xff, 0x10, 0x82, 0x00, 0x00,
  0x00, 0x00, 0x00, 0x00, 0x00, 0x00, 0x00, 0x00, 0x00, 0x00, 0x00, 0x00, 0x00, 0x00, 0x00, 0x00,
  0x00, 0x00, 0x6b, 0x6d, 0xff, 0xff, 0xff, 0xff, 0xff, 0xff, 0xff, 0xff, 0xff, 0xff, 0xff, 0xff,
  0xff, 0xff, 0xff, 0xff, 0x00, 0x00, 0x00, 0x00, 0x00, 0x00, 0x00, 0x00, 0x00, 0x00, 0x21, 0x04,
  0xff, 0xff, 0xff, 0xff, 0x5a, 0xcb, 0x00, 0x00, 0x00, 0x00, 0xd6, 0xba, 0xff, 0xff, 0xff, 0xff,
  0xff, 0xff, 0xff, 0xff, 0xff, 0xff, 0x84, 0xb6, 0x6c, 0x15, 0xff, 0xff, 0xff, 0xff, 0xff, 0xff,
  0xff, 0xff, 0xff, 0xff, 0xff, 0xff, 0xff, 0xff, 0xff, 0xff, 0xff, 0xff, 0xff, 0xff, 0xff, 0xff,
  0xff, 0xff, 0xff, 0xff, 0xff, 0xff, 0xff, 0xff, 0xff, 0xff, 0xff, 0xff, 0xff, 0xff, 0xff, 0xff,
  0xff, 0xff, 0xff, 0xff, 0xff, 0xff, 0xff, 0xff, 0xff, 0xff, 0x8c, 0x51, 0x00, 0x00, 0x00, 0x00,
  0x00, 0x00, 0x00, 0x00, 0x00, 0x00, 0x00, 0x00, 0x00, 0x00, 0x00, 0x00, 0x00, 0x00, 0x00, 0x00,
  0x00, 0x00, 0xff, 0xff, 0xff, 0xff, 0xff, 0xff, 0xff, 0xff, 0xff, 0xff, 0x63, 0x2c, 0x00, 0x00,
  0x00, 0x00, 0xd6, 0x9a, 0xff, 0xff, 0xff, 0xff, 0x00, 0x20, 0x00, 0x00, 0x00, 0x00, 0x00, 0x00,
  0x00, 0x00, 0x08, 0x41, 0xff, 0xff, 0xff, 0xff, 0xce, 0x59, 0x00, 0x00, 0x00, 0x00, 0x9c, 0xf3,
  0xff, 0xff, 0xff, 0xff, 0x10, 0x82, 0x00, 0x00, 0x00, 0x00, 0x00, 0x00, 0x00, 0x00, 0x00, 0x00,
  0x00, 0x00, 0x00, 0x00, 0x00, 0x00, 0x00, 0x00, 0x00, 0x00, 0x6b, 0x6d, 0xff, 0xff, 0xff, 0xff,
  0xff, 0xff, 0xff, 0xff, 0xff, 0xff, 0xff, 0xff, 0xff, 0xff, 0xff, 0xff, 0x00, 0x00, 0x00, 0x00,
  0x00, 0x00, 0x00, 0x00, 0x00, 0x00, 0x21, 0x04, 0xff, 0xff, 0xff, 0xff, 0x5a, 0xcb, 0x00, 0x00,
  0x00, 0x00, 0xd6, 0xba, 0xff, 0xff, 0xff, 0xff, 0xff, 0xff, 0xff, 0xff, 0xff, 0xff, 0x84, 0xb6,
  0x6c, 0x15, 0xff, 0xff, 0xff, 0xff, 0xbd, 0xd7, 0xb5, 0xb6, 0xbd, 0xd7, 0xbd, 0xd7, 0xbd, 0xd7,
  0xbd, 0xd7, 0xb5, 0xb6, 0xbd, 0xd7, 0xbd, 0xd7, 0xbd, 0xd7, 0xbd, 0xd7, 0xbd, 0xd7, 0xbd, 0xd7,
  0xbd, 0xd7, 0xbd, 0xd7, 0xbd, 0xd7, 0xb5, 0xb6, 0xbd, 0xd7, 0xbd, 0xd7, 0xc6, 0x18, 0xff, 0xff,
  0xff, 0xff, 0x8c, 0x51, 0x00, 0x00, 0x00, 0x00, 0x29, 0x45, 0x42, 0x28, 0x42, 0x28, 0x00, 0x00,
  0x00, 0x00, 0x00, 0x00, 0x42, 0x28, 0x42, 0x28, 0x42, 0x28, 0xff, 0xff, 0xff, 0xff, 0xff, 0xdf,
  0xb5, 0xb6, 0xbd, 0xd7, 0x73, 0xae, 0x42, 0x28, 0x42, 0x28, 0xa5, 0x34, 0xbd, 0xd7, 0xbd, 0xd7,
  0x00, 0x00, 0x00, 0x00, 0x00, 0x00, 0x42, 0x28, 0x42, 0x28, 0x4a, 0x49, 0xbd, 0xd7, 0xb5, 0xb6,
  0x94, 0x92, 0x00, 0x00, 0x00, 0x00, 0x9c, 0xf3, 0xff, 0xff, 0xff, 0xff, 0x52, 0xaa, 0x42, 0x28,
  0x42, 0x28, 0x00, 0x00, 0x00, 0x00, 0x00, 0x00, 0x42, 0x28, 0x42, 0x28, 0x39, 0xe7, 0x00, 0x00,
  0x00, 0x00, 0x6b, 0x6d, 0xff, 0xff, 0xff, 0xff, 0xd6, 0x9a, 0xbd, 0xd7, 0xb5, 0xb6, 0xff, 0xdf,
  0xff, 0xff, 0xff, 0xff, 0x00, 0x00, 0x00, 0x00, 0x00, 0x00, 0x42, 0x28, 0x42, 0x28, 0x5a, 0xeb,
  0xff, 0xff, 0xff, 0xff, 0x84, 0x30, 0x42, 0x28, 0x42, 0x28, 0xe7, 0x1c, 0xff, 0xff, 0xff, 0xff,
  0xff, 0xff, 0xff, 0xff, 0xff, 0xff, 0x84, 0xb6, 0x6c, 0x15, 0xff, 0xff, 0xff, 0xff, 0x00, 0x00,
  0x00, 0x00, 0x00, 0x00, 0x00, 0x00, 0x00, 0x00, 0x00, 0x00, 0x00, 0x00, 0x00, 0x00, 0x00, 0x00,
  0x00, 0x00, 0x00, 0x00, 0x00, 0x00, 0x00, 0x00, 0x00, 0x00, 0x00, 0x00, 0x00, 0x00, 0x00, 0x00,
  0x00, 0x00, 0x00, 0x00, 0x18, 0xe3, 0xff, 0xff, 0xff, 0xff, 0x8c, 0x51, 0x00, 0x00, 0x00, 0x00,
  0x9c, 0xf3, 0xff, 0xff, 0xff, 0xff, 0x08, 0x61, 0x00, 0x00, 0x00, 0x00, 0xff, 0xdf, 0xff, 0xff,
  0xff, 0xff, 0xff, 0xff, 0xff, 0xff, 0xe7, 0x3c, 0x00, 0x00, 0x00, 0x00, 0x94, 0xb2, 0xff, 0xff,
  0xff, 0xff, 0x29, 0x65, 0x00, 0x00, 0x00, 0x00, 0x00, 0x00, 0x00, 0x00, 0x00, 0x00, 0xff, 0xff,
  0xff, 0xff, 0xf7, 0xbe, 0x00, 0x00, 0x00, 0x00, 0x00, 0x00, 0x00, 0x00, 0x00, 0x00, 0x9c, 0xf3,
  0xff, 0xff, 0xff, 0xff, 0xff, 0xff, 0xff, 0xff, 0xff, 0xff, 0x00, 0x00, 0x00, 0x00, 0x00, 0x20,
  0xff, 0xff, 0xff, 0xff, 0xde, 0xdb, 0x00, 0x00, 0x00, 0x00, 0x6b, 0x6d, 0xff, 0xff, 0xff, 0xff,
  0x52, 0xaa, 0x00, 0x00, 0x00, 0x00, 0xf7, 0x9e, 0xff, 0xff, 0xff, 0xff, 0x00, 0x00, 0x00, 0x00,
  0x08, 0x41, 0xff, 0xff, 0xff, 0xff, 0xff, 0xff, 0xff, 0xff, 0xff, 0xff, 0xff, 0xff, 0xff, 0xff,
  0xff, 0xff, 0xff, 0xff, 0xff, 0xff, 0xff, 0xff, 0xff, 0xff, 0xff, 0xff, 0xff, 0xff, 0x84, 0xb6,
  0x6c, 0x15, 0xff, 0xff, 0xff, 0xff, 0x00, 0x00, 0x00, 0x00, 0x00, 0x00, 0x00, 0x00, 0x00, 0x00,
  0x00, 0x00, 0x00, 0x00, 0x00, 0x00, 0x00, 0x00, 0x00, 0x00, 0x00, 0x00, 0x00, 0x00, 0x00, 0x00,
  0x00, 0x00, 0x00, 0x00, 0x00, 0x00, 0x00, 0x00, 0x00, 0x00, 0x00, 0x00, 0x18, 0xe3, 0xff, 0xff,
  0xff, 0xff, 0x8c, 0x51, 0x00, 0x00, 0x00, 0x00, 0x9c, 0xf3, 0xff, 0xff, 0xff, 0xff, 0x08, 0x61,
  0x00, 0x00, 0x00, 0x00, 0xff, 0xdf, 0xff, 0xff, 0xff, 0xff, 0xff, 0xff, 0xff, 0xff, 0xe7, 0x3c,
  0x00, 0x00, 0x00, 0x00, 0x94, 0xb2, 0xff, 0xff, 0xff, 0xff, 0x29, 0x65, 0x00, 0x00, 0x00, 0x00,
  0x00, 0x00, 0x00, 0x00, 0x00, 0x00, 0xff, 0xff, 0xff, 0xff, 0xf7, 0xbe, 0x00, 0x00, 0x00, 0x00,
  0x00, 0x00, 0x00, 0x00, 0x00, 0x00, 0x9c, 0xf3, 0xff, 0xff, 0xff, 0xff, 0xff, 0xff, 0xff, 0xff,
  0xff, 0xff, 0x00, 0x00, 0x00, 0x00, 0x00, 0x20, 0xff, 0xff, 0xff, 0xff, 0xde, 0xdb, 0x00, 0x00,
  0x00, 0x00, 0x6b, 0x6d, 0xff, 0xff, 0xff, 0xff, 0x52, 0xaa, 0x00, 0x00, 0x00, 0x00, 0xf7, 0x9e,
  0xff, 0xff, 0xff, 0xff, 0x00, 0x00, 0x00, 0x00, 0x08, 0x41, 0xff, 0xff, 0xff, 0xff, 0xff, 0xff,
  0xff, 0xff, 0xff, 0xff, 0xff, 0xff, 0xff, 0xff, 0xff, 0xff, 0xff, 0xff, 0xff, 0xff, 0xff, 0xff,
  0xff, 0xff, 0xff, 0xff, 0xff, 0xff, 0x84, 0xb6, 0x6c, 0x15, 0xff, 0xff, 0xff, 0xff, 0x00, 0x00,
  0x00, 0x00, 0x00, 0x20, 0x8c, 0x71, 0x8c, 0x71, 0x8c, 0x71, 0x8c, 0x71, 0x8c, 0x71, 0x8c, 0x71,
  0x8c, 0x71, 0x8c, 0x71, 0x8c, 0x71, 0x8c, 0x71, 0x8c, 0x71, 0x8c, 0x71, 0x8c, 0x71, 0x8c, 0x71,
  0x00, 0x00, 0x00, 0x00, 0x18, 0xe3, 0xff, 0xff, 0xff, 0xff, 0x8c, 0x51, 0x00, 0x00, 0x00, 0x00,
  0x9c, 0xf3, 0xff, 0xff, 0xff, 0xff, 0x08, 0x61, 0x00, 0x00, 0x00, 0x00, 0x6b, 0x6d, 0x73, 0x8e,
  0x73, 0x8e, 0xff, 0xff, 0xff, 0xff, 0xf7, 0xbe, 0x8c, 0x71, 0x8c, 0x71, 0xd6, 0x9a, 0xff, 0xff,
  0xff, 0xff, 0xa5, 0x14, 0x8c, 0x71, 0x8c, 0x71, 0x8c, 0x71, 0x8c, 0x71, 0x8c, 0x71, 0x73, 0x8e,
  0x73, 0x8e, 0x73, 0x8e, 0x8c, 0x71, 0x8c, 0x71, 0x8c, 0x71, 0x8c, 0x71, 0x8c, 0x71, 0x7b, 0xcf,
  0x73, 0x8e, 0x73, 0x8e, 0x73, 0x8e, 0x73, 0x8e, 0x73, 0x8e, 0x00, 0x00, 0x00, 0x00, 0x00, 0x00,
  0x73, 0x8e, 0x73, 0x8e, 0x5a, 0xeb, 0x00, 0x00, 0x00, 0x00, 0x6b, 0x6d, 0xff, 0xff, 0xff, 0xff,
  0xb5, 0xb6, 0x8c, 0x71, 0x8c, 0x71, 0xff, 0xdf, 0xff, 0xff, 0xff, 0xff, 0x00, 0x00, 0x00, 0x00,
  0x00, 0x20, 0x73, 0x8e, 0x73, 0x8e, 0x84, 0x10, 0xff, 0xff, 0xff, 0xff, 0xff, 0xff, 0xff, 0xff,
  0xff, 0xff, 0xff, 0xff, 0xff, 0xff, 0xff, 0xff, 0xff, 0xff, 0xff, 0xff, 0xff, 0xff, 0x84, 0xb6,
  0x6c, 0x15, 0xff, 0xff, 0xff, 0xff, 0x00, 0x00, 0x00, 0x00, 0x08, 0x41, 0xff, 0xff, 0xff, 0xff,
  0xff, 0xff, 0xff, 0xff, 0xff, 0xff, 0xff, 0xff, 0xff, 0xff, 0xff, 0xff, 0xff, 0xff, 0xff, 0xff,
  0xff, 0xff, 0xff, 0xff, 0xff, 0xff, 0xff, 0xff, 0x00, 0x00, 0x00, 0x00, 0x18, 0xe3, 0xff, 0xff,
  0xff, 0xff, 0x8c, 0x51, 0x00, 0x00, 0x00, 0x00, 0x9c, 0xf3, 0xff, 0xff, 0xff, 0xff, 0x08, 0x61,
  0x00, 0x00, 0x00, 0x00, 0x00, 0x00, 0x00, 0x00, 0x00, 0x00, 0xff, 0xff, 0xff, 0xff, 0xff, 0xff,
  0xff, 0xff, 0xff, 0xff, 0xff, 0xff, 0xff, 0xff, 0xff, 0xff, 0xff, 0xff, 0xff, 0xff, 0xff, 0xff,
  0xff, 0xff, 0xff, 0xff, 0xff, 0xff, 0x00, 0x00, 0x00, 0x00, 0x08, 0x41, 0xff, 0xff, 0xff, 0xff,
  0xff, 0xff, 0xff, 0xff, 0xff, 0xff, 0x63, 0x0c, 0x00, 0x00, 0x00, 0x00, 0x00, 0x00, 0x00, 0x00,
  0x00, 0x00, 0x00, 0x00, 0x00, 0x00, 0x00, 0x00, 0x00, 0x00, 0x00, 0x00, 0x00, 0x00, 0x00, 0x00,
  0x00, 0x00, 0x6b, 0x6d, 0xff, 0xff, 0xff, 0xff, 0xff, 0xff, 0xff, 0xff, 0xff, 0xff, 0xff, 0xff,
  0xff, 0xff, 0xff, 0xff, 0x00, 0x00, 0x00, 0x00, 0x00, 0x00, 0x00, 0x00, 0x00, 0x00, 0x21, 0x04,
  0xff, 0xff, 0xff, 0xff, 0xff, 0xff, 0xff, 0xff, 0xff, 0xff, 0xff, 0xff, 0xff, 0xff, 0xff, 0xff,
  0xff, 0xff, 0xff, 0xff, 0xff, 0xff, 0x84, 0xb6, 0x6c, 0x15, 0xff, 0xff, 0xff, 0xff, 0x00, 0x00,
  0x00, 0x00, 0x08, 0x41, 0xff, 0xff, 0xff, 0xff, 0xff, 0xff, 0xff, 0xff, 0xff, 0xff, 0xff, 0xff,
  0xff, 0xff, 0xff, 0xff, 0xff, 0xff, 0xff, 0xff, 0xff, 0xff, 0xff, 0xff, 0xff, 0xff, 0xff, 0xff,
  0x00, 0x00, 0x00, 0x00, 0x18, 0xe3, 0xff, 0xff, 0xff, 0xff, 0x8c, 0x51, 0x00, 0x00, 0x00, 0x00,
  0x9c, 0xf3, 0xff, 0xff, 0xff, 0xff, 0x08, 0x61, 0x00, 0x00, 0x00, 0x00, 0x00, 0x00, 0x00, 0x00,
  0x00, 0x00, 0xff, 0xff, 0xff, 0xff, 0xff, 0xff, 0xff, 0xff, 0xff, 0xff, 0xff, 0xff, 0xff, 0xff,
  0xff, 0xff, 0xff, 0xff, 0xff, 0xff, 0xff, 0xff, 0xff, 0xff, 0xff, 0xff, 0xff, 0xff, 0x00, 0x00,
  0x00, 0x00, 0x08, 0x41, 0xff, 0xff, 0xff, 0xff, 0xff, 0xff, 0xff, 0xff, 0xff, 0xff, 0x63, 0x0c,
  0x00, 0x00, 0x00, 0x00, 0x00, 0x00, 0x00, 0x00, 0x00, 0x00, 0x00, 0x00, 0x00, 0x00, 0x00, 0x00,
  0x00, 0x00, 0x00, 0x00, 0x00, 0x00, 0x00, 0x00, 0x00, 0x00, 0x6b, 0x6d, 0xff, 0xff, 0xff, 0xff,
  0xff, 0xff, 0xff, 0xff, 0xff, 0xff, 0xff, 0xff, 0xff, 0xff, 0xff, 0xff, 0x00, 0x00, 0x00, 0x00,
  0x00, 0x00, 0x00, 0x00, 0x00, 0x00, 0x21, 0x04, 0xff, 0xff, 0xff, 0xff, 0xff, 0xff, 0xff, 0xff,
  0xff, 0xff, 0xff, 0xff, 0xff, 0xff, 0xff, 0xff, 0xff, 0xff, 0xff, 0xff, 0xff, 0xff, 0x84, 0xb6,
  0x6c, 0x15, 0xff, 0xff, 0xff, 0xff, 0x00, 0x00, 0x00, 0x00, 0x08, 0x41, 0xff, 0xff, 0xff, 0xff,
  0xe7, 0x3c, 0x31, 0xa6, 0x31, 0xa6, 0x31, 0xa6, 0x31, 0xa6, 0x31, 0xa6, 0x31, 0xa6, 0x31, 0xa6,
  0x31, 0xa6, 0xff, 0xdf, 0xff, 0xff, 0xff, 0xff, 0x00, 0x00, 0x00, 0x00, 0x18, 0xe3, 0xff, 0xff,
  0xff, 0xff, 0x8c, 0x51, 0x00, 0x00, 0x00, 0x00, 0x21, 0x04, 0x31, 0xa6, 0x31, 0xa6, 0xc6, 0x18,
  0xce, 0x59, 0xce, 0x59, 0xce, 0x59, 0xce, 0x59, 0xce, 0x59, 0x31, 0xa6, 0x31, 0xa6, 0x4a, 0x49,
  0xff, 0xff, 0xff, 0xff, 0xff, 0xff, 0xff, 0xff, 0xff, 0xff, 0xff, 0xff, 0xff, 0xff, 0xff, 0xff,
  0x39, 0xc7, 0x31, 0xa6, 0x31, 0xa6, 0xce, 0x59, 0xce, 0x59, 0xc6, 0x18, 0x31, 0xa6, 0x31, 0xa6,
  0x5a, 0xeb, 0xff, 0xff, 0xff, 0xff, 0x63, 0x0c, 0x00, 0x00, 0x00, 0x00, 0x00, 0x00, 0x00, 0x00,
  0x00, 0x00, 0x00, 0x00, 0x00, 0x00, 0x00, 0x20, 0xce, 0x59, 0xce, 0x59, 0xad, 0x55, 0x00, 0x00,
  0x00, 0x00, 0x10, 0xa2, 0x31, 0xa6, 0x31, 0xa6, 0x31, 0xa6, 0x31, 0xa6, 0x31, 0xa6, 0x31, 0xa6,
  0x31, 0xa6, 0x31, 0xa6, 0x00, 0x00, 0x00, 0x00, 0x00, 0x00, 0x00, 0x00, 0x00, 0x00, 0x21, 0x04,
  0xff, 0xff, 0xff, 0xff, 0x7b, 0xef, 0x31, 0xa6, 0x31, 0xa6, 0xde, 0xfb, 0xff, 0xff, 0xff, 0xff,
  0xff, 0xff, 0xff, 0xff, 0xff, 0xff, 0x84, 0xb6, 0x6c, 0x15, 0xff, 0xff, 0xff, 0xff, 0x00, 0x00,
  0x00, 0x00, 0x08, 0x41, 0xff, 0xff, 0xff, 0xff, 0xde, 0xfb, 0x00, 0x00, 0x00, 0x00, 0x00, 0x00,
  0x00, 0x00, 0x00, 0x00, 0x00, 0x00, 0x00, 0x00, 0x00, 0x00, 0xff, 0xdf, 0xff, 0xff, 0xff, 0xff,
  0x00, 0x00, 0x00, 0x00, 0x18, 0xe3, 0xff, 0xff, 0xff, 0xff, 0x8c, 0x51, 0x00, 0x00, 0x00, 0x00,
  0x00, 0x00, 0x00, 0x00, 0x00, 0x00, 0xf7, 0x9e, 0xff, 0xff, 0xff, 0xff, 0xff, 0xff, 0xff, 0xff,
  0xff, 0xff, 0x00, 0x00, 0x00, 0x00, 0x18, 0xc3, 0xff, 0xff, 0xff, 0xff, 0xff, 0xff, 0xff, 0xff,
  0xff, 0xff, 0xff, 0xff, 0xff, 0xff, 0xff, 0xff, 0x00, 0x20, 0x00, 0x00, 0x00, 0x00, 0xff, 0xff,
  0xff, 0xff, 0xf7, 0xbe, 0x00, 0x00, 0x00, 0x00, 0x31, 0x86, 0xff, 0xff, 0xff, 0xff, 0x63, 0x0c,
  0x00, 0x00, 0x00, 0x00, 0x00, 0x00, 0x00, 0x00, 0x00, 0x00, 0x00, 0x00, 0x00, 0x00, 0x00, 0x20,
  0xff, 0xff, 0xff, 0xff, 0xde, 0xdb, 0x00, 0x00, 0x00, 0x00, 0x00, 0x00, 0x00, 0x00, 0x00, 0x00,
  0x00, 0x00, 0x00, 0x00, 0x00, 0x00, 0x00, 0x00, 0x00, 0x00, 0x00, 0x00, 0x00, 0x00, 0x00, 0x00,
  0x00, 0x00, 0x00, 0x00, 0x00, 0x00, 0x21, 0x04, 0xff, 0xff, 0xff, 0xff, 0x5a, 0xcb, 0x00, 0x00,
  0x00, 0x00, 0xd6, 0xba, 0xff, 0xff, 0xff, 0xff, 0xff, 0xff, 0xff, 0xff, 0xff, 0xff, 0x84, 0xb6,
  0x6c, 0x15, 0xff, 0xff, 0xff, 0xff, 0x00, 0x00, 0x00, 0x00, 0x08, 0x41, 0xff, 0xff, 0xff, 0xff,
  0xde, 0xfb, 0x00, 0x00, 0x00, 0x00, 0x00, 0x00, 0x00, 0x00, 0x00, 0x00, 0x00, 0x00, 0x00, 0x00,
  0x00, 0x00, 0xff, 0xdf, 0xff, 0xff, 0xff, 0xff, 0x00, 0x00, 0x00, 0x00, 0x18, 0xe3, 0xff, 0xff,
  0xff, 0xff, 0x8c, 0x51, 0x00, 0x00, 0x00, 0x00, 0x00, 0x00, 0x00, 0x00, 0x00, 0x00, 0xf7, 0x9e,
  0xff, 0xff, 0xff, 0xff, 0xff, 0xff, 0xff, 0xff, 0xff, 0xff, 0x00, 0x00, 0x00, 0x00, 0x18, 0xc3,
  0xff, 0xff, 0xff, 0xff, 0xff, 0xff, 0xff, 0xff, 0xff, 0xff, 0xff, 0xff, 0xff, 0xff, 0xff, 0xff,
  0x00, 0x20, 0x00, 0x00, 0x00, 0x00, 0xff, 0xff, 0xff, 0xff, 0xf7, 0xbe, 0x00, 0x00, 0x00, 0x00,
  0x31, 0x86, 0xff, 0xff, 0xff, 0xff, 0x63, 0x0c, 0x00, 0x00, 0x00, 0x00, 0x00, 0x00, 0x00, 0x00,
  0x00, 0x00, 0x00, 0x00, 0x00, 0x00, 0x00, 0x20, 0xff, 0xff, 0xff, 0xff, 0xde, 0xdb, 0x00, 0x00,
  0x00, 0x00, 0x00, 0x00, 0x00, 0x00, 0x00, 0x00, 0x00, 0x00, 0x00, 0x00, 0x00, 0x00, 0x00, 0x00,
  0x00, 0x00, 0x00, 0x00, 0x00, 0x00, 0x00, 0x00, 0x00, 0x00, 0x00, 0x00, 0x00, 0x00, 0x21, 0x04,
  0xff, 0xff, 0xff, 0xff, 0x5a, 0xcb, 0x00, 0x00, 0x00, 0x00, 0xd6, 0xba, 0xff, 0xff, 0xff, 0xff,
  0xff, 0xff, 0xff, 0xff, 0xff, 0xff, 0x84, 0xb6, 0x6c, 0x15, 0xff, 0xff, 0xff, 0xff, 0x00, 0x00,
  0x00, 0x00, 0x08, 0x41, 0xff, 0xff, 0xff, 0xff, 0xde, 0xfb, 0x00, 0x00, 0x00, 0x00, 0x00, 0x00,
  0x00, 0x00, 0x00, 0x00, 0x00, 0x00, 0x00, 0x00, 0x00, 0x00, 0xff, 0xdf, 0xff, 0xff, 0xff, 0xff,
  0x00, 0x00, 0x00, 0x00, 0x18, 0xe3, 0xff, 0xff, 0xff, 0xff, 0xff, 0xff, 0xff, 0xff, 0xff, 0xff,
  0xff, 0xff, 0xff, 0xff, 0xff, 0xff, 0xff, 0xff, 0xff, 0xff, 0xff, 0xff, 0x00, 0x20, 0x00, 0x00,
  0x00, 0x00, 0x00, 0x00, 0x00, 0x00, 0x00, 0x00, 0x00, 0x00, 0x00, 0x00, 0x9c, 0xd3, 0xff, 0xff,
  0xff, 0xff, 0xff, 0xff, 0xff, 0xff, 0xff, 0xff, 0x00, 0x20, 0x00, 0x00, 0x00, 0x00, 0x00, 0x00,
  0x00, 0x00, 0x08, 0x61, 0xff, 0xff, 0xff, 0xff, 0xff, 0xff, 0xff, 0xff, 0xff, 0xff, 0x63, 0x0c,
  0x00, 0x00, 0x00, 0x00, 0x00, 0x00, 0x00, 0x00, 0x00, 0x00, 0x00, 0x00, 0x00, 0x00, 0x00, 0x00,
  0x00, 0x00, 0x00, 0x00, 0x21, 0x24, 0xff, 0xff, 0xff, 0xff, 0xff, 0xff, 0xff, 0xff, 0xff, 0xff,
  0x52, 0xaa, 0x00, 0x00, 0x00, 0x00, 0x00, 0x00, 0x00, 0x00, 0x00, 0x00, 0xff, 0xff, 0xff, 0xff,
  0xff, 0xff, 0xff, 0xff, 0xff, 0xff, 0xde, 0xfb, 0x00, 0x00, 0x00, 0x00, 0x00, 0x00, 0x00, 0x00,
  0x00, 0x00, 0x00, 0x00, 0x00, 0x00, 0x00, 0x00, 0xff, 0xdf, 0xff, 0xff, 0xff, 0xff, 0x84, 0xb6,
  0x6c, 0x15, 0xff, 0xff, 0xff, 0xff, 0x00, 0x00, 0x00, 0x00, 0x08, 0x41, 0xff, 0xff, 0xff, 0xff,
  0xde, 0xfb, 0x00, 0x00, 0x00, 0x00, 0x00, 0x00, 0x00, 0x00, 0x00, 0x00, 0x00, 0x00, 0x00, 0x00,
  0x00, 0x00, 0xff, 0xdf, 0xff, 0xff, 0xff, 0xff, 0x00, 0x00, 0x00, 0x00, 0x18, 0xe3, 0xff, 0xff,
  0xff, 0xff, 0xff, 0xff, 0xff, 0xff, 0xff, 0xff, 0xff, 0xff, 0xff, 0xff, 0xff, 0xff, 0xff, 0xff,
  0xff, 0xff, 0xff, 0xff, 0x00, 0x20, 0x00, 0x00, 0x00, 0x00, 0x00, 0x00, 0x00, 0x00, 0x00, 0x00,
  0x00, 0x00, 0x00, 0x00, 0x94, 0xb2, 0xff, 0xff, 0xff, 0xff, 0xff, 0xff, 0xff, 0xff, 0xff, 0xff,
  0x00, 0x20, 0x00, 0x00, 0x00, 0x00, 0x00, 0x00, 0x00, 0x00, 0x08, 0x41, 0xff, 0xff, 0xff, 0xff,
  0xff, 0xff, 0xff, 0xff, 0xff, 0xff, 0x63, 0x0c, 0x00, 0x00, 0x00, 0x00, 0x00, 0x00, 0x00, 0x00,
  0x00, 0x00, 0x00, 0x00, 0x00, 0x00, 0x00, 0x00, 0x00, 0x00, 0x00, 0x00, 0x21, 0x24, 0xff, 0xff,
  0xff, 0xff, 0xff, 0xff, 0xff, 0xff, 0xff, 0xff, 0x52, 0xaa, 0x00, 0x00, 0x00, 0x00, 0x00, 0x00,
  0x00, 0x00, 0x00, 0x00, 0xff, 0xff, 0xff, 0xff, 0xff, 0xff, 0xff, 0xff, 0xff, 0xff, 0xde, 0xfb,
  0x00, 0x00, 0x00, 0x00, 0x00, 0x00, 0x00, 0x00, 0x00, 0x00, 0x00, 0x00, 0x00, 0x00, 0x00, 0x00,
  0xff, 0xdf, 0xff, 0xff, 0xff, 0xff, 0x84, 0xb6, 0x6c, 0x15, 0xff, 0xff, 0xff, 0xff, 0x00, 0x00,
  0x00, 0x00, 0x08, 0x41, 0xff, 0xff, 0xff, 0xff, 0xde, 0xfb, 0x00, 0x00, 0x00, 0x00, 0x00, 0x00,
  0x00, 0x00, 0x00, 0x00, 0x00, 0x00, 0x00, 0x00, 0x00, 0x00, 0xff, 0xdf, 0xff, 0xff, 0xff, 0xff,
  0x00, 0x00, 0x00, 0x00, 0x18, 0xe3, 0xff, 0xff, 0xff, 0xff, 0xff, 0xff, 0xff, 0xff, 0xff, 0xff,
  0xff, 0xff, 0xff, 0xff, 0xff, 0xff, 0xff, 0xff, 0xff, 0xff, 0xff, 0xff, 0x00, 0x20, 0x00, 0x00,
  0x00, 0x00, 0x00, 0x00, 0x00, 0x00, 0x00, 0x00, 0x00, 0x00, 0x00, 0x00, 0x9c, 0xd3, 0xff, 0xff,
  0xff, 0xff, 0xff, 0xff, 0xff, 0xff, 0xff, 0xff, 0x00, 0x20, 0x00, 0x00, 0x00, 0x00, 0x00, 0x00,
  0x00, 0x00, 0x08, 0x41, 0xff, 0xff, 0xff, 0xff, 0xff, 0xff, 0xff, 0xff, 0xff, 0xff, 0x63, 0x0c,
  0x00, 0x00, 0x00, 0x00, 0x00, 0x00, 0x00, 0x00, 0x00, 0x00, 0x00, 0x00, 0x00, 0x00, 0x00, 0x00,
  0x00, 0x00, 0x00, 0x00, 0x21, 0x24, 0xff, 0xff, 0xff, 0xff, 0xff, 0xff, 0xff, 0xff, 0xff, 0xff,
  0x52, 0xaa, 0x00, 0x00, 0x00, 0x00, 0x00, 0x00, 0x00, 0x00, 0x00, 0x00, 0xff, 0xff, 0xff, 0xff,
  0xff, 0xff, 0xff, 0xff, 0xff, 0xff, 0xde, 0xfb, 0x00, 0x00, 0x00, 0x00, 0x00, 0x00, 0x00, 0x00,
  0x00, 0x00, 0x00, 0x00, 0x00, 0x00, 0x00, 0x00, 0xff, 0xdf, 0xff, 0xff, 0xff, 0xff, 0x84, 0xb6,
  0x6c, 0x15, 0xff, 0xff, 0xff, 0xff, 0x00, 0x00, 0x00, 0x00, 0x08, 0x41, 0xff, 0xff, 0xff, 0xff,
  0xde, 0xfb, 0x00, 0x00, 0x00, 0x00, 0x00, 0x00, 0x00, 0x00, 0x00, 0x00, 0x00, 0x00, 0x00, 0x00,
  0x00, 0x00, 0xff, 0xdf, 0xff, 0xff, 0xff, 0xff, 0x00, 0x00, 0x00, 0x00, 0x18, 0xe3, 0xff, 0xff,
  0xff, 0xff, 0x8c, 0x51, 0x00, 0x00, 0x00, 0x00, 0x00, 0x00, 0x00, 0x00, 0x00, 0x00, 0xf7, 0x9e,
  0xff, 0xff, 0xff, 0xff, 0x00, 0x20, 0x00, 0x00, 0x00, 0x00, 0x00, 0x00, 0x00, 0x00, 0x10, 0xa2,
  0xff, 0xff, 0xff, 0xff, 0x63, 0x2c, 0x00, 0x00, 0x00, 0x00, 0xd6, 0x9a, 0xff, 0xff, 0xff, 0xff,
  0xff, 0xff, 0xff, 0xff, 0xff, 0xff, 0x00, 0x00, 0x00, 0x00, 0x00, 0x00, 0x00, 0x00, 0x00, 0x00,
  0x31, 0xa6, 0xff, 0xff, 0xff, 0xff, 0x63, 0x0c, 0x00, 0x00, 0x00, 0x00, 0xef, 0x5d, 0xff, 0xff,
  0xff, 0xff, 0x00, 0x00, 0x00, 0x00, 0x00, 0x00, 0x00, 0x00, 0x00, 0x00, 0x00, 0x00, 0x00, 0x00,
  0x00, 0x00, 0x6b, 0x6d, 0xff, 0xff, 0xff, 0xff, 0xff, 0xff, 0xff, 0xff, 0xff, 0xff, 0xff, 0xff,
  0xff, 0xff, 0xff, 0xff, 0xff, 0xff, 0xff, 0xff, 0xff, 0xff, 0xff, 0xff, 0xff, 0xff, 0xde, 0xfb,
  0x00, 0x00, 0x00, 0x00, 0xa5, 0x14, 0xff, 0xff, 0xff, 0xff, 0x29, 0x45, 0x00, 0x00, 0x00, 0x00,
  0xff, 0xdf, 0xff, 0xff, 0xff, 0xff, 0x84, 0xb6, 0x6c, 0x15, 0xff, 0xff, 0xff, 0xff, 0x00, 0x00,
  0x00, 0x00, 0x08, 0x41, 0xff, 0xff, 0xff, 0xff, 0xde, 0xfb, 0x00, 0x00, 0x00, 0x00, 0x00, 0x00,
  0x00, 0x00, 0x00, 0x00, 0x00, 0x00, 0x00, 0x00, 0x00, 0x00, 0xff, 0xdf, 0xff, 0xff, 0xff, 0xff,
  0x00, 0x00, 0x00, 0x00, 0x18, 0xe3, 0xff, 0xff, 0xff, 0xff, 0x8c, 0x51, 0x00, 0x00, 0x00, 0x00,
  0x00, 0x00, 0x00, 0x00, 0x00, 0x00, 0xf7, 0x9e, 0xff, 0xff, 0xff, 0xff, 0x00, 0x20, 0x00, 0x00,
  0x00, 0x00, 0x00, 0x00, 0x00, 0x00, 0x18, 0xc3, 0xff, 0xff, 0xff, 0xff, 0x63, 0x2c, 0x00, 0x00,
  0x00, 0x00, 0xd6, 0x9a, 0xff, 0xff, 0xff, 0xff, 0xff, 0xff, 0xff, 0xff, 0xff, 0xff, 0x00, 0x00,
  0x00, 0x00, 0x00, 0x00, 0x00, 0x00, 0x00, 0x00, 0x31, 0x86, 0xff, 0xff, 0xff, 0xff, 0x63, 0x0c,
  0x00, 0x00, 0x00, 0x00, 0xef, 0x5d, 0xff, 0xff, 0xff, 0xff, 0x00, 0x00, 0x00, 0x00, 0x00, 0x00,
  0x00, 0x00, 0x00, 0x00, 0x00, 0x00, 0x00, 0x00, 0x00, 0x00, 0x6b, 0x6d, 0xff, 0xff, 0xff, 0xff,
  0xff, 0xff, 0xff, 0xff, 0xff, 0xff, 0xff, 0xff, 0xff, 0xff, 0xff, 0xff, 0xff, 0xff, 0xff, 0xff,
  0xff, 0xff, 0xff, 0xff, 0xff, 0xff, 0xde, 0xfb, 0x00, 0x00, 0x00, 0x00, 0xa5, 0x34, 0xff, 0xff,
  0xff, 0xff, 0x29, 0x45, 0x00, 0x00, 0x00, 0x00, 0xff, 0xdf, 0xff, 0xff, 0xff, 0xff, 0x84, 0xb6,
  0x6c, 0x15, 0xff, 0xff, 0xff, 0xff, 0x00, 0x00, 0x00, 0x00, 0x08, 0x41, 0xff, 0xff, 0xff, 0xff,
  0xde, 0xfb, 0x00, 0x00, 0x00, 0x00, 0x00, 0x00, 0x00, 0x00, 0x00, 0x00, 0x00, 0x00, 0x00, 0x00,
  0x00, 0x00, 0xff, 0xdf, 0xff, 0xff, 0xff, 0xff, 0x00, 0x00, 0x00, 0x00, 0x18, 0xe3, 0xff, 0xff,
  0xff, 0xff, 0x8c, 0x51, 0x00, 0x00, 0x00, 0x00, 0x00, 0x00, 0x00, 0x00, 0x00, 0x00, 0xf7, 0x9e,
  0xff, 0xff, 0xff, 0xff, 0x00, 0x20, 0x00, 0x00, 0x00, 0x00, 0x00, 0x00, 0x00, 0x00, 0x18, 0xc3,
  0xff, 0xff, 0xff, 0xff, 0x63, 0x2c, 0x00, 0x00, 0x00, 0x00, 0xd6, 0x9a, 0xff, 0xff, 0xff, 0xff,
  0xff, 0xff, 0xff, 0xff, 0xff, 0xff, 0x00, 0x00, 0x00, 0x00, 0x00, 0x00, 0x00, 0x00, 0x00, 0x00,
  0x31, 0x86, 0xff, 0xff, 0xff, 0xff, 0x63, 0x0c, 0x00, 0x00, 0x00, 0x00, 0xef, 0x5d, 0xff, 0xff,
  0xff, 0xff, 0x00, 0x00, 0x00, 0x00, 0x00, 0x00, 0x00, 0x00, 0x00, 0x00, 0x00, 0x00, 0x00, 0x00,
  0x00, 0x00, 0x6b, 0x6d, 0xff, 0xff, 0xff, 0xff, 0xff, 0xff, 0xff, 0xff, 0xff, 0xff, 0xff, 0xff,
  0xff, 0xff, 0xff, 0xff, 0xff, 0xff, 0xff, 0xff, 0xff, 0xff, 0xff, 0xff, 0xff, 0xff, 0xde, 0xfb,
  0x00, 0x00, 0x00, 0x00, 0xa5, 0x34, 0xff, 0xff, 0xff, 0xff, 0x29, 0x45, 0x00, 0x00, 0x00, 0x00,
  0xff, 0xdf, 0xff, 0xff, 0xff, 0xff, 0x84, 0xb6, 0x6c, 0x15, 0xff, 0xff, 0xff, 0xff, 0x00, 0x00,
  0x00, 0x00, 0x08, 0x41, 0xff, 0xff, 0xff, 0xff, 0xff, 0xff, 0xff, 0xff, 0xff, 0xff, 0xff, 0xff,
  0xff, 0xff, 0xff, 0xff, 0xff, 0xff, 0xff, 0xff, 0xff, 0xff, 0xff, 0xff, 0xff, 0xff, 0xff, 0xff,
  0x00, 0x00, 0x00, 0x00, 0x18, 0xe3, 0xff, 0xff, 0xff, 0xff, 0x8c, 0x51, 0x00, 0x00, 0x00, 0x00,
  0x00, 0x00, 0x00, 0x00, 0x00, 0x00, 0x00, 0x00, 0x00, 0x00, 0x00, 0x00, 0xff, 0xdf, 0xff, 0xff,
  0xff, 0xff, 0x00, 0x00, 0x00, 0x00, 0x00, 0x00, 0x00, 0x00, 0x00, 0x00, 0x00, 0x00, 0x00, 0x00,
  0x00, 0x00, 0xd6, 0x9a, 0xff, 0xff, 0xff, 0xff, 0x00, 0x20, 0x00, 0x00, 0x00, 0x00, 0x00, 0x00,
  0x00, 0x00, 0x00, 0x00, 0x00, 0x00, 0x00, 0x00, 0x31, 0x86, 0xff, 0xff, 0xff, 0xff, 0x63, 0x0c,
  0x00, 0x00, 0x00, 0x00, 0xef, 0x5d, 0xff, 0xff, 0xff, 0xff, 0x00, 0x00, 0x00, 0x00, 0x00, 0x00,
  0x00, 0x00, 0x00, 0x00, 0x21, 0x24, 0xff, 0xff, 0xff, 0xff, 0x8c, 0x71, 0x00, 0x00, 0x00, 0x00,
  0xad, 0x55, 0xff, 0xff, 0xff, 0xff, 0x08, 0x61, 0x00, 0x00, 0x00, 0x00, 0x00, 0x00, 0x00, 0x00,
  0x08, 0x41, 0xff, 0xff, 0xff, 0xff, 0xff, 0xff, 0xff, 0xff, 0xff, 0xff, 0x5a, 0xcb, 0x00, 0x00,
  0x00, 0x00, 0x00, 0x00, 0x00, 0x00, 0x00, 0x00, 0xff, 0xdf, 0xff, 0xff, 0xff, 0xff, 0x84, 0xb6,
  0x6c, 0x15, 0xff, 0xff, 0xff, 0xff, 0x00, 0x00, 0x00, 0x00, 0x08, 0x41, 0xff, 0xff, 0xff, 0xff,
  0xff, 0xff, 0xff, 0xff, 0xff, 0xff, 0xff, 0xff, 0xff, 0xff, 0xff, 0xff, 0xff, 0xff, 0xff, 0xff,
  0xff, 0xff, 0xff, 0xff, 0xff, 0xff, 0xff, 0xff, 0x00, 0x00, 0x00, 0x00, 0x18, 0xe3, 0xff, 0xff,
  0xff, 0xff, 0x8c, 0x51, 0x00, 0x00, 0x00, 0x00, 0x00, 0x00, 0x00, 0x00, 0x00, 0x00, 0x00, 0x00,
  0x00, 0x00, 0x00, 0x00, 0xff, 0xdf, 0xff, 0xff, 0xff, 0xff, 0x00, 0x00, 0x00, 0x00, 0x00, 0x00,
  0x00, 0x00, 0x00, 0x00, 0x00, 0x00, 0x00, 0x00, 0x00, 0x00, 0xd6, 0x9a, 0xff, 0xff, 0xff, 0xff,
  0x00, 0x20, 0x00, 0x00, 0x00, 0x00, 0x00, 0x00, 0x00, 0x00, 0x00, 0x00, 0x00, 0x00, 0x00, 0x00,
  0x31, 0x86, 0xff, 0xff, 0xff, 0xff, 0x63, 0x0c, 0x00, 0x00, 0x00, 0x00, 0xef, 0x5d, 0xff, 0xff,
  0xff, 0xff, 0x00, 0x00, 0x00, 0x00, 0x00, 0x00, 0x00, 0x00, 0x00, 0x00, 0x21, 0x24, 0xff, 0xff,
  0xff, 0xff, 0x8c, 0x71, 0x00, 0x00, 0x00, 0x00, 0xad, 0x55, 0xff, 0xff, 0xff, 0xff, 0x08, 0x61,
  0x00, 0x00, 0x00, 0x00, 0x00, 0x00, 0x00, 0x00, 0x08, 0x41, 0xff, 0xff, 0xff, 0xff, 0xff, 0xff,
  0xff, 0xff, 0xff, 0xff, 0x5a, 0xcb, 0x00, 0x00, 0x00, 0x00, 0x00, 0x00, 0x00, 0x00, 0x00, 0x00,
  0xff, 0xdf, 0xff, 0xff, 0xff, 0xff, 0x84, 0xb6, 0x6c, 0x15, 0xff, 0xff, 0xff, 0xff, 0x00, 0x00,
  0x00, 0x00, 0x00, 0x20, 0xb5, 0xb6, 0xb5, 0xb6, 0xb5, 0xb6, 0xb5, 0xb6, 0xb5, 0xb6, 0xb5, 0xb6,
  0xb5, 0xb6, 0xb5, 0xb6, 0xb5, 0xb6, 0xb5, 0xb6, 0xb5, 0xb6, 0xb5, 0xb6, 0xb5, 0xb6, 0xb5, 0xb6,
  0x00, 0x00, 0x00, 0x00, 0x18, 0xe3, 0xff, 0xff, 0xff, 0xff, 0x8c, 0x51, 0x00, 0x00, 0x00, 0x00,
  0x29, 0x65, 0x4a, 0x49, 0x4a, 0x49, 0x4a, 0x49, 0x4a, 0x49, 0x4a, 0x49, 0xb5, 0xb6, 0xb5, 0xb6,
  0xb5, 0xb6, 0x4a, 0x49, 0x4a, 0x49, 0x4a, 0x49, 0x4a, 0x49, 0x4a, 0x49, 0x18, 0xe3, 0x00, 0x00,
  0x00, 0x00, 0xd6, 0x9a, 0xff, 0xff, 0xff, 0xff, 0x00, 0x20, 0x00, 0x00, 0x00, 0x00, 0x00, 0x00,
  0x00, 0x00, 0x00, 0x00, 0x00, 0x00, 0x00, 0x00, 0x21, 0x04, 0xb5, 0xb6, 0xb5, 0xb6, 0x42, 0x28,
  0x00, 0x00, 0x00, 0x00, 0xef, 0x5d, 0xff, 0xff, 0xff, 0xff, 0x4a, 0x49, 0x4a, 0x49, 0x4a, 0x49,
  0x4a, 0x49, 0x4a, 0x49, 0x63, 0x0c, 0xff, 0xff, 0xff, 0xff, 0x8c, 0x71, 0x00, 0x00, 0x00, 0x00,
  0x7b, 0xcf, 0xb5, 0xb6, 0xb5, 0xb6, 0x4a, 0x69, 0x4a, 0x49, 0x4a, 0x49, 0x00, 0x00, 0x00, 0x00,
  0x00, 0x20, 0xb5, 0xb6, 0xb5, 0xb6, 0xbd, 0xf7, 0xff, 0xff, 0xff, 0xff, 0x84, 0x30, 0x4a, 0x49,
  0x4a, 0x49, 0x08, 0x41, 0x00, 0x00, 0x00, 0x00, 0xff, 0xdf, 0xff, 0xff, 0xff, 0xff, 0x84, 0xb6,
  0x6c, 0x15, 0xff, 0xff, 0xff, 0xff, 0x00, 0x00, 0x00, 0x00, 0x00, 0x00, 0x00, 0x00, 0x00, 0x00,
  0x00, 0x00, 0x00, 0x00, 0x00, 0x00, 0x00, 0x00, 0x00, 0x00, 0x00, 0x00, 0x00, 0x00, 0x00, 0x00,
  0x00, 0x00, 0x00, 0x00, 0x00, 0x00, 0x00, 0x00, 0x00, 0x00, 0x00, 0x00, 0x18, 0xe3, 0xff, 0xff,
  0xff, 0xff, 0x8c, 0x51, 0x00, 0x00, 0x00, 0x00, 0x9c, 0xf3, 0xff, 0xff, 0xff, 0xff, 0xff, 0xff,
  0xff, 0xff, 0xff, 0xff, 0x00, 0x20, 0x00, 0x00, 0x00, 0x00, 0xff, 0xff, 0xff, 0xff, 0xff, 0xff,
  0xff, 0xff, 0xff, 0xff, 0x63, 0x2c, 0x00, 0x00, 0x00, 0x00, 0xd6, 0x9a, 0xff, 0xff, 0xff, 0xff,
  0x00, 0x20, 0x00, 0x00, 0x00, 0x00, 0x00, 0x00, 0x00, 0x00, 0x00, 0x00, 0x00, 0x00, 0x00, 0x00,
  0x00, 0x00, 0x00, 0x00, 0x00, 0x00, 0x00, 0x00, 0x00, 0x00, 0x00, 0x00, 0xef, 0x5d, 0xff, 0xff,
  0xff, 0xff, 0xff, 0xff, 0xff, 0xff, 0xff, 0xff, 0xff, 0xff, 0xff, 0xff, 0xff, 0xff, 0xff, 0xff,
  0xff, 0xff, 0x8c, 0x71, 0x00, 0x00, 0x00, 0x00, 0x00, 0x00, 0x00, 0x00, 0x00, 0x00, 0xf7, 0x9e,
  0xff, 0xff, 0xff, 0xff, 0x00, 0x00, 0x00, 0x00, 0x00, 0x00, 0x00, 0x00, 0x00, 0x00, 0x21, 0x04,
  0xff, 0xff, 0xff, 0xff, 0xff, 0xff, 0xff, 0xff, 0xff, 0xff, 0x29, 0x45, 0x00, 0x00, 0x00, 0x00,
  0xff, 0xdf, 0xff, 0xff, 0xff, 0xff, 0x84, 0xb6, 0x6c, 0x15, 0xff, 0xff, 0xff, 0xff, 0x00, 0x00,
  0x00, 0x00, 0x00, 0x00, 0x00, 0x00, 0x00, 0x00, 0x00, 0x00, 0x00, 0x00, 0x00, 0x00, 0x00, 0x00,
  0x00, 0x00, 0x00, 0x00, 0x00, 0x00, 0x00, 0x00, 0x00, 0x00, 0x00, 0x00, 0x00, 0x00, 0x00, 0x00,
  0x00, 0x00, 0x00, 0x00, 0x18, 0xe3, 0xff, 0xff, 0xff, 0xff, 0x8c, 0x51, 0x00, 0x00, 0x00, 0x00,
  0x9c, 0xf3, 0xff, 0xff, 0xff, 0xff, 0xff, 0xff, 0xff, 0xff, 0xff, 0xff, 0x00, 0x20, 0x00, 0x00,
  0x00, 0x00, 0xff, 0xff, 0xff, 0xff, 0xff, 0xff, 0xff, 0xff, 0xff, 0xff, 0x63, 0x2c, 0x00, 0x00,
  0x00, 0x00, 0xd6, 0x9a, 0xff, 0xff, 0xff, 0xff, 0x00, 0x20, 0x00, 0x00, 0x00, 0x00, 0x00, 0x00,
  0x00, 0x00, 0x00, 0x00, 0x00, 0x00, 0x00, 0x00, 0x00, 0x00, 0x00, 0x00, 0x00, 0x00, 0x00, 0x00,
  0x00, 0x00, 0x00, 0x00, 0xef, 0x5d, 0xff, 0xff, 0xff, 0xff, 0xff, 0xff, 0xff, 0xff, 0xff, 0xff,
  0xff, 0xff, 0xff, 0xff, 0xff, 0xff, 0xff, 0xff, 0xff, 0xff, 0x8c, 0x71, 0x00, 0x00, 0x00, 0x00,
  0x00, 0x00, 0x00, 0x00, 0x00, 0x00, 0xf7, 0x9e, 0xff, 0xff, 0xff, 0xff, 0x00, 0x00, 0x00, 0x00,
  0x00, 0x00, 0x00, 0x00, 0x00, 0x00, 0x21, 0x04, 0xff, 0xff, 0xff, 0xff, 0xff, 0xff, 0xff, 0xff,
  0xff, 0xff, 0x29, 0x45, 0x00, 0x00, 0x00, 0x00, 0xff, 0xdf, 0xff, 0xff, 0xff, 0xff, 0x84, 0xb6,
  0x6c, 0x15, 0xff, 0xff, 0xff, 0xff, 0xd6, 0x9a, 0xd6, 0x9a, 0xd6, 0x9a, 0xd6, 0x9a, 0xd6, 0x9a,
  0xd6, 0x9a, 0xd6, 0x9a, 0xd6, 0x9a, 0xd6, 0x9a, 0xd6, 0x9a, 0xd6, 0x9a, 0xd6, 0x9a, 0xd6, 0x9a,
  0xd6, 0x9a, 0xd6, 0x9a, 0xd6, 0x9a, 0xd6, 0x9a, 0xd6, 0x9a, 0xd6, 0x9a, 0xd6, 0xba, 0xff, 0xff,
  0xff, 0xff, 0xef, 0x5d, 0xd6, 0x9a, 0xd6, 0x9a, 0xef, 0x7d, 0xff, 0xff, 0xff, 0xff, 0xff, 0xff,
  0xff, 0xff, 0xff, 0xff, 0xd6, 0x9a, 0xd6, 0x9a, 0xd6, 0x9a, 0xff, 0xff, 0xff, 0xff, 0xff, 0xff,
  0xff, 0xff, 0xff, 0xff, 0xe7, 0x3c, 0xd6, 0x9a, 0xd6, 0x9a, 0xf7, 0xbe, 0xff, 0xff, 0xff, 0xff,
  0xd6, 0x9a, 0xd6, 0x9a, 0xd6, 0x9a, 0xd6, 0x9a, 0xd6, 0x9a, 0xd6, 0x9a, 0xd6, 0x9a, 0xd6, 0x9a,
  0xd6, 0x9a, 0xd6, 0x9a, 0xd6, 0x9a, 0xd6, 0x9a, 0xd6, 0x9a, 0xd6, 0x9a, 0xff, 0xdf, 0xff, 0xff,
  0xff, 0xff, 0xff, 0xff, 0xff, 0xff, 0xff, 0xff, 0xff, 0xff, 0xff, 0xff, 0xff, 0xff, 0xff, 0xff,
  0xff, 0xff, 0xef, 0x5d, 0xd6, 0x9a, 0xd6, 0x9a, 0xd6, 0x9a, 0xd6, 0x9a, 0xd6, 0x9a, 0xff, 0xdf,
  0xff, 0xff, 0xff, 0xff, 0xd6, 0x9a, 0xd6, 0x9a, 0xd6, 0x9a, 0xd6, 0x9a, 0xd6, 0x9a, 0xde, 0xdb,
  0xff, 0xff, 0xff, 0xff, 0xff, 0xff, 0xff, 0xff, 0xff, 0xff, 0xde, 0xdb, 0xd6, 0x9a, 0xd6, 0x9a,
  0xff, 0xff, 0xff, 0xff, 0xff, 0xff, 0x84, 0xb6, 0x6c, 0x15, 0xff, 0xff, 0xff, 0xff, 0xff, 0xff,
  0xff, 0xff, 0xff, 0xff, 0xff, 0xff, 0xff, 0xff, 0xff, 0xff, 0xff, 0xff, 0xff, 0xff, 0xff, 0xff,
  0xff, 0xff, 0xff, 0xff, 0xff, 0xff, 0xff, 0xff, 0xff, 0xff, 0xff, 0xff, 0xff, 0xff, 0xff, 0xff,
  0xff, 0xff, 0xff, 0xff, 0xff, 0xff, 0xff, 0xff, 0xff, 0xff, 0xff, 0xff, 0xff, 0xff, 0xff, 0xff,
  0xff, 0xff, 0xff, 0xff, 0xff, 0xff, 0xff, 0xff, 0xff, 0xff, 0xff, 0xff, 0xff, 0xff, 0xff, 0xff,
  0xff, 0xff, 0xff, 0xff, 0xff, 0xff, 0xff, 0xff, 0xff, 0xff, 0xff, 0xff, 0xff, 0xff, 0xff, 0xff,
  0xff, 0xff, 0xff, 0xff, 0xff, 0xff, 0xff, 0xff, 0xff, 0xff, 0xff, 0xff, 0xff, 0xff, 0xff, 0xff,
  0xff, 0xff, 0xff, 0xff, 0xff, 0xff, 0xff, 0xff, 0xff, 0xff, 0xff, 0xff, 0xff, 0xff, 0xff, 0xff,
  0xff, 0xff, 0xff, 0xff, 0xff, 0xff, 0xff, 0xff, 0xff, 0xff, 0xff, 0xff, 0xff, 0xff, 0xff, 0xff,
  0xff, 0xff, 0xff, 0xff, 0xff, 0xff, 0xff, 0xff, 0xff, 0xff, 0xff, 0xff, 0xff, 0xff, 0xff, 0xff,
  0xff, 0xff, 0xff, 0xff, 0xff, 0xff, 0xff, 0xff, 0xff, 0xff, 0xff, 0xff, 0xff, 0xff, 0xff, 0xff,
  0xff, 0xff, 0xff, 0xff, 0xff, 0xff, 0xff, 0xff, 0xff, 0xff, 0xff, 0xff, 0xff, 0xff, 0xff, 0xff,
  0xff, 0xff, 0xff, 0xff, 0xff, 0xff, 0xff, 0xff, 0xff, 0xff, 0xff, 0xff, 0xff, 0xff, 0x84, 0xb6,
  0x6c, 0x15, 0xff, 0xff, 0xff, 0xff, 0xff, 0xff, 0xff, 0xff, 0xff, 0xff, 0xff, 0xff, 0xff, 0xff,
  0xff, 0xff, 0xff, 0xff, 0xff, 0xff, 0xff, 0xff, 0xff, 0xff, 0xff, 0xff, 0xff, 0xff, 0xff, 0xff,
  0xff, 0xff, 0xff, 0xff, 0xff, 0xff, 0xff, 0xff, 0xff, 0xff, 0xff, 0xff, 0xff, 0xff, 0xff, 0xff,
  0xff, 0xff, 0xff, 0xff, 0xff, 0xff, 0xff, 0xff, 0xff, 0xff, 0xff, 0xff, 0xff, 0xff, 0xff, 0xff,
  0xff, 0xff, 0xff, 0xff, 0xff, 0xff, 0xff, 0xff, 0xff, 0xff, 0xff, 0xff, 0xff, 0xff, 0xff, 0xff,
  0xff, 0xff, 0xff, 0xff, 0xff, 0xff, 0xff, 0xff, 0xff, 0xff, 0xff, 0xff, 0xff, 0xff, 0xff, 0xff,
  0xff, 0xff, 0xff, 0xff, 0xff, 0xff, 0xff, 0xff, 0xff, 0xff, 0xff, 0xff, 0xff, 0xff, 0xff, 0xff,
  0xff, 0xff, 0xff, 0xff, 0xff, 0xff, 0xff, 0xff, 0xff, 0xff, 0xff, 0xff, 0xff, 0xff, 0xff, 0xff,
  0xff, 0xff, 0xff, 0xff, 0xff, 0xff, 0xff, 0xff, 0xff, 0xff, 0xff, 0xff, 0xff, 0xff, 0xff, 0xff,
  0xff, 0xff, 0xff, 0xff, 0xff, 0xff, 0xff, 0xff, 0xff, 0xff, 0xff, 0xff, 0xff, 0xff, 0xff, 0xff,
  0xff, 0xff, 0xff, 0xff, 0xff, 0xff, 0xff, 0xff, 0xff, 0xff, 0xff, 0xff, 0xff, 0xff, 0xff, 0xff,
  0xff, 0xff, 0xff, 0xff, 0xff, 0xff, 0xff, 0xff, 0xff, 0xff, 0xff, 0xff, 0xff, 0xff, 0xff, 0xff,
  0xff, 0xff, 0xff, 0xff, 0xff, 0xff, 0x84, 0xb6, 0x22, 0x2f, 0x32, 0x90, 0x32, 0x90, 0x32, 0x90,
  0x32, 0x90, 0x32, 0x90, 0x32, 0x90, 0x32, 0x90, 0x32, 0x90, 0x32, 0x90, 0x32, 0x90, 0x32, 0x90,
  0x32, 0x90, 0x32, 0x90, 0x32, 0x90, 0x32, 0x90, 0x32, 0x90, 0x32, 0x90, 0x32, 0x90, 0x32, 0x90,
  0x32, 0x90, 0x32, 0x90, 0x32, 0x90, 0x32, 0x90, 0x32, 0x90, 0x32, 0x90, 0x32, 0x90, 0x32, 0x90,
  0x32, 0x90, 0x32, 0x90, 0x32, 0x90, 0x32, 0x90, 0x32, 0x90, 0x32, 0x90, 0x32, 0x90, 0x32, 0x90,
  0x32, 0x90, 0x32, 0x90, 0x32, 0x90, 0x32, 0x90, 0x32, 0x90, 0x32, 0x90, 0x32, 0x90, 0x32, 0x90,
  0x32, 0x90, 0x32, 0x90, 0x32, 0x90, 0x32, 0x90, 0x32, 0x90, 0x32, 0x90, 0x32, 0x90, 0x32, 0x90,
  0x32, 0x90, 0x32, 0x90, 0x32, 0x90, 0x32, 0x90, 0x32, 0x90, 0x32, 0x90, 0x32, 0x90, 0x32, 0x90,
  0x32, 0x90, 0x32, 0x90, 0x32, 0x90, 0x32, 0x90, 0x32, 0x90, 0x32, 0x90, 0x32, 0x90, 0x32, 0x90,
  0x32, 0x90, 0x32, 0x90, 0x32, 0x90, 0x32, 0x90, 0x32, 0x90, 0x32, 0x90, 0x32, 0x90, 0x32, 0x90,
  0x32, 0x90, 0x32, 0x90, 0x32, 0x90, 0x32, 0x90, 0x32, 0x90, 0x32, 0x90, 0x32, 0x90, 0x32, 0x90,
  0x32, 0x90, 0x32, 0x90, 0x32, 0x90, 0x32, 0x90, 0x32, 0x90, 0x32, 0x90, 0x32, 0x90, 0x32, 0x90,
  0x32, 0x90, 0x32, 0x90, 0x32, 0x90, 0x32, 0x90, 0x32, 0x90, 0x32, 0x90, 0x32, 0x90, 0x8c, 0xd7,
};

uint16_t String_Length(const char* str) {
    uint16_t length = 0;
    while (str[length] != '\0') {
        length++;
    }
    return length;
}

void Test_1(void){
	char *string = "Hello STM32F103XX";
	uint16_t len = String_Length(string);
	uint8_t centerX = (128 - 7 * len)/2;
	uint8_t centerY = (160 / 2) - (10 / 2);
	uint8_t startX = 10;
	uint8_t startY = 10;
	char num_buf[10];
	uint8_t count = 0;

	for (uint8_t i = 0; i < 10; i++) {
		uint8_t currentY = startY + (i * 14);
		for (uint8_t j = 0; j < 5; j++) {
			uint8_t currentX = startX + (j * 22);
			uint8_t val = (j * 10) + i;
			snprintf(num_buf, sizeof(num_buf), "%d", val);
			DrawString(currentX, currentY, num_buf, 0xFFFF, 0x0000);
		}
	}
}

void Test_2(void){
	char num_buf[1000];
	uint32_t count = 0;
	uint8_t centerX = 0;
	uint8_t centerY = 0;
	for (uint32_t i = 1; i <= 4294967295; i++){
		snprintf(num_buf, sizeof(num_buf), "%d", count ++);
		uint32_t len = String_Length(num_buf);
		centerX = (128 - 7 * len)/2;
		centerY = (160 / 2) - (10 / 2);
		DrawString(centerX, centerY, num_buf, 0xFFFF, 0x0000);
		HAL_Delay(1000);
	}
}

void Display_QR(const uint8_t *image, uint8_t size){
	uint16_t len = 0;
	uint8_t centerX = 0;
	uint8_t imgX = (128 - size) / 2;
	uint8_t imgY = (160 - size) / 2;
	HAL_Delay(100);

	DrawImage(imgX, imgY, size, size, image);

	char *nh = "TECHCOMBANK";
	len = String_Length(nh);
	centerX = (128 - 7 * len)/2;
	DrawString(centerX, 16, nh, 0xFFFF, 0x0000);

	char *ten = "PHAM HOANG HIEP";
	len = String_Length(ten);
	centerX = (128 - 7 * len)/2;
	DrawString(centerX, 134, ten, 0xFFFF, 0x0000);

	char *stk = "6556999999";
	len = String_Length(stk);
	centerX = (128 - 7 * len)/2;
	DrawString(centerX, 148, stk, 0xFFFF, 0x0000);
}

/* USER CODE END 0 */

int main(void)
{

  /* MCU Configuration--------------------------------------------------------*/

  /* Reset of all peripherals, Initializes the Flash interface and the Systick. */
  HAL_Init();

  /* Configure the system clock */
  SystemClock_Config();

  /* Initialize all configured peripherals */
  MX_GPIO_Init();
  MX_DMA_Init();
  MX_SPI1_Init();
  /* USER CODE BEGIN 2 */

	ST7735_Cfg_t mTft = {
		.hspi = &hspi1,
		.CS_Pin = GPIO_PIN_0,
		.CS_Port = GPIOB,
		.RS_Pin = GPIO_PIN_10,
		.RS_Port = GPIOB,
		.DC_Pin = GPIO_PIN_1,
		.DC_Port = GPIOB
	};

	LCD_Init(&mTft);

	HAL_GPIO_WritePin(GPIOB, GPIO_PIN_0, 1);
	HAL_GPIO_WritePin(GPIOA, GPIO_PIN_4, 0);
	FullDisplay(0x0000);
	HAL_GPIO_WritePin(GPIOA, GPIO_PIN_4, 1);

  /* USER CODE END 2 */

  /* Infinite loop */
  /* USER CODE BEGIN WHILE */

	// Display_QR(IMAGE, 100);
	 Test_2();
  while (1){

    /* USER CODE END WHILE */

  }
}

void SystemClock_Config(void)
{
  RCC_OscInitTypeDef RCC_OscInitStruct = {0};
  RCC_ClkInitTypeDef RCC_ClkInitStruct = {0};

  /** Initializes the RCC Oscillators according to the specified parameters
  * in the RCC_OscInitTypeDef structure.
  */
  RCC_OscInitStruct.OscillatorType = RCC_OSCILLATORTYPE_HSE;
  RCC_OscInitStruct.HSEState = RCC_HSE_ON;
  RCC_OscInitStruct.HSEPredivValue = RCC_HSE_PREDIV_DIV1;
  RCC_OscInitStruct.HSIState = RCC_HSI_ON;
  RCC_OscInitStruct.PLL.PLLState = RCC_PLL_ON;
  RCC_OscInitStruct.PLL.PLLSource = RCC_PLLSOURCE_HSE;
  RCC_OscInitStruct.PLL.PLLMUL = RCC_PLL_MUL9;
  if (HAL_RCC_OscConfig(&RCC_OscInitStruct) != HAL_OK)
  {
    Error_Handler();
  }

  /** Initializes the CPU, AHB and APB buses clocks
  */
  RCC_ClkInitStruct.ClockType = RCC_CLOCKTYPE_HCLK|RCC_CLOCKTYPE_SYSCLK
                              |RCC_CLOCKTYPE_PCLK1|RCC_CLOCKTYPE_PCLK2;
  RCC_ClkInitStruct.SYSCLKSource = RCC_SYSCLKSOURCE_PLLCLK;
  RCC_ClkInitStruct.AHBCLKDivider = RCC_SYSCLK_DIV1;
  RCC_ClkInitStruct.APB1CLKDivider = RCC_HCLK_DIV2;
  RCC_ClkInitStruct.APB2CLKDivider = RCC_HCLK_DIV1;

  if (HAL_RCC_ClockConfig(&RCC_ClkInitStruct, FLASH_LATENCY_2) != HAL_OK)
  {
    Error_Handler();
  }
}

static void MX_SPI1_Init(void)
{

  /* SPI1 parameter configuration*/
  hspi1.Instance = SPI1;
  hspi1.Init.Mode = SPI_MODE_MASTER;
  hspi1.Init.Direction = SPI_DIRECTION_2LINES;
  hspi1.Init.DataSize = SPI_DATASIZE_8BIT;
  hspi1.Init.CLKPolarity = SPI_POLARITY_LOW;
  hspi1.Init.CLKPhase = SPI_PHASE_1EDGE;
  hspi1.Init.NSS = SPI_NSS_SOFT;
  hspi1.Init.BaudRatePrescaler = SPI_BAUDRATEPRESCALER_4;
  hspi1.Init.FirstBit = SPI_FIRSTBIT_MSB;
  hspi1.Init.TIMode = SPI_TIMODE_DISABLE;
  hspi1.Init.CRCCalculation = SPI_CRCCALCULATION_DISABLE;
  hspi1.Init.CRCPolynomial = 10;
  if (HAL_SPI_Init(&hspi1) != HAL_OK)
  {
    Error_Handler();
  }

}

static void MX_DMA_Init(void)
{

  /* DMA controller clock enable */
  __HAL_RCC_DMA1_CLK_ENABLE();

  /* DMA interrupt init */
  /* DMA1_Channel3_IRQn interrupt configuration */
  HAL_NVIC_SetPriority(DMA1_Channel3_IRQn, 0, 0);
  HAL_NVIC_EnableIRQ(DMA1_Channel3_IRQn);

}

static void MX_GPIO_Init(void)
{
  GPIO_InitTypeDef GPIO_InitStruct = {0};

  /* GPIO Ports Clock Enable */
  __HAL_RCC_GPIOC_CLK_ENABLE();
  __HAL_RCC_GPIOD_CLK_ENABLE();
  __HAL_RCC_GPIOA_CLK_ENABLE();
  __HAL_RCC_GPIOB_CLK_ENABLE();

  /*Configure GPIO pin Output Level */
  HAL_GPIO_WritePin(GPIOA, GPIO_PIN_4, GPIO_PIN_RESET);

  /*Configure GPIO pin Output Level */
  HAL_GPIO_WritePin(GPIOB, GPIO_PIN_0|GPIO_PIN_1|GPIO_PIN_10, GPIO_PIN_RESET);

  /*Configure GPIO pin : PA4 */
  GPIO_InitStruct.Pin = GPIO_PIN_4;
  GPIO_InitStruct.Mode = GPIO_MODE_OUTPUT_PP;
  GPIO_InitStruct.Pull = GPIO_NOPULL;
  GPIO_InitStruct.Speed = GPIO_SPEED_FREQ_LOW;
  HAL_GPIO_Init(GPIOA, &GPIO_InitStruct);

  /*Configure GPIO pins : PB0 PB1 PB10 */
  GPIO_InitStruct.Pin = GPIO_PIN_0|GPIO_PIN_1|GPIO_PIN_10;
  GPIO_InitStruct.Mode = GPIO_MODE_OUTPUT_PP;
  GPIO_InitStruct.Pull = GPIO_NOPULL;
  GPIO_InitStruct.Speed = GPIO_SPEED_FREQ_LOW;
  HAL_GPIO_Init(GPIOB, &GPIO_InitStruct);

}

void Error_Handler(void)
{
  __disable_irq();
  while (1)
  {
  }
}
